VERSION "created by canmatrix"

NS_ :

BS_:

BU_: XCP_Tester FRS MN_K77

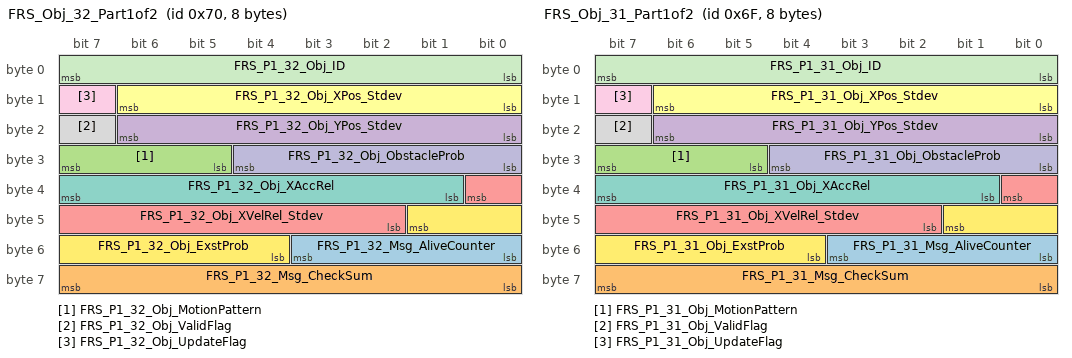
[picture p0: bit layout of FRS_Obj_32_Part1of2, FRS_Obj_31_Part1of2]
BO_ 112 FRS_Obj_32_Part1of2: 8 FRS
 SG_ FRS_P1_32_Msg_AliveCounter : 51|4@0+ (1,0) [0|15] "n/a" Vector__XXX
 SG_ FRS_P1_32_Msg_CheckSum : 63|8@0+ (1,0) [0|255] "n/a" Vector__XXX
 SG_ FRS_P1_32_Obj_MotionPattern : 31|3@0+ (1,0) [0|7] "n/a" Vector__XXX
 SG_ FRS_P1_32_Obj_YPos_Stdev : 22|7@0+ (0.1,0) [0|12.7] "m" Vector__XXX
 SG_ FRS_P1_32_Obj_XVelRel_Stdev : 32|7@0+ (0.05,0) [0|6.35] "m/s" Vector__XXX
 SG_ FRS_P1_32_Obj_XPos_Stdev : 14|7@0+ (0.1,0) [0|12.7] "m" Vector__XXX
 SG_ FRS_P1_32_Obj_XAccRel : 39|7@0+ (0.15,-9.6) [-9.6|9.45] "m/s2" Vector__XXX
 SG_ FRS_P1_32_Obj_ValidFlag : 23|1@0+ (1,0) [0|1] "n/a" Vector__XXX
 SG_ FRS_P1_32_Obj_UpdateFlag : 15|1@0+ (1,0) [0|1] "n/a" Vector__XXX
 SG_ FRS_P1_32_Obj_ObstacleProb : 28|5@0+ (3.2258,0) [0|99.9998] "%" Vector__XXX
 SG_ FRS_P1_32_Obj_ID : 7|8@0+ (1,0) [0|255] "n/a" Vector__XXX
 SG_ FRS_P1_32_Obj_ExstProb : 41|6@0+ (1.5873,0) [0|99.9999] "%" Vector__XXX

BO_ 111 FRS_Obj_31_Part1of2: 8 FRS
 SG_ FRS_P1_31_Msg_AliveCounter : 51|4@0+ (1,0) [0|15] "n/a" Vector__XXX
 SG_ FRS_P1_31_Msg_CheckSum : 63|8@0+ (1,0) [0|255] "n/a" Vector__XXX
 SG_ FRS_P1_31_Obj_MotionPattern : 31|3@0+ (1,0) [0|7] "n/a" Vector__XXX
 SG_ FRS_P1_31_Obj_YPos_Stdev : 22|7@0+ (0.1,0) [0|12.7] "m" Vector__XXX
 SG_ FRS_P1_31_Obj_XVelRel_Stdev : 32|7@0+ (0.05,0) [0|6.35] "m/s" Vector__XXX
 SG_ FRS_P1_31_Obj_XPos_Stdev : 14|7@0+ (0.1,0) [0|12.7] "m" Vector__XXX
 SG_ FRS_P1_31_Obj_XAccRel : 39|7@0+ (0.15,-9.6) [-9.6|9.45] "m/s2" Vector__XXX
 SG_ FRS_P1_31_Obj_ValidFlag : 23|1@0+ (1,0) [0|1] "n/a" Vector__XXX
 SG_ FRS_P1_31_Obj_UpdateFlag : 15|1@0+ (1,0) [0|1] "n/a" Vector__XXX
 SG_ FRS_P1_31_Obj_ObstacleProb : 28|5@0+ (3.2258,0) [0|99.9998] "%" Vector__XXX
 SG_ FRS_P1_31_Obj_ID : 7|8@0+ (1,0) [0|255] "n/a" Vector__XXX
 SG_ FRS_P1_31_Obj_ExstProb : 41|6@0+ (1.5873,0) [0|99.9999] "%" Vector__XXX

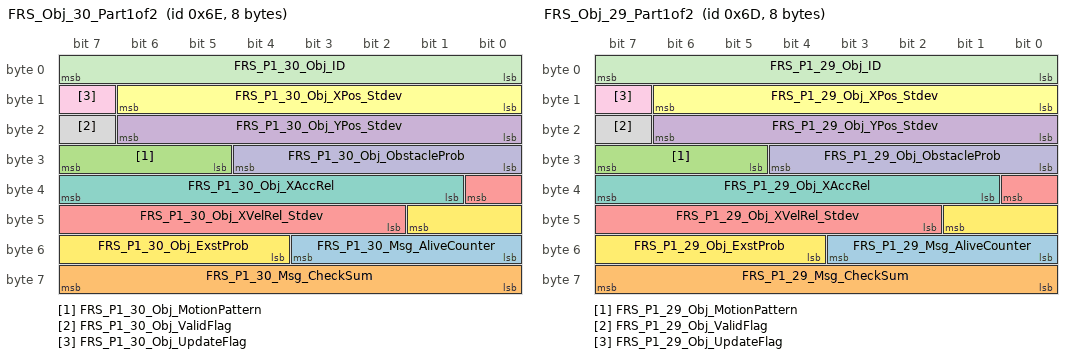
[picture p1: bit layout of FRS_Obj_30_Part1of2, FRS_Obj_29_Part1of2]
BO_ 110 FRS_Obj_30_Part1of2: 8 FRS
 SG_ FRS_P1_30_Msg_AliveCounter : 51|4@0+ (1,0) [0|15] "n/a" Vector__XXX
 SG_ FRS_P1_30_Msg_CheckSum : 63|8@0+ (1,0) [0|255] "n/a" Vector__XXX
 SG_ FRS_P1_30_Obj_MotionPattern : 31|3@0+ (1,0) [0|7] "n/a" Vector__XXX
 SG_ FRS_P1_30_Obj_YPos_Stdev : 22|7@0+ (0.1,0) [0|12.7] "m" Vector__XXX
 SG_ FRS_P1_30_Obj_XVelRel_Stdev : 32|7@0+ (0.05,0) [0|6.35] "m/s" Vector__XXX
 SG_ FRS_P1_30_Obj_XPos_Stdev : 14|7@0+ (0.1,0) [0|12.7] "m" Vector__XXX
 SG_ FRS_P1_30_Obj_XAccRel : 39|7@0+ (0.15,-9.6) [-9.6|9.45] "m/s2" Vector__XXX
 SG_ FRS_P1_30_Obj_ValidFlag : 23|1@0+ (1,0) [0|1] "n/a" Vector__XXX
 SG_ FRS_P1_30_Obj_UpdateFlag : 15|1@0+ (1,0) [0|1] "n/a" Vector__XXX
 SG_ FRS_P1_30_Obj_ObstacleProb : 28|5@0+ (3.2258,0) [0|99.9998] "%" Vector__XXX
 SG_ FRS_P1_30_Obj_ID : 7|8@0+ (1,0) [0|255] "n/a" Vector__XXX
 SG_ FRS_P1_30_Obj_ExstProb : 41|6@0+ (1.5873,0) [0|99.9999] "%" Vector__XXX

BO_ 109 FRS_Obj_29_Part1of2: 8 FRS
 SG_ FRS_P1_29_Msg_AliveCounter : 51|4@0+ (1,0) [0|15] "n/a" Vector__XXX
 SG_ FRS_P1_29_Msg_CheckSum : 63|8@0+ (1,0) [0|255] "n/a" Vector__XXX
 SG_ FRS_P1_29_Obj_MotionPattern : 31|3@0+ (1,0) [0|7] "n/a" Vector__XXX
 SG_ FRS_P1_29_Obj_YPos_Stdev : 22|7@0+ (0.1,0) [0|12.7] "m" Vector__XXX
 SG_ FRS_P1_29_Obj_XVelRel_Stdev : 32|7@0+ (0.05,0) [0|6.35] "m/s" Vector__XXX
 SG_ FRS_P1_29_Obj_XPos_Stdev : 14|7@0+ (0.1,0) [0|12.7] "m" Vector__XXX
 SG_ FRS_P1_29_Obj_XAccRel : 39|7@0+ (0.15,-9.6) [-9.6|9.45] "m/s2" Vector__XXX
 SG_ FRS_P1_29_Obj_ValidFlag : 23|1@0+ (1,0) [0|1] "n/a" Vector__XXX
 SG_ FRS_P1_29_Obj_UpdateFlag : 15|1@0+ (1,0) [0|1] "n/a" Vector__XXX
 SG_ FRS_P1_29_Obj_ObstacleProb : 28|5@0+ (3.2258,0) [0|99.9998] "%" Vector__XXX
 SG_ FRS_P1_29_Obj_ID : 7|8@0+ (1,0) [0|255] "n/a" Vector__XXX
 SG_ FRS_P1_29_Obj_ExstProb : 41|6@0+ (1.5873,0) [0|99.9999] "%" Vector__XXX

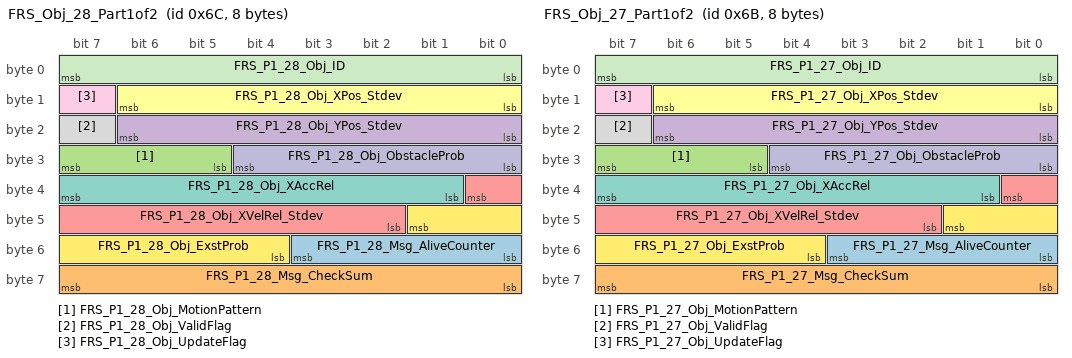
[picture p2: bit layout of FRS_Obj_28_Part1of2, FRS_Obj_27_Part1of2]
BO_ 108 FRS_Obj_28_Part1of2: 8 FRS
 SG_ FRS_P1_28_Msg_AliveCounter : 51|4@0+ (1,0) [0|15] "n/a" Vector__XXX
 SG_ FRS_P1_28_Msg_CheckSum : 63|8@0+ (1,0) [0|255] "n/a" Vector__XXX
 SG_ FRS_P1_28_Obj_MotionPattern : 31|3@0+ (1,0) [0|7] "n/a" Vector__XXX
 SG_ FRS_P1_28_Obj_YPos_Stdev : 22|7@0+ (0.1,0) [0|12.7] "m" Vector__XXX
 SG_ FRS_P1_28_Obj_XVelRel_Stdev : 32|7@0+ (0.05,0) [0|6.35] "m/s" Vector__XXX
 SG_ FRS_P1_28_Obj_XPos_Stdev : 14|7@0+ (0.1,0) [0|12.7] "m" Vector__XXX
 SG_ FRS_P1_28_Obj_XAccRel : 39|7@0+ (0.15,-9.6) [-9.6|9.45] "m/s2" Vector__XXX
 SG_ FRS_P1_28_Obj_ValidFlag : 23|1@0+ (1,0) [0|1] "n/a" Vector__XXX
 SG_ FRS_P1_28_Obj_UpdateFlag : 15|1@0+ (1,0) [0|1] "n/a" Vector__XXX
 SG_ FRS_P1_28_Obj_ObstacleProb : 28|5@0+ (3.2258,0) [0|99.9998] "%" Vector__XXX
 SG_ FRS_P1_28_Obj_ID : 7|8@0+ (1,0) [0|255] "n/a" Vector__XXX
 SG_ FRS_P1_28_Obj_ExstProb : 41|6@0+ (1.5873,0) [0|99.9999] "%" Vector__XXX

BO_ 107 FRS_Obj_27_Part1of2: 8 FRS
 SG_ FRS_P1_27_Msg_AliveCounter : 51|4@0+ (1,0) [0|15] "n/a" Vector__XXX
 SG_ FRS_P1_27_Msg_CheckSum : 63|8@0+ (1,0) [0|255] "n/a" Vector__XXX
 SG_ FRS_P1_27_Obj_MotionPattern : 31|3@0+ (1,0) [0|7] "n/a" Vector__XXX
 SG_ FRS_P1_27_Obj_YPos_Stdev : 22|7@0+ (0.1,0) [0|12.7] "m" Vector__XXX
 SG_ FRS_P1_27_Obj_XVelRel_Stdev : 32|7@0+ (0.05,0) [0|6.35] "m/s" Vector__XXX
 SG_ FRS_P1_27_Obj_XPos_Stdev : 14|7@0+ (0.1,0) [0|12.7] "m" Vector__XXX
 SG_ FRS_P1_27_Obj_XAccRel : 39|7@0+ (0.15,-9.6) [-9.6|9.45] "m/s2" Vector__XXX
 SG_ FRS_P1_27_Obj_ValidFlag : 23|1@0+ (1,0) [0|1] "n/a" Vector__XXX
 SG_ FRS_P1_27_Obj_UpdateFlag : 15|1@0+ (1,0) [0|1] "n/a" Vector__XXX
 SG_ FRS_P1_27_Obj_ObstacleProb : 28|5@0+ (3.2258,0) [0|99.9998] "%" Vector__XXX
 SG_ FRS_P1_27_Obj_ID : 7|8@0+ (1,0) [0|255] "n/a" Vector__XXX
 SG_ FRS_P1_27_Obj_ExstProb : 41|6@0+ (1.5873,0) [0|99.9999] "%" Vector__XXX

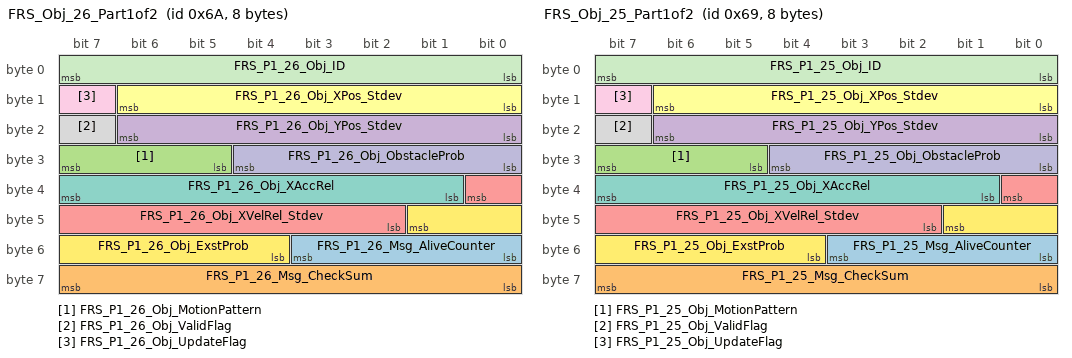
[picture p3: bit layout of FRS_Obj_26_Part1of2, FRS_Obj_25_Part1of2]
BO_ 106 FRS_Obj_26_Part1of2: 8 FRS
 SG_ FRS_P1_26_Msg_AliveCounter : 51|4@0+ (1,0) [0|15] "n/a" Vector__XXX
 SG_ FRS_P1_26_Msg_CheckSum : 63|8@0+ (1,0) [0|255] "n/a" Vector__XXX
 SG_ FRS_P1_26_Obj_MotionPattern : 31|3@0+ (1,0) [0|7] "n/a" Vector__XXX
 SG_ FRS_P1_26_Obj_YPos_Stdev : 22|7@0+ (0.1,0) [0|12.7] "m" Vector__XXX
 SG_ FRS_P1_26_Obj_XVelRel_Stdev : 32|7@0+ (0.05,0) [0|6.35] "m/s" Vector__XXX
 SG_ FRS_P1_26_Obj_XPos_Stdev : 14|7@0+ (0.1,0) [0|12.7] "m" Vector__XXX
 SG_ FRS_P1_26_Obj_XAccRel : 39|7@0+ (0.15,-9.6) [-9.6|9.45] "m/s2" Vector__XXX
 SG_ FRS_P1_26_Obj_ValidFlag : 23|1@0+ (1,0) [0|1] "n/a" Vector__XXX
 SG_ FRS_P1_26_Obj_UpdateFlag : 15|1@0+ (1,0) [0|1] "n/a" Vector__XXX
 SG_ FRS_P1_26_Obj_ObstacleProb : 28|5@0+ (3.2258,0) [0|99.9998] "%" Vector__XXX
 SG_ FRS_P1_26_Obj_ID : 7|8@0+ (1,0) [0|255] "n/a" Vector__XXX
 SG_ FRS_P1_26_Obj_ExstProb : 41|6@0+ (1.5873,0) [0|99.9999] "%" Vector__XXX

BO_ 105 FRS_Obj_25_Part1of2: 8 FRS
 SG_ FRS_P1_25_Msg_AliveCounter : 51|4@0+ (1,0) [0|15] "n/a" Vector__XXX
 SG_ FRS_P1_25_Msg_CheckSum : 63|8@0+ (1,0) [0|255] "n/a" Vector__XXX
 SG_ FRS_P1_25_Obj_MotionPattern : 31|3@0+ (1,0) [0|7] "n/a" Vector__XXX
 SG_ FRS_P1_25_Obj_YPos_Stdev : 22|7@0+ (0.1,0) [0|12.7] "m" Vector__XXX
 SG_ FRS_P1_25_Obj_XVelRel_Stdev : 32|7@0+ (0.05,0) [0|6.35] "m/s" Vector__XXX
 SG_ FRS_P1_25_Obj_XPos_Stdev : 14|7@0+ (0.1,0) [0|12.7] "m" Vector__XXX
 SG_ FRS_P1_25_Obj_XAccRel : 39|7@0+ (0.15,-9.6) [-9.6|9.45] "m/s2" Vector__XXX
 SG_ FRS_P1_25_Obj_ValidFlag : 23|1@0+ (1,0) [0|1] "n/a" Vector__XXX
 SG_ FRS_P1_25_Obj_UpdateFlag : 15|1@0+ (1,0) [0|1] "n/a" Vector__XXX
 SG_ FRS_P1_25_Obj_ObstacleProb : 28|5@0+ (3.2258,0) [0|99.9998] "%" Vector__XXX
 SG_ FRS_P1_25_Obj_ID : 7|8@0+ (1,0) [0|255] "n/a" Vector__XXX
 SG_ FRS_P1_25_Obj_ExstProb : 41|6@0+ (1.5873,0) [0|99.9999] "%" Vector__XXX

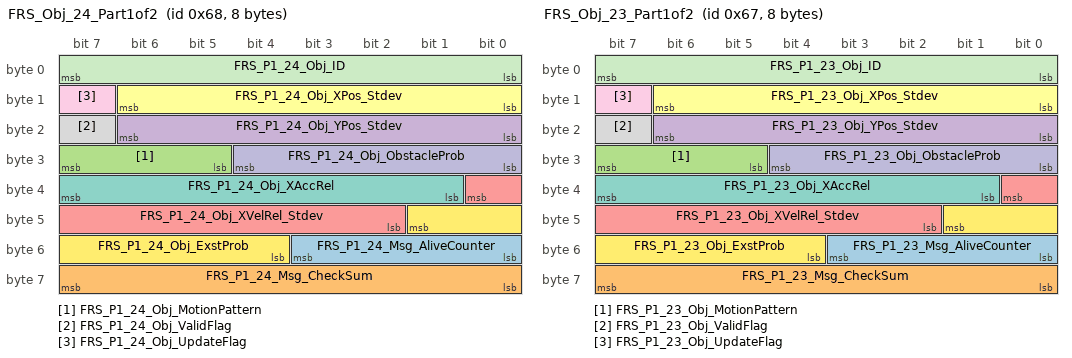
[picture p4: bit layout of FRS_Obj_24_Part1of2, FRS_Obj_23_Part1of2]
BO_ 104 FRS_Obj_24_Part1of2: 8 FRS
 SG_ FRS_P1_24_Msg_AliveCounter : 51|4@0+ (1,0) [0|15] "n/a" Vector__XXX
 SG_ FRS_P1_24_Msg_CheckSum : 63|8@0+ (1,0) [0|255] "n/a" Vector__XXX
 SG_ FRS_P1_24_Obj_MotionPattern : 31|3@0+ (1,0) [0|7] "n/a" Vector__XXX
 SG_ FRS_P1_24_Obj_YPos_Stdev : 22|7@0+ (0.1,0) [0|12.7] "m" Vector__XXX
 SG_ FRS_P1_24_Obj_XVelRel_Stdev : 32|7@0+ (0.05,0) [0|6.35] "m/s" Vector__XXX
 SG_ FRS_P1_24_Obj_XPos_Stdev : 14|7@0+ (0.1,0) [0|12.7] "m" Vector__XXX
 SG_ FRS_P1_24_Obj_XAccRel : 39|7@0+ (0.15,-9.6) [-9.6|9.45] "m/s2" Vector__XXX
 SG_ FRS_P1_24_Obj_ValidFlag : 23|1@0+ (1,0) [0|1] "n/a" Vector__XXX
 SG_ FRS_P1_24_Obj_UpdateFlag : 15|1@0+ (1,0) [0|1] "n/a" Vector__XXX
 SG_ FRS_P1_24_Obj_ObstacleProb : 28|5@0+ (3.2258,0) [0|99.9998] "%" Vector__XXX
 SG_ FRS_P1_24_Obj_ID : 7|8@0+ (1,0) [0|255] "n/a" Vector__XXX
 SG_ FRS_P1_24_Obj_ExstProb : 41|6@0+ (1.5873,0) [0|99.9999] "%" Vector__XXX

BO_ 103 FRS_Obj_23_Part1of2: 8 FRS
 SG_ FRS_P1_23_Msg_AliveCounter : 51|4@0+ (1,0) [0|15] "n/a" Vector__XXX
 SG_ FRS_P1_23_Msg_CheckSum : 63|8@0+ (1,0) [0|255] "n/a" Vector__XXX
 SG_ FRS_P1_23_Obj_MotionPattern : 31|3@0+ (1,0) [0|7] "n/a" Vector__XXX
 SG_ FRS_P1_23_Obj_YPos_Stdev : 22|7@0+ (0.1,0) [0|12.7] "m" Vector__XXX
 SG_ FRS_P1_23_Obj_XVelRel_Stdev : 32|7@0+ (0.05,0) [0|6.35] "m/s" Vector__XXX
 SG_ FRS_P1_23_Obj_XPos_Stdev : 14|7@0+ (0.1,0) [0|12.7] "m" Vector__XXX
 SG_ FRS_P1_23_Obj_XAccRel : 39|7@0+ (0.15,-9.6) [-9.6|9.45] "m/s2" Vector__XXX
 SG_ FRS_P1_23_Obj_ValidFlag : 23|1@0+ (1,0) [0|1] "n/a" Vector__XXX
 SG_ FRS_P1_23_Obj_UpdateFlag : 15|1@0+ (1,0) [0|1] "n/a" Vector__XXX
 SG_ FRS_P1_23_Obj_ObstacleProb : 28|5@0+ (3.2258,0) [0|99.9998] "%" Vector__XXX
 SG_ FRS_P1_23_Obj_ID : 7|8@0+ (1,0) [0|255] "n/a" Vector__XXX
 SG_ FRS_P1_23_Obj_ExstProb : 41|6@0+ (1.5873,0) [0|99.9999] "%" Vector__XXX

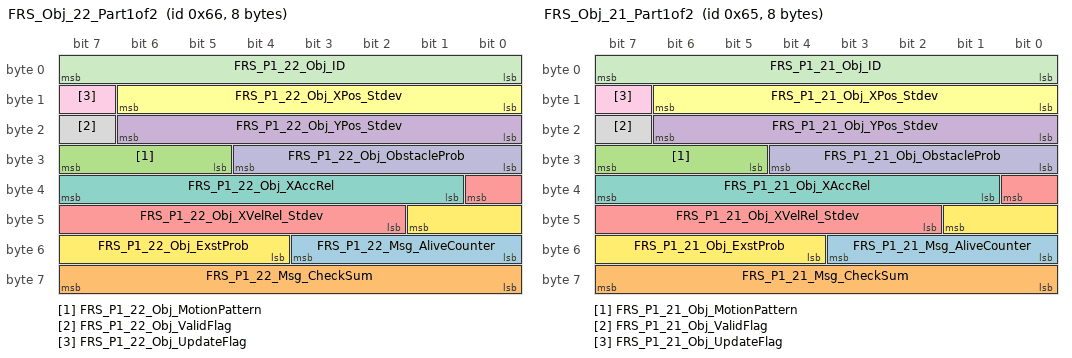
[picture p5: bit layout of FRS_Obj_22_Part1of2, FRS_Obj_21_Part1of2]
BO_ 102 FRS_Obj_22_Part1of2: 8 FRS
 SG_ FRS_P1_22_Msg_AliveCounter : 51|4@0+ (1,0) [0|15] "n/a" Vector__XXX
 SG_ FRS_P1_22_Msg_CheckSum : 63|8@0+ (1,0) [0|255] "n/a" Vector__XXX
 SG_ FRS_P1_22_Obj_MotionPattern : 31|3@0+ (1,0) [0|7] "n/a" Vector__XXX
 SG_ FRS_P1_22_Obj_YPos_Stdev : 22|7@0+ (0.1,0) [0|12.7] "m" Vector__XXX
 SG_ FRS_P1_22_Obj_XVelRel_Stdev : 32|7@0+ (0.05,0) [0|6.35] "m/s" Vector__XXX
 SG_ FRS_P1_22_Obj_XPos_Stdev : 14|7@0+ (0.1,0) [0|12.7] "m" Vector__XXX
 SG_ FRS_P1_22_Obj_XAccRel : 39|7@0+ (0.15,-9.6) [-9.6|9.45] "m/s2" Vector__XXX
 SG_ FRS_P1_22_Obj_ValidFlag : 23|1@0+ (1,0) [0|1] "n/a" Vector__XXX
 SG_ FRS_P1_22_Obj_UpdateFlag : 15|1@0+ (1,0) [0|1] "n/a" Vector__XXX
 SG_ FRS_P1_22_Obj_ObstacleProb : 28|5@0+ (3.2258,0) [0|99.9998] "%" Vector__XXX
 SG_ FRS_P1_22_Obj_ID : 7|8@0+ (1,0) [0|255] "n/a" Vector__XXX
 SG_ FRS_P1_22_Obj_ExstProb : 41|6@0+ (1.5873,0) [0|99.9999] "%" Vector__XXX

BO_ 101 FRS_Obj_21_Part1of2: 8 FRS
 SG_ FRS_P1_21_Msg_AliveCounter : 51|4@0+ (1,0) [0|15] "n/a" Vector__XXX
 SG_ FRS_P1_21_Msg_CheckSum : 63|8@0+ (1,0) [0|255] "n/a" Vector__XXX
 SG_ FRS_P1_21_Obj_MotionPattern : 31|3@0+ (1,0) [0|7] "n/a" Vector__XXX
 SG_ FRS_P1_21_Obj_YPos_Stdev : 22|7@0+ (0.1,0) [0|12.7] "m" Vector__XXX
 SG_ FRS_P1_21_Obj_XVelRel_Stdev : 32|7@0+ (0.05,0) [0|6.35] "m/s" Vector__XXX
 SG_ FRS_P1_21_Obj_XPos_Stdev : 14|7@0+ (0.1,0) [0|12.7] "m" Vector__XXX
 SG_ FRS_P1_21_Obj_XAccRel : 39|7@0+ (0.15,-9.6) [-9.6|9.45] "m/s2" Vector__XXX
 SG_ FRS_P1_21_Obj_ValidFlag : 23|1@0+ (1,0) [0|1] "n/a" Vector__XXX
 SG_ FRS_P1_21_Obj_UpdateFlag : 15|1@0+ (1,0) [0|1] "n/a" Vector__XXX
 SG_ FRS_P1_21_Obj_ObstacleProb : 28|5@0+ (3.2258,0) [0|99.9998] "%" Vector__XXX
 SG_ FRS_P1_21_Obj_ID : 7|8@0+ (1,0) [0|255] "n/a" Vector__XXX
 SG_ FRS_P1_21_Obj_ExstProb : 41|6@0+ (1.5873,0) [0|99.9999] "%" Vector__XXX

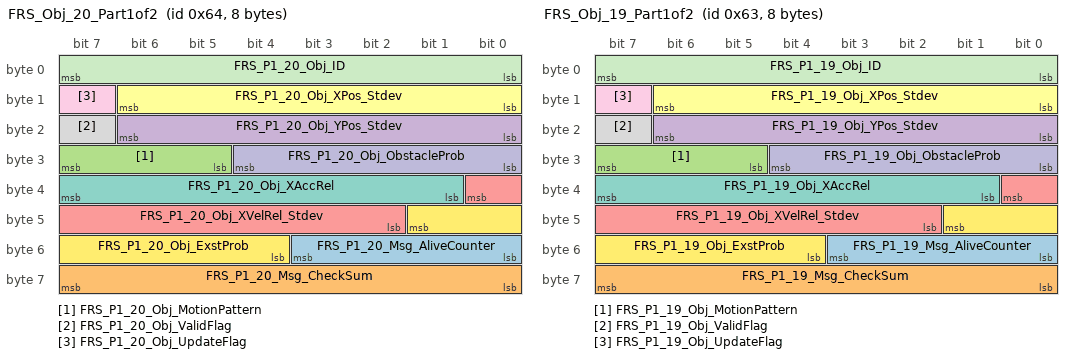
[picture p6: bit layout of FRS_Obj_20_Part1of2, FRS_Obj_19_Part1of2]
BO_ 100 FRS_Obj_20_Part1of2: 8 FRS
 SG_ FRS_P1_20_Msg_AliveCounter : 51|4@0+ (1,0) [0|15] "n/a" Vector__XXX
 SG_ FRS_P1_20_Msg_CheckSum : 63|8@0+ (1,0) [0|255] "n/a" Vector__XXX
 SG_ FRS_P1_20_Obj_MotionPattern : 31|3@0+ (1,0) [0|7] "n/a" Vector__XXX
 SG_ FRS_P1_20_Obj_YPos_Stdev : 22|7@0+ (0.1,0) [0|12.7] "m" Vector__XXX
 SG_ FRS_P1_20_Obj_XVelRel_Stdev : 32|7@0+ (0.05,0) [0|6.35] "m/s" Vector__XXX
 SG_ FRS_P1_20_Obj_XPos_Stdev : 14|7@0+ (0.1,0) [0|12.7] "m" Vector__XXX
 SG_ FRS_P1_20_Obj_XAccRel : 39|7@0+ (0.15,-9.6) [-9.6|9.45] "m/s2" Vector__XXX
 SG_ FRS_P1_20_Obj_ValidFlag : 23|1@0+ (1,0) [0|1] "n/a" Vector__XXX
 SG_ FRS_P1_20_Obj_UpdateFlag : 15|1@0+ (1,0) [0|1] "n/a" Vector__XXX
 SG_ FRS_P1_20_Obj_ObstacleProb : 28|5@0+ (3.2258,0) [0|99.9998] "%" Vector__XXX
 SG_ FRS_P1_20_Obj_ID : 7|8@0+ (1,0) [0|255] "n/a" Vector__XXX
 SG_ FRS_P1_20_Obj_ExstProb : 41|6@0+ (1.5873,0) [0|99.9999] "%" Vector__XXX

BO_ 99 FRS_Obj_19_Part1of2: 8 FRS
 SG_ FRS_P1_19_Msg_AliveCounter : 51|4@0+ (1,0) [0|15] "n/a" Vector__XXX
 SG_ FRS_P1_19_Msg_CheckSum : 63|8@0+ (1,0) [0|255] "n/a" Vector__XXX
 SG_ FRS_P1_19_Obj_MotionPattern : 31|3@0+ (1,0) [0|7] "n/a" Vector__XXX
 SG_ FRS_P1_19_Obj_YPos_Stdev : 22|7@0+ (0.1,0) [0|12.7] "m" Vector__XXX
 SG_ FRS_P1_19_Obj_XVelRel_Stdev : 32|7@0+ (0.05,0) [0|6.35] "m/s" Vector__XXX
 SG_ FRS_P1_19_Obj_XPos_Stdev : 14|7@0+ (0.1,0) [0|12.7] "m" Vector__XXX
 SG_ FRS_P1_19_Obj_XAccRel : 39|7@0+ (0.15,-9.6) [-9.6|9.45] "m/s2" Vector__XXX
 SG_ FRS_P1_19_Obj_ValidFlag : 23|1@0+ (1,0) [0|1] "n/a" Vector__XXX
 SG_ FRS_P1_19_Obj_UpdateFlag : 15|1@0+ (1,0) [0|1] "n/a" Vector__XXX
 SG_ FRS_P1_19_Obj_ObstacleProb : 28|5@0+ (3.2258,0) [0|99.9998] "%" Vector__XXX
 SG_ FRS_P1_19_Obj_ID : 7|8@0+ (1,0) [0|255] "n/a" Vector__XXX
 SG_ FRS_P1_19_Obj_ExstProb : 41|6@0+ (1.5873,0) [0|99.9999] "%" Vector__XXX

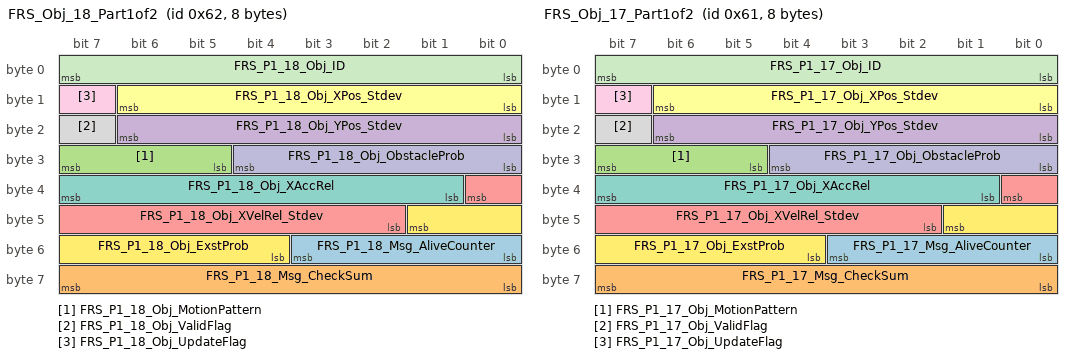
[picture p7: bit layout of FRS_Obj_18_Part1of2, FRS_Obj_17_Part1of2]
BO_ 98 FRS_Obj_18_Part1of2: 8 FRS
 SG_ FRS_P1_18_Msg_AliveCounter : 51|4@0+ (1,0) [0|15] "n/a" Vector__XXX
 SG_ FRS_P1_18_Msg_CheckSum : 63|8@0+ (1,0) [0|255] "n/a" Vector__XXX
 SG_ FRS_P1_18_Obj_MotionPattern : 31|3@0+ (1,0) [0|7] "n/a" Vector__XXX
 SG_ FRS_P1_18_Obj_YPos_Stdev : 22|7@0+ (0.1,0) [0|12.7] "m" Vector__XXX
 SG_ FRS_P1_18_Obj_XVelRel_Stdev : 32|7@0+ (0.05,0) [0|6.35] "m/s" Vector__XXX
 SG_ FRS_P1_18_Obj_XPos_Stdev : 14|7@0+ (0.1,0) [0|12.7] "m" Vector__XXX
 SG_ FRS_P1_18_Obj_XAccRel : 39|7@0+ (0.15,-9.6) [-9.6|9.45] "m/s2" Vector__XXX
 SG_ FRS_P1_18_Obj_ValidFlag : 23|1@0+ (1,0) [0|1] "n/a" Vector__XXX
 SG_ FRS_P1_18_Obj_UpdateFlag : 15|1@0+ (1,0) [0|1] "n/a" Vector__XXX
 SG_ FRS_P1_18_Obj_ObstacleProb : 28|5@0+ (3.2258,0) [0|99.9998] "%" Vector__XXX
 SG_ FRS_P1_18_Obj_ID : 7|8@0+ (1,0) [0|255] "n/a" Vector__XXX
 SG_ FRS_P1_18_Obj_ExstProb : 41|6@0+ (1.5873,0) [0|99.9999] "%" Vector__XXX

BO_ 97 FRS_Obj_17_Part1of2: 8 FRS
 SG_ FRS_P1_17_Msg_AliveCounter : 51|4@0+ (1,0) [0|15] "n/a" Vector__XXX
 SG_ FRS_P1_17_Msg_CheckSum : 63|8@0+ (1,0) [0|255] "n/a" Vector__XXX
 SG_ FRS_P1_17_Obj_MotionPattern : 31|3@0+ (1,0) [0|7] "n/a" Vector__XXX
 SG_ FRS_P1_17_Obj_YPos_Stdev : 22|7@0+ (0.1,0) [0|12.7] "m" Vector__XXX
 SG_ FRS_P1_17_Obj_XVelRel_Stdev : 32|7@0+ (0.05,0) [0|6.35] "m/s" Vector__XXX
 SG_ FRS_P1_17_Obj_XPos_Stdev : 14|7@0+ (0.1,0) [0|12.7] "m" Vector__XXX
 SG_ FRS_P1_17_Obj_XAccRel : 39|7@0+ (0.15,-9.6) [-9.6|9.45] "m/s2" Vector__XXX
 SG_ FRS_P1_17_Obj_ValidFlag : 23|1@0+ (1,0) [0|1] "n/a" Vector__XXX
 SG_ FRS_P1_17_Obj_UpdateFlag : 15|1@0+ (1,0) [0|1] "n/a" Vector__XXX
 SG_ FRS_P1_17_Obj_ObstacleProb : 28|5@0+ (3.2258,0) [0|99.9998] "%" Vector__XXX
 SG_ FRS_P1_17_Obj_ID : 7|8@0+ (1,0) [0|255] "n/a" Vector__XXX
 SG_ FRS_P1_17_Obj_ExstProb : 41|6@0+ (1.5873,0) [0|99.9999] "%" Vector__XXX

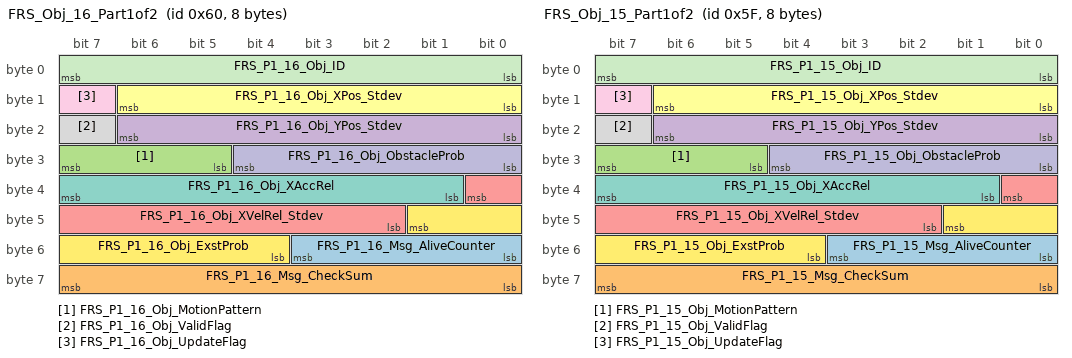
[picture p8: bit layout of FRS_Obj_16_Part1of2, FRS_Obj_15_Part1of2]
BO_ 96 FRS_Obj_16_Part1of2: 8 FRS
 SG_ FRS_P1_16_Msg_AliveCounter : 51|4@0+ (1,0) [0|15] "n/a" Vector__XXX
 SG_ FRS_P1_16_Msg_CheckSum : 63|8@0+ (1,0) [0|255] "n/a" Vector__XXX
 SG_ FRS_P1_16_Obj_MotionPattern : 31|3@0+ (1,0) [0|7] "n/a" Vector__XXX
 SG_ FRS_P1_16_Obj_YPos_Stdev : 22|7@0+ (0.1,0) [0|12.7] "m" Vector__XXX
 SG_ FRS_P1_16_Obj_XVelRel_Stdev : 32|7@0+ (0.05,0) [0|6.35] "m/s" Vector__XXX
 SG_ FRS_P1_16_Obj_XPos_Stdev : 14|7@0+ (0.1,0) [0|12.7] "m" Vector__XXX
 SG_ FRS_P1_16_Obj_XAccRel : 39|7@0+ (0.15,-9.6) [-9.6|9.45] "m/s2" Vector__XXX
 SG_ FRS_P1_16_Obj_ValidFlag : 23|1@0+ (1,0) [0|1] "n/a" Vector__XXX
 SG_ FRS_P1_16_Obj_UpdateFlag : 15|1@0+ (1,0) [0|1] "n/a" Vector__XXX
 SG_ FRS_P1_16_Obj_ObstacleProb : 28|5@0+ (3.2258,0) [0|99.9998] "%" Vector__XXX
 SG_ FRS_P1_16_Obj_ID : 7|8@0+ (1,0) [0|255] "n/a" Vector__XXX
 SG_ FRS_P1_16_Obj_ExstProb : 41|6@0+ (1.5873,0) [0|99.9999] "%" Vector__XXX

BO_ 95 FRS_Obj_15_Part1of2: 8 FRS
 SG_ FRS_P1_15_Msg_AliveCounter : 51|4@0+ (1,0) [0|15] "n/a" Vector__XXX
 SG_ FRS_P1_15_Msg_CheckSum : 63|8@0+ (1,0) [0|255] "n/a" Vector__XXX
 SG_ FRS_P1_15_Obj_MotionPattern : 31|3@0+ (1,0) [0|7] "n/a" Vector__XXX
 SG_ FRS_P1_15_Obj_YPos_Stdev : 22|7@0+ (0.1,0) [0|12.7] "m" Vector__XXX
 SG_ FRS_P1_15_Obj_XVelRel_Stdev : 32|7@0+ (0.05,0) [0|6.35] "m/s" Vector__XXX
 SG_ FRS_P1_15_Obj_XPos_Stdev : 14|7@0+ (0.1,0) [0|12.7] "m" Vector__XXX
 SG_ FRS_P1_15_Obj_XAccRel : 39|7@0+ (0.15,-9.6) [-9.6|9.45] "m/s2" Vector__XXX
 SG_ FRS_P1_15_Obj_ValidFlag : 23|1@0+ (1,0) [0|1] "n/a" Vector__XXX
 SG_ FRS_P1_15_Obj_UpdateFlag : 15|1@0+ (1,0) [0|1] "n/a" Vector__XXX
 SG_ FRS_P1_15_Obj_ObstacleProb : 28|5@0+ (3.2258,0) [0|99.9998] "%" Vector__XXX
 SG_ FRS_P1_15_Obj_ID : 7|8@0+ (1,0) [0|255] "n/a" Vector__XXX
 SG_ FRS_P1_15_Obj_ExstProb : 41|6@0+ (1.5873,0) [0|99.9999] "%" Vector__XXX

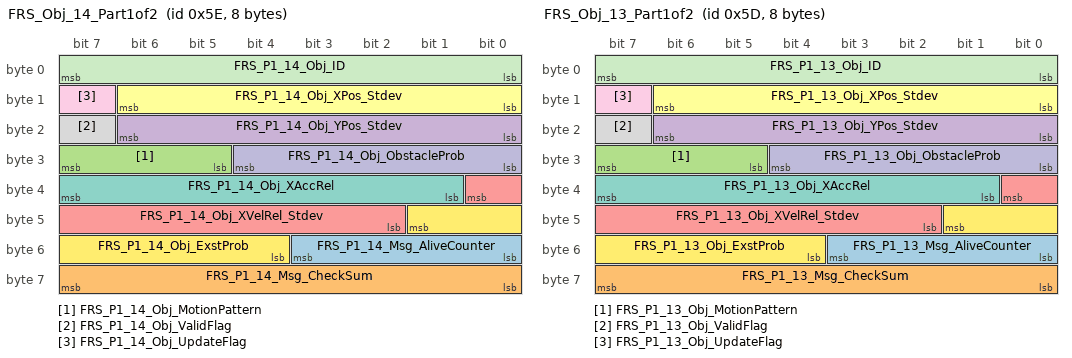
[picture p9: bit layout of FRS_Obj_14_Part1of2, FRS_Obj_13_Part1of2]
BO_ 94 FRS_Obj_14_Part1of2: 8 FRS
 SG_ FRS_P1_14_Msg_AliveCounter : 51|4@0+ (1,0) [0|15] "n/a" Vector__XXX
 SG_ FRS_P1_14_Msg_CheckSum : 63|8@0+ (1,0) [0|255] "n/a" Vector__XXX
 SG_ FRS_P1_14_Obj_MotionPattern : 31|3@0+ (1,0) [0|7] "n/a" Vector__XXX
 SG_ FRS_P1_14_Obj_YPos_Stdev : 22|7@0+ (0.1,0) [0|12.7] "m" Vector__XXX
 SG_ FRS_P1_14_Obj_XVelRel_Stdev : 32|7@0+ (0.05,0) [0|6.35] "m/s" Vector__XXX
 SG_ FRS_P1_14_Obj_XPos_Stdev : 14|7@0+ (0.1,0) [0|12.7] "m" Vector__XXX
 SG_ FRS_P1_14_Obj_XAccRel : 39|7@0+ (0.15,-9.6) [-9.6|9.45] "m/s2" Vector__XXX
 SG_ FRS_P1_14_Obj_ValidFlag : 23|1@0+ (1,0) [0|1] "n/a" Vector__XXX
 SG_ FRS_P1_14_Obj_UpdateFlag : 15|1@0+ (1,0) [0|1] "n/a" Vector__XXX
 SG_ FRS_P1_14_Obj_ObstacleProb : 28|5@0+ (3.2258,0) [0|99.9998] "%" Vector__XXX
 SG_ FRS_P1_14_Obj_ID : 7|8@0+ (1,0) [0|255] "n/a" Vector__XXX
 SG_ FRS_P1_14_Obj_ExstProb : 41|6@0+ (1.5873,0) [0|99.9999] "%" Vector__XXX

BO_ 93 FRS_Obj_13_Part1of2: 8 FRS
 SG_ FRS_P1_13_Msg_AliveCounter : 51|4@0+ (1,0) [0|15] "n/a" Vector__XXX
 SG_ FRS_P1_13_Msg_CheckSum : 63|8@0+ (1,0) [0|255] "n/a" Vector__XXX
 SG_ FRS_P1_13_Obj_MotionPattern : 31|3@0+ (1,0) [0|7] "n/a" Vector__XXX
 SG_ FRS_P1_13_Obj_YPos_Stdev : 22|7@0+ (0.1,0) [0|12.7] "m" Vector__XXX
 SG_ FRS_P1_13_Obj_XVelRel_Stdev : 32|7@0+ (0.05,0) [0|6.35] "m/s" Vector__XXX
 SG_ FRS_P1_13_Obj_XPos_Stdev : 14|7@0+ (0.1,0) [0|12.7] "m" Vector__XXX
 SG_ FRS_P1_13_Obj_XAccRel : 39|7@0+ (0.15,-9.6) [-9.6|9.45] "m/s2" Vector__XXX
 SG_ FRS_P1_13_Obj_ValidFlag : 23|1@0+ (1,0) [0|1] "n/a" Vector__XXX
 SG_ FRS_P1_13_Obj_UpdateFlag : 15|1@0+ (1,0) [0|1] "n/a" Vector__XXX
 SG_ FRS_P1_13_Obj_ObstacleProb : 28|5@0+ (3.2258,0) [0|99.9998] "%" Vector__XXX
 SG_ FRS_P1_13_Obj_ID : 7|8@0+ (1,0) [0|255] "n/a" Vector__XXX
 SG_ FRS_P1_13_Obj_ExstProb : 41|6@0+ (1.5873,0) [0|99.9999] "%" Vector__XXX

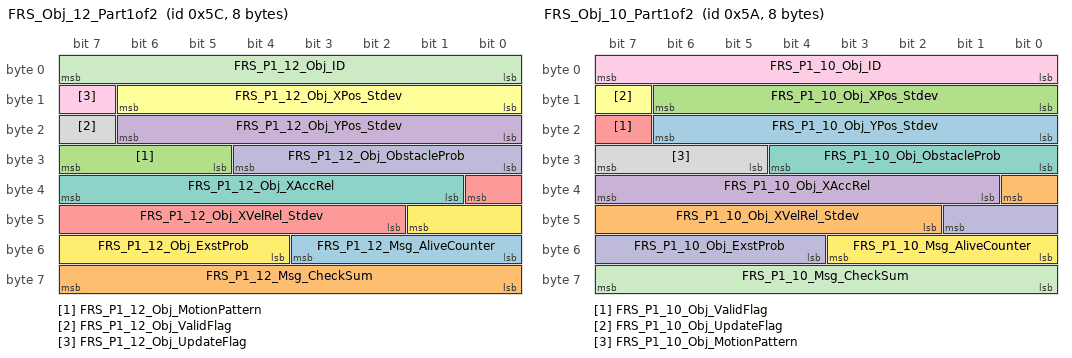
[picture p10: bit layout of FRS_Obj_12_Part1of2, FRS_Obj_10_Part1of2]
BO_ 92 FRS_Obj_12_Part1of2: 8 FRS
 SG_ FRS_P1_12_Msg_AliveCounter : 51|4@0+ (1,0) [0|15] "n/a" Vector__XXX
 SG_ FRS_P1_12_Msg_CheckSum : 63|8@0+ (1,0) [0|255] "n/a" Vector__XXX
 SG_ FRS_P1_12_Obj_MotionPattern : 31|3@0+ (1,0) [0|7] "n/a" Vector__XXX
 SG_ FRS_P1_12_Obj_YPos_Stdev : 22|7@0+ (0.1,0) [0|12.7] "m" Vector__XXX
 SG_ FRS_P1_12_Obj_XVelRel_Stdev : 32|7@0+ (0.05,0) [0|6.35] "m/s" Vector__XXX
 SG_ FRS_P1_12_Obj_XPos_Stdev : 14|7@0+ (0.1,0) [0|12.7] "m" Vector__XXX
 SG_ FRS_P1_12_Obj_XAccRel : 39|7@0+ (0.15,-9.6) [-9.6|9.45] "m/s2" Vector__XXX
 SG_ FRS_P1_12_Obj_ValidFlag : 23|1@0+ (1,0) [0|1] "n/a" Vector__XXX
 SG_ FRS_P1_12_Obj_UpdateFlag : 15|1@0+ (1,0) [0|1] "n/a" Vector__XXX
 SG_ FRS_P1_12_Obj_ObstacleProb : 28|5@0+ (3.2258,0) [0|99.9998] "%" Vector__XXX
 SG_ FRS_P1_12_Obj_ID : 7|8@0+ (1,0) [0|255] "n/a" Vector__XXX
 SG_ FRS_P1_12_Obj_ExstProb : 41|6@0+ (1.5873,0) [0|99.9999] "%" Vector__XXX

BO_ 90 FRS_Obj_10_Part1of2: 8 FRS
 SG_ FRS_P1_10_Obj_YPos_Stdev : 22|7@0+ (0.1,0) [0|12.7] "m" Vector__XXX
 SG_ FRS_P1_10_Obj_XVelRel_Stdev : 32|7@0+ (0.05,0) [0|6.35] "m/s" Vector__XXX
 SG_ FRS_P1_10_Obj_XPos_Stdev : 14|7@0+ (0.1,0) [0|12.7] "m" Vector__XXX
 SG_ FRS_P1_10_Obj_XAccRel : 39|7@0+ (0.15,-9.6) [-9.6|9.45] "m/s2" Vector__XXX
 SG_ FRS_P1_10_Obj_ValidFlag : 23|1@0+ (1,0) [0|1] "n/a" Vector__XXX
 SG_ FRS_P1_10_Obj_UpdateFlag : 15|1@0+ (1,0) [0|1] "n/a" Vector__XXX
 SG_ FRS_P1_10_Obj_ObstacleProb : 28|5@0+ (3.2258,0) [0|99.9998] "%" Vector__XXX
 SG_ FRS_P1_10_Obj_MotionPattern : 31|3@0+ (1,0) [0|7] "n/a" Vector__XXX
 SG_ FRS_P1_10_Obj_ID : 7|8@0+ (1,0) [0|255] "n/a" Vector__XXX
 SG_ FRS_P1_10_Obj_ExstProb : 41|6@0+ (1.5873,0) [0|99.9999] "%" Vector__XXX
 SG_ FRS_P1_10_Msg_CheckSum : 63|8@0+ (1,0) [0|255] "n/a" Vector__XXX
 SG_ FRS_P1_10_Msg_AliveCounter : 51|4@0+ (1,0) [0|15] "n/a" Vector__XXX

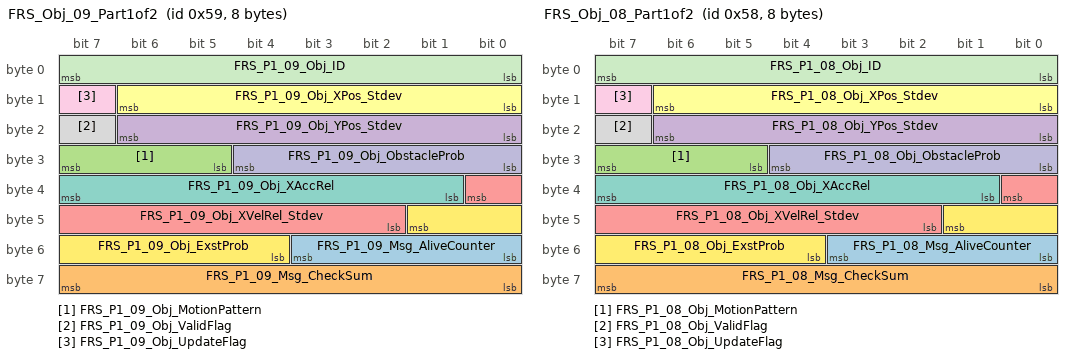
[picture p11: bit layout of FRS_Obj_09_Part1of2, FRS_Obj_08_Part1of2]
BO_ 89 FRS_Obj_09_Part1of2: 8 FRS
 SG_ FRS_P1_09_Msg_AliveCounter : 51|4@0+ (1,0) [0|15] "n/a" Vector__XXX
 SG_ FRS_P1_09_Msg_CheckSum : 63|8@0+ (1,0) [0|255] "n/a" Vector__XXX
 SG_ FRS_P1_09_Obj_MotionPattern : 31|3@0+ (1,0) [0|7] "n/a" Vector__XXX
 SG_ FRS_P1_09_Obj_YPos_Stdev : 22|7@0+ (0.1,0) [0|12.7] "m" Vector__XXX
 SG_ FRS_P1_09_Obj_XVelRel_Stdev : 32|7@0+ (0.05,0) [0|6.35] "m/s" Vector__XXX
 SG_ FRS_P1_09_Obj_XPos_Stdev : 14|7@0+ (0.1,0) [0|12.7] "m" Vector__XXX
 SG_ FRS_P1_09_Obj_XAccRel : 39|7@0+ (0.15,-9.6) [-9.6|9.45] "m/s2" Vector__XXX
 SG_ FRS_P1_09_Obj_ValidFlag : 23|1@0+ (1,0) [0|1] "n/a" Vector__XXX
 SG_ FRS_P1_09_Obj_UpdateFlag : 15|1@0+ (1,0) [0|1] "n/a" Vector__XXX
 SG_ FRS_P1_09_Obj_ObstacleProb : 28|5@0+ (3.2258,0) [0|99.9998] "%" Vector__XXX
 SG_ FRS_P1_09_Obj_ID : 7|8@0+ (1,0) [0|255] "n/a" Vector__XXX
 SG_ FRS_P1_09_Obj_ExstProb : 41|6@0+ (1.5873,0) [0|99.9999] "%" Vector__XXX

BO_ 88 FRS_Obj_08_Part1of2: 8 FRS
 SG_ FRS_P1_08_Msg_AliveCounter : 51|4@0+ (1,0) [0|15] "n/a" Vector__XXX
 SG_ FRS_P1_08_Msg_CheckSum : 63|8@0+ (1,0) [0|255] "n/a" Vector__XXX
 SG_ FRS_P1_08_Obj_MotionPattern : 31|3@0+ (1,0) [0|7] "n/a" Vector__XXX
 SG_ FRS_P1_08_Obj_YPos_Stdev : 22|7@0+ (0.1,0) [0|12.7] "m" Vector__XXX
 SG_ FRS_P1_08_Obj_XVelRel_Stdev : 32|7@0+ (0.05,0) [0|6.35] "m/s" Vector__XXX
 SG_ FRS_P1_08_Obj_XPos_Stdev : 14|7@0+ (0.1,0) [0|12.7] "m" Vector__XXX
 SG_ FRS_P1_08_Obj_XAccRel : 39|7@0+ (0.15,-9.6) [-9.6|9.45] "m/s2" Vector__XXX
 SG_ FRS_P1_08_Obj_ValidFlag : 23|1@0+ (1,0) [0|1] "n/a" Vector__XXX
 SG_ FRS_P1_08_Obj_UpdateFlag : 15|1@0+ (1,0) [0|1] "n/a" Vector__XXX
 SG_ FRS_P1_08_Obj_ObstacleProb : 28|5@0+ (3.2258,0) [0|99.9998] "%" Vector__XXX
 SG_ FRS_P1_08_Obj_ID : 7|8@0+ (1,0) [0|255] "n/a" Vector__XXX
 SG_ FRS_P1_08_Obj_ExstProb : 41|6@0+ (1.5873,0) [0|99.9999] "%" Vector__XXX

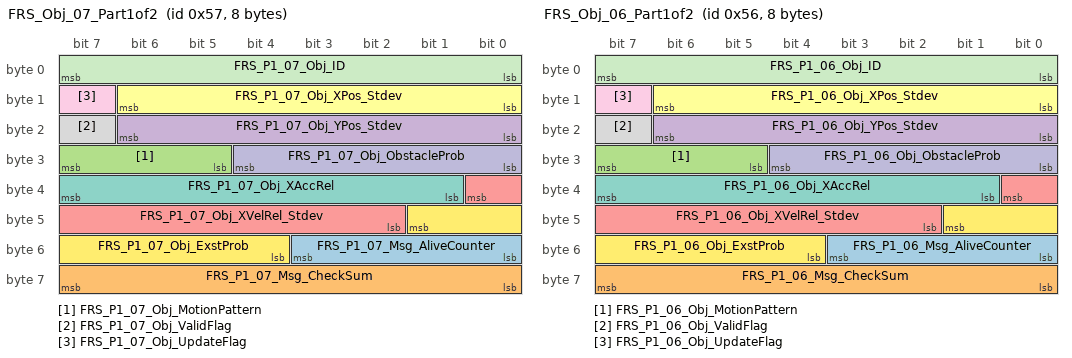
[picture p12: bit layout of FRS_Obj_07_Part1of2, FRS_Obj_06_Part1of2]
BO_ 87 FRS_Obj_07_Part1of2: 8 FRS
 SG_ FRS_P1_07_Msg_AliveCounter : 51|4@0+ (1,0) [0|15] "n/a" Vector__XXX
 SG_ FRS_P1_07_Msg_CheckSum : 63|8@0+ (1,0) [0|255] "n/a" Vector__XXX
 SG_ FRS_P1_07_Obj_MotionPattern : 31|3@0+ (1,0) [0|7] "n/a" Vector__XXX
 SG_ FRS_P1_07_Obj_YPos_Stdev : 22|7@0+ (0.1,0) [0|12.7] "m" Vector__XXX
 SG_ FRS_P1_07_Obj_XVelRel_Stdev : 32|7@0+ (0.05,0) [0|6.35] "m/s" Vector__XXX
 SG_ FRS_P1_07_Obj_XPos_Stdev : 14|7@0+ (0.1,0) [0|12.7] "m" Vector__XXX
 SG_ FRS_P1_07_Obj_XAccRel : 39|7@0+ (0.15,-9.6) [-9.6|9.45] "m/s2" Vector__XXX
 SG_ FRS_P1_07_Obj_ValidFlag : 23|1@0+ (1,0) [0|1] "n/a" Vector__XXX
 SG_ FRS_P1_07_Obj_UpdateFlag : 15|1@0+ (1,0) [0|1] "n/a" Vector__XXX
 SG_ FRS_P1_07_Obj_ObstacleProb : 28|5@0+ (3.2258,0) [0|99.9998] "%" Vector__XXX
 SG_ FRS_P1_07_Obj_ID : 7|8@0+ (1,0) [0|255] "n/a" Vector__XXX
 SG_ FRS_P1_07_Obj_ExstProb : 41|6@0+ (1.5873,0) [0|99.9999] "%" Vector__XXX

BO_ 86 FRS_Obj_06_Part1of2: 8 FRS
 SG_ FRS_P1_06_Msg_AliveCounter : 51|4@0+ (1,0) [0|15] "n/a" Vector__XXX
 SG_ FRS_P1_06_Msg_CheckSum : 63|8@0+ (1,0) [0|255] "n/a" Vector__XXX
 SG_ FRS_P1_06_Obj_MotionPattern : 31|3@0+ (1,0) [0|7] "n/a" Vector__XXX
 SG_ FRS_P1_06_Obj_YPos_Stdev : 22|7@0+ (0.1,0) [0|12.7] "m" Vector__XXX
 SG_ FRS_P1_06_Obj_XVelRel_Stdev : 32|7@0+ (0.05,0) [0|6.35] "m/s" Vector__XXX
 SG_ FRS_P1_06_Obj_XPos_Stdev : 14|7@0+ (0.1,0) [0|12.7] "m" Vector__XXX
 SG_ FRS_P1_06_Obj_XAccRel : 39|7@0+ (0.15,-9.6) [-9.6|9.45] "m/s2" Vector__XXX
 SG_ FRS_P1_06_Obj_ValidFlag : 23|1@0+ (1,0) [0|1] "n/a" Vector__XXX
 SG_ FRS_P1_06_Obj_UpdateFlag : 15|1@0+ (1,0) [0|1] "n/a" Vector__XXX
 SG_ FRS_P1_06_Obj_ObstacleProb : 28|5@0+ (3.2258,0) [0|99.9998] "%" Vector__XXX
 SG_ FRS_P1_06_Obj_ID : 7|8@0+ (1,0) [0|255] "n/a" Vector__XXX
 SG_ FRS_P1_06_Obj_ExstProb : 41|6@0+ (1.5873,0) [0|99.9999] "%" Vector__XXX

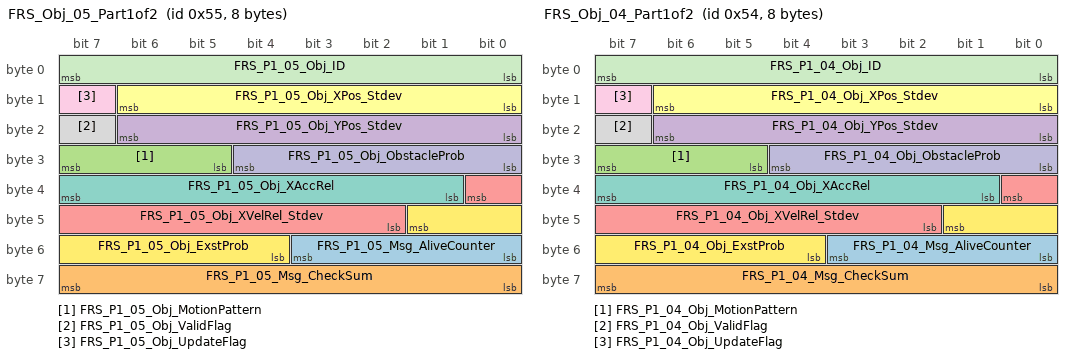
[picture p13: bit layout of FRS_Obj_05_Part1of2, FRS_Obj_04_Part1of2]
BO_ 85 FRS_Obj_05_Part1of2: 8 FRS
 SG_ FRS_P1_05_Msg_AliveCounter : 51|4@0+ (1,0) [0|15] "n/a" Vector__XXX
 SG_ FRS_P1_05_Msg_CheckSum : 63|8@0+ (1,0) [0|255] "n/a" Vector__XXX
 SG_ FRS_P1_05_Obj_MotionPattern : 31|3@0+ (1,0) [0|7] "n/a" Vector__XXX
 SG_ FRS_P1_05_Obj_YPos_Stdev : 22|7@0+ (0.1,0) [0|12.7] "m" Vector__XXX
 SG_ FRS_P1_05_Obj_XVelRel_Stdev : 32|7@0+ (0.05,0) [0|6.35] "m/s" Vector__XXX
 SG_ FRS_P1_05_Obj_XPos_Stdev : 14|7@0+ (0.1,0) [0|12.7] "m" Vector__XXX
 SG_ FRS_P1_05_Obj_XAccRel : 39|7@0+ (0.15,-9.6) [-9.6|9.45] "m/s2" Vector__XXX
 SG_ FRS_P1_05_Obj_ValidFlag : 23|1@0+ (1,0) [0|1] "n/a" Vector__XXX
 SG_ FRS_P1_05_Obj_UpdateFlag : 15|1@0+ (1,0) [0|1] "n/a" Vector__XXX
 SG_ FRS_P1_05_Obj_ObstacleProb : 28|5@0+ (3.2258,0) [0|99.9998] "%" Vector__XXX
 SG_ FRS_P1_05_Obj_ID : 7|8@0+ (1,0) [0|255] "n/a" Vector__XXX
 SG_ FRS_P1_05_Obj_ExstProb : 41|6@0+ (1.5873,0) [0|99.9999] "%" Vector__XXX

BO_ 84 FRS_Obj_04_Part1of2: 8 FRS
 SG_ FRS_P1_04_Msg_AliveCounter : 51|4@0+ (1,0) [0|15] "n/a" Vector__XXX
 SG_ FRS_P1_04_Msg_CheckSum : 63|8@0+ (1,0) [0|255] "n/a" Vector__XXX
 SG_ FRS_P1_04_Obj_MotionPattern : 31|3@0+ (1,0) [0|7] "n/a" Vector__XXX
 SG_ FRS_P1_04_Obj_YPos_Stdev : 22|7@0+ (0.1,0) [0|12.7] "m" Vector__XXX
 SG_ FRS_P1_04_Obj_XVelRel_Stdev : 32|7@0+ (0.05,0) [0|6.35] "m/s" Vector__XXX
 SG_ FRS_P1_04_Obj_XPos_Stdev : 14|7@0+ (0.1,0) [0|12.7] "m" Vector__XXX
 SG_ FRS_P1_04_Obj_XAccRel : 39|7@0+ (0.15,-9.6) [-9.6|9.45] "m/s2" Vector__XXX
 SG_ FRS_P1_04_Obj_ValidFlag : 23|1@0+ (1,0) [0|1] "n/a" Vector__XXX
 SG_ FRS_P1_04_Obj_UpdateFlag : 15|1@0+ (1,0) [0|1] "n/a" Vector__XXX
 SG_ FRS_P1_04_Obj_ObstacleProb : 28|5@0+ (3.2258,0) [0|99.9998] "%" Vector__XXX
 SG_ FRS_P1_04_Obj_ID : 7|8@0+ (1,0) [0|255] "n/a" Vector__XXX
 SG_ FRS_P1_04_Obj_ExstProb : 41|6@0+ (1.5873,0) [0|99.9999] "%" Vector__XXX

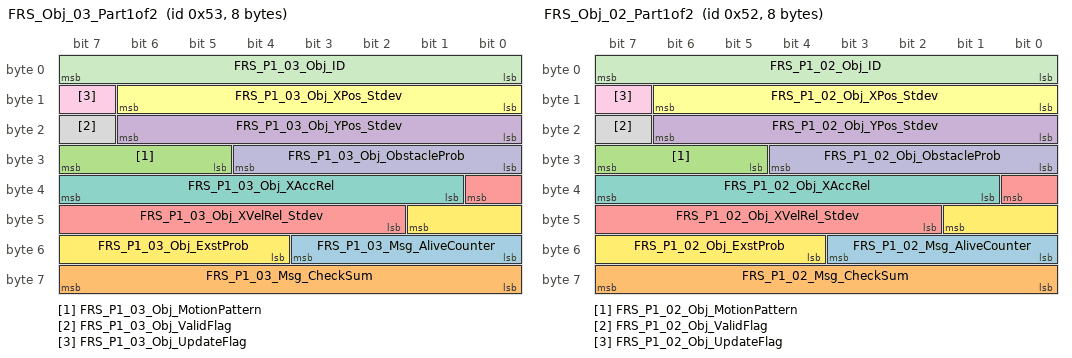
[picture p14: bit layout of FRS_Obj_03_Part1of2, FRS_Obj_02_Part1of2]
BO_ 83 FRS_Obj_03_Part1of2: 8 FRS
 SG_ FRS_P1_03_Msg_AliveCounter : 51|4@0+ (1,0) [0|15] "n/a" Vector__XXX
 SG_ FRS_P1_03_Msg_CheckSum : 63|8@0+ (1,0) [0|255] "n/a" Vector__XXX
 SG_ FRS_P1_03_Obj_MotionPattern : 31|3@0+ (1,0) [0|7] "n/a" Vector__XXX
 SG_ FRS_P1_03_Obj_YPos_Stdev : 22|7@0+ (0.1,0) [0|12.7] "m" Vector__XXX
 SG_ FRS_P1_03_Obj_XVelRel_Stdev : 32|7@0+ (0.05,0) [0|6.35] "m/s" Vector__XXX
 SG_ FRS_P1_03_Obj_XPos_Stdev : 14|7@0+ (0.1,0) [0|12.7] "m" Vector__XXX
 SG_ FRS_P1_03_Obj_XAccRel : 39|7@0+ (0.15,-9.6) [-9.6|9.45] "m/s2" Vector__XXX
 SG_ FRS_P1_03_Obj_ValidFlag : 23|1@0+ (1,0) [0|1] "n/a" Vector__XXX
 SG_ FRS_P1_03_Obj_UpdateFlag : 15|1@0+ (1,0) [0|1] "n/a" Vector__XXX
 SG_ FRS_P1_03_Obj_ObstacleProb : 28|5@0+ (3.2258,0) [0|99.9998] "%" Vector__XXX
 SG_ FRS_P1_03_Obj_ID : 7|8@0+ (1,0) [0|255] "n/a" Vector__XXX
 SG_ FRS_P1_03_Obj_ExstProb : 41|6@0+ (1.5873,0) [0|99.9999] "%" Vector__XXX

BO_ 82 FRS_Obj_02_Part1of2: 8 FRS
 SG_ FRS_P1_02_Msg_AliveCounter : 51|4@0+ (1,0) [0|15] "n/a" Vector__XXX
 SG_ FRS_P1_02_Msg_CheckSum : 63|8@0+ (1,0) [0|255] "n/a" Vector__XXX
 SG_ FRS_P1_02_Obj_MotionPattern : 31|3@0+ (1,0) [0|7] "n/a" Vector__XXX
 SG_ FRS_P1_02_Obj_YPos_Stdev : 22|7@0+ (0.1,0) [0|12.7] "m" Vector__XXX
 SG_ FRS_P1_02_Obj_XVelRel_Stdev : 32|7@0+ (0.05,0) [0|6.35] "m/s" Vector__XXX
 SG_ FRS_P1_02_Obj_XPos_Stdev : 14|7@0+ (0.1,0) [0|12.7] "m" Vector__XXX
 SG_ FRS_P1_02_Obj_XAccRel : 39|7@0+ (0.15,-9.6) [-9.6|9.45] "m/s2" Vector__XXX
 SG_ FRS_P1_02_Obj_ValidFlag : 23|1@0+ (1,0) [0|1] "n/a" Vector__XXX
 SG_ FRS_P1_02_Obj_UpdateFlag : 15|1@0+ (1,0) [0|1] "n/a" Vector__XXX
 SG_ FRS_P1_02_Obj_ObstacleProb : 28|5@0+ (3.2258,0) [0|99.9998] "%" Vector__XXX
 SG_ FRS_P1_02_Obj_ID : 7|8@0+ (1,0) [0|255] "n/a" Vector__XXX
 SG_ FRS_P1_02_Obj_ExstProb : 41|6@0+ (1.5873,0) [0|99.9999] "%" Vector__XXX

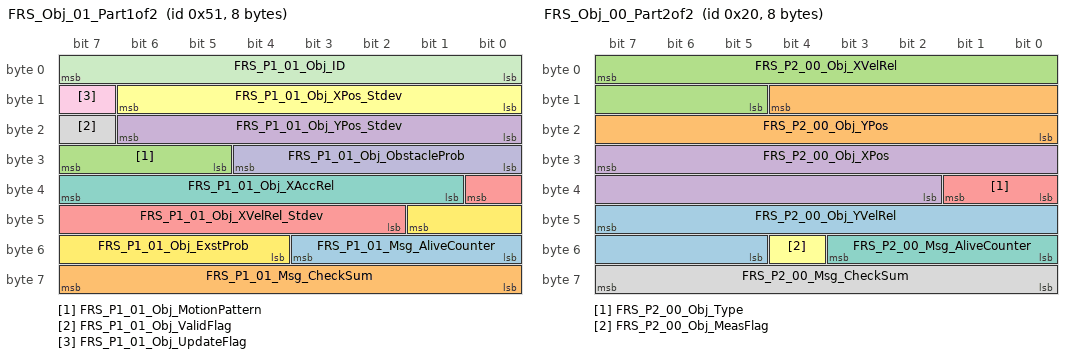
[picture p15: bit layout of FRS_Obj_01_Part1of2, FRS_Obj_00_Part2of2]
BO_ 81 FRS_Obj_01_Part1of2: 8 FRS
 SG_ FRS_P1_01_Msg_AliveCounter : 51|4@0+ (1,0) [0|15] "n/a" Vector__XXX
 SG_ FRS_P1_01_Msg_CheckSum : 63|8@0+ (1,0) [0|255] "n/a" Vector__XXX
 SG_ FRS_P1_01_Obj_MotionPattern : 31|3@0+ (1,0) [0|7] "n/a" Vector__XXX
 SG_ FRS_P1_01_Obj_YPos_Stdev : 22|7@0+ (0.1,0) [0|12.7] "m" Vector__XXX
 SG_ FRS_P1_01_Obj_XVelRel_Stdev : 32|7@0+ (0.05,0) [0|6.35] "m/s" Vector__XXX
 SG_ FRS_P1_01_Obj_XPos_Stdev : 14|7@0+ (0.1,0) [0|12.7] "m" Vector__XXX
 SG_ FRS_P1_01_Obj_XAccRel : 39|7@0+ (0.15,-9.6) [-9.6|9.45] "m/s2" Vector__XXX
 SG_ FRS_P1_01_Obj_ValidFlag : 23|1@0+ (1,0) [0|1] "n/a" Vector__XXX
 SG_ FRS_P1_01_Obj_UpdateFlag : 15|1@0+ (1,0) [0|1] "n/a" Vector__XXX
 SG_ FRS_P1_01_Obj_ObstacleProb : 28|5@0+ (3.2258,0) [0|99.9998] "%" Vector__XXX
 SG_ FRS_P1_01_Obj_ID : 7|8@0+ (1,0) [0|255] "n/a" Vector__XXX
 SG_ FRS_P1_01_Obj_ExstProb : 41|6@0+ (1.5873,0) [0|99.9999] "%" Vector__XXX

BO_ 32 FRS_Obj_00_Part2of2: 8 FRS
 SG_ FRS_P2_00_Obj_YVelRel : 47|11@0+ (0.1,-102.4) [-102.4|102.3] "m/s" Vector__XXX
 SG_ FRS_P2_00_Obj_YPos : 12|13@0+ (0.015625,-64) [-64|63.984375] "m" Vector__XXX
 SG_ FRS_P2_00_Obj_XVelRel : 7|11@0+ (0.1,-102.4) [-102.4|102.3] "m/s" Vector__XXX
 SG_ FRS_P2_00_Obj_XPos : 31|14@0+ (0.015625,0) [0|255.984375] "m" Vector__XXX
 SG_ FRS_P2_00_Obj_Type : 33|2@0+ (1,0) [0|3] "n/a" Vector__XXX
 SG_ FRS_P2_00_Obj_MeasFlag : 52|1@0+ (1,0) [0|1] "n/a" Vector__XXX
 SG_ FRS_P2_00_Msg_AliveCounter : 51|4@0+ (1,0) [0|15] "n/a" Vector__XXX
 SG_ FRS_P2_00_Msg_CheckSum : 63|8@0+ (1,0) [0|255] "n/a" Vector__XXX

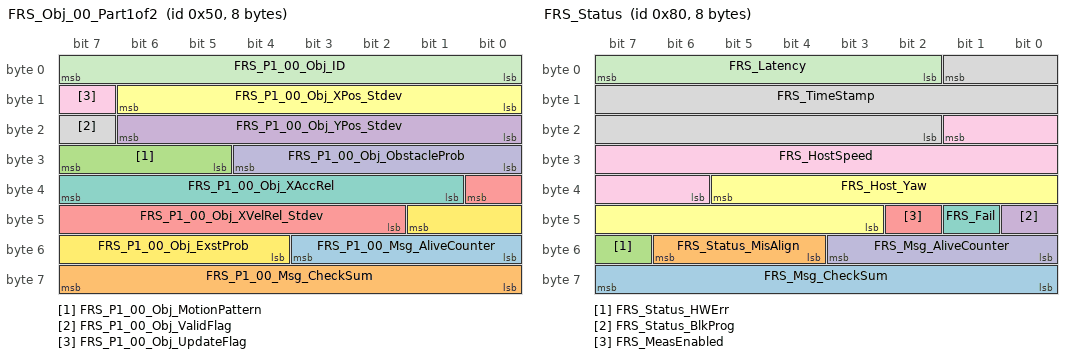
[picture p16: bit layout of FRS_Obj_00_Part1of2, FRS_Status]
BO_ 80 FRS_Obj_00_Part1of2: 8 FRS
 SG_ FRS_P1_00_Msg_AliveCounter : 51|4@0+ (1,0) [0|15] "n/a" Vector__XXX
 SG_ FRS_P1_00_Msg_CheckSum : 63|8@0+ (1,0) [0|255] "n/a" Vector__XXX
 SG_ FRS_P1_00_Obj_MotionPattern : 31|3@0+ (1,0) [0|7] "n/a" Vector__XXX
 SG_ FRS_P1_00_Obj_YPos_Stdev : 22|7@0+ (0.1,0) [0|12.7] "m" Vector__XXX
 SG_ FRS_P1_00_Obj_XVelRel_Stdev : 32|7@0+ (0.05,0) [0|6.35] "m/s" Vector__XXX
 SG_ FRS_P1_00_Obj_XPos_Stdev : 14|7@0+ (0.1,0) [0|12.7] "m" Vector__XXX
 SG_ FRS_P1_00_Obj_XAccRel : 39|7@0+ (0.15,-9.6) [-9.6|9.45] "m/s2" Vector__XXX
 SG_ FRS_P1_00_Obj_ValidFlag : 23|1@0+ (1,0) [0|1] "n/a" Vector__XXX
 SG_ FRS_P1_00_Obj_UpdateFlag : 15|1@0+ (1,0) [0|1] "n/a" Vector__XXX
 SG_ FRS_P1_00_Obj_ObstacleProb : 28|5@0+ (3.2258,0) [0|99.9998] "%" Vector__XXX
 SG_ FRS_P1_00_Obj_ID : 7|8@0+ (1,0) [0|255] "n/a" Vector__XXX
 SG_ FRS_P1_00_Obj_ExstProb : 41|6@0+ (1.5873,0) [0|99.9999] "%" Vector__XXX

BO_ 128 FRS_Status: 8 FRS
 SG_ FRS_Msg_CheckSum : 63|8@0+ (1,0) [0|255] "n/a" Vector__XXX
 SG_ FRS_Status_MisAlign : 54|3@0+ (1,0) [0|7] "n/a" Vector__XXX
 SG_ FRS_Status_HWErr : 55|1@0+ (1,0) [0|1] "n/a" Vector__XXX
 SG_ FRS_Status_BlkProg : 40|1@0+ (1,0) [0|1] "n/a" Vector__XXX
 SG_ FRS_MeasEnabled : 42|1@0+ (1,0) [0|1] "n/a" Vector__XXX
 SG_ FRS_Host_Yaw : 37|11@0+ (0.1,-102.4) [-102.4|102.3] "deg/s" Vector__XXX
 SG_ FRS_Fail : 41|1@0+ (1,0) [0|1] "" Vector__XXX
 SG_ FRS_TimeStamp : 1|16@0+ (1,0) [0|65535] "s" Vector__XXX
 SG_ FRS_HostSpeed : 17|12@0+ (0.025,-20) [-20|82.375] "m/s" Vector__XXX
 SG_ FRS_Msg_AliveCounter : 51|4@0+ (1,0) [0|15] "n/a" Vector__XXX
 SG_ FRS_Latency : 7|6@0+ (2,0) [0|126] "ms" Vector__XXX

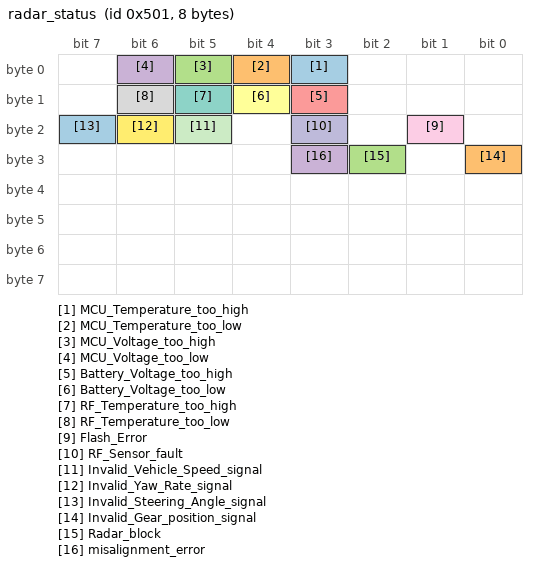
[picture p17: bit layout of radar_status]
BO_ 1281 radar_status: 8 MN_K77
 SG_ MCU_Temperature_too_high : 3|1@0+ (1,0) [0|1] "1" Vector__XXX
 SG_ MCU_Temperature_too_low : 4|1@0+ (1,0) [0|1] "1" Vector__XXX
 SG_ MCU_Voltage_too_high : 5|1@0+ (1,0) [0|1] "1" Vector__XXX
 SG_ MCU_Voltage_too_low : 6|1@0+ (1,0) [0|1] "1" Vector__XXX
 SG_ Battery_Voltage_too_high : 11|1@0+ (1,0) [0|1] "1" Vector__XXX
 SG_ Battery_Voltage_too_low : 12|1@0+ (1,0) [0|1] "1" Vector__XXX
 SG_ RF_Temperature_too_high : 13|1@0+ (1,0) [0|1] "1" Vector__XXX
 SG_ RF_Temperature_too_low : 14|1@0+ (1,0) [0|1] "1" Vector__XXX
 SG_ Flash_Error : 17|1@0+ (1,0) [0|1] "1" Vector__XXX
 SG_ RF_Sensor_fault : 19|1@0+ (1,0) [0|1] "1" Vector__XXX
 SG_ Invalid_Vehicle_Speed_signal : 21|1@0+ (1,0) [0|1] "1" Vector__XXX
 SG_ Invalid_Yaw_Rate_signal : 22|1@0+ (1,0) [0|1] "1" Vector__XXX
 SG_ Invalid_Steering_Angle_signal : 23|1@0+ (1,0) [0|1] "1" Vector__XXX
 SG_ Invalid_Gear_position_signal : 24|1@0+ (1,0) [0|1] "1" Vector__XXX
 SG_ Radar_block : 26|1@0+ (1,0) [0|1] "1" Vector__XXX
 SG_ misalignment_error : 27|1@0+ (1,0) [0|1] "1" Vector__XXX

CM_ SG_ 112 FRS_P1_32_Msg_AliveCounter "Alive counter shall be incremented every radar sensor measurement cycle.";
CM_ SG_ 112 FRS_P1_32_Msg_CheckSum "Check sum shall be generated out of each message content. check sum generation logic is TBC.";
CM_ SG_ 112 FRS_P1_32_Obj_MotionPattern "Motion type of object.
0x00: Unknown
0x01: Stationary
0x02: Stopped
0x03: Moving
0x04: Crossing
0x05-07: reserved";
CM_ SG_ 112 FRS_P1_32_Obj_YPos_Stdev "Estimated 3-sigma standard deviation value of lateral position of the object.";
CM_ SG_ 112 FRS_P1_32_Obj_XVelRel_Stdev "Estimated 3-sigma standard deviation value of the relative longitudinal velocity of the object.";
CM_ SG_ 112 FRS_P1_32_Obj_XPos_Stdev "Estimated 3-sigma standard deviation value of longitudinal position of the object.";
CM_ SG_ 112 FRS_P1_32_Obj_XAccRel "Relative longitudinal acceleration of the object";
CM_ SG_ 112 FRS_P1_32_Obj_ValidFlag "Validity indication flag. when this value shows invalid, all the signals in the corresponding CAN messages except FRS_Msg_AliveCounter and FRS_Msg_CheckSum shall take default values.
0x0: Object invalid
0x1: Object valid";
CM_ SG_ 112 FRS_P1_32_Obj_UpdateFlag "Flag to indicate newly created object in CAN bus.
Object history flag
0x0: new object in the cycle;
0x1: object existed in previous cycle";
CM_ SG_ 112 FRS_P1_32_Obj_ObstacleProb "Estimated probability of the object being an obstacle.";
CM_ SG_ 112 FRS_P1_32_Obj_ID "ID is defined as a unique identification number over the lifetime of the object.
0xFF: Invalid
0x00 - 0xFE: Valid";
CM_ SG_ 112 FRS_P1_32_Obj_ExstProb "Estimated existence probability of the object.";
CM_ SG_ 111 FRS_P1_31_Msg_AliveCounter "Alive counter shall be incremented every radar sensor measurement cycle.";
CM_ SG_ 111 FRS_P1_31_Msg_CheckSum "Check sum shall be generated out of each message content. check sum generation logic is TBC.";
CM_ SG_ 111 FRS_P1_31_Obj_MotionPattern "Motion type of object.
0x00: Unknown
0x01: Stationary
0x02: Stopped
0x03: Moving
0x04: Crossing
0x05-07: reserved";
CM_ SG_ 111 FRS_P1_31_Obj_YPos_Stdev "Estimated 3-sigma standard deviation value of lateral position of the object.";
CM_ SG_ 111 FRS_P1_31_Obj_XVelRel_Stdev "Estimated 3-sigma standard deviation value of the relative longitudinal velocity of the object.";
CM_ SG_ 111 FRS_P1_31_Obj_XPos_Stdev "Estimated 3-sigma standard deviation value of longitudinal position of the object.";
CM_ SG_ 111 FRS_P1_31_Obj_XAccRel "Relative longitudinal acceleration of the object";
CM_ SG_ 111 FRS_P1_31_Obj_ValidFlag "Validity indication flag. when this value shows invalid, all the signals in the corresponding CAN messages except FRS_Msg_AliveCounter and FRS_Msg_CheckSum shall take default values.
0x0: Object invalid
0x1: Object valid";
CM_ SG_ 111 FRS_P1_31_Obj_UpdateFlag "Flag to indicate newly created object in CAN bus.
Object history flag
0x0: new object in the cycle;
0x1: object existed in previous cycle";
CM_ SG_ 111 FRS_P1_31_Obj_ObstacleProb "Estimated probability of the object being an obstacle.";
CM_ SG_ 111 FRS_P1_31_Obj_ID "ID is defined as a unique identification number over the lifetime of the object.
0xFF: Invalid
0x00 - 0xFE: Valid";
CM_ SG_ 111 FRS_P1_31_Obj_ExstProb "Estimated existence probability of the object.";
CM_ SG_ 110 FRS_P1_30_Msg_AliveCounter "Alive counter shall be incremented every radar sensor measurement cycle.";
CM_ SG_ 110 FRS_P1_30_Msg_CheckSum "Check sum shall be generated out of each message content. check sum generation logic is TBC.";
CM_ SG_ 110 FRS_P1_30_Obj_MotionPattern "Motion type of object.
0x00: Unknown
0x01: Stationary
0x02: Stopped
0x03: Moving
0x04: Crossing
0x05-07: reserved";
CM_ SG_ 110 FRS_P1_30_Obj_YPos_Stdev "Estimated 3-sigma standard deviation value of lateral position of the object.";
CM_ SG_ 110 FRS_P1_30_Obj_XVelRel_Stdev "Estimated 3-sigma standard deviation value of the relative longitudinal velocity of the object.";
CM_ SG_ 110 FRS_P1_30_Obj_XPos_Stdev "Estimated 3-sigma standard deviation value of longitudinal position of the object.";
CM_ SG_ 110 FRS_P1_30_Obj_XAccRel "Relative longitudinal acceleration of the object";
CM_ SG_ 110 FRS_P1_30_Obj_ValidFlag "Validity indication flag. when this value shows invalid, all the signals in the corresponding CAN messages except FRS_Msg_AliveCounter and FRS_Msg_CheckSum shall take default values.
0x0: Object invalid
0x1: Object valid";
CM_ SG_ 110 FRS_P1_30_Obj_UpdateFlag "Flag to indicate newly created object in CAN bus.
Object history flag
0x0: new object in the cycle;
0x1: object existed in previous cycle";
CM_ SG_ 110 FRS_P1_30_Obj_ObstacleProb "Estimated probability of the object being an obstacle.";
CM_ SG_ 110 FRS_P1_30_Obj_ID "ID is defined as a unique identification number over the lifetime of the object.
0xFF: Invalid
0x00 - 0xFE: Valid";
CM_ SG_ 110 FRS_P1_30_Obj_ExstProb "Estimated existence probability of the object.";
CM_ SG_ 109 FRS_P1_29_Msg_AliveCounter "Alive counter shall be incremented every radar sensor measurement cycle.";
CM_ SG_ 109 FRS_P1_29_Msg_CheckSum "Check sum shall be generated out of each message content. check sum generation logic is TBC.";
CM_ SG_ 109 FRS_P1_29_Obj_MotionPattern "Motion type of object.
0x00: Unknown
0x01: Stationary
0x02: Stopped
0x03: Moving
0x04: Crossing
0x05-07: reserved";
CM_ SG_ 109 FRS_P1_29_Obj_YPos_Stdev "Estimated 3-sigma standard deviation value of lateral position of the object.";
CM_ SG_ 109 FRS_P1_29_Obj_XVelRel_Stdev "Estimated 3-sigma standard deviation value of the relative longitudinal velocity of the object.";
CM_ SG_ 109 FRS_P1_29_Obj_XPos_Stdev "Estimated 3-sigma standard deviation value of longitudinal position of the object.";
CM_ SG_ 109 FRS_P1_29_Obj_XAccRel "Relative longitudinal acceleration of the object";
CM_ SG_ 109 FRS_P1_29_Obj_ValidFlag "Validity indication flag. when this value shows invalid, all the signals in the corresponding CAN messages except FRS_Msg_AliveCounter and FRS_Msg_CheckSum shall take default values.
0x0: Object invalid
0x1: Object valid";
CM_ SG_ 109 FRS_P1_29_Obj_UpdateFlag "Flag to indicate newly created object in CAN bus.
Object history flag
0x0: new object in the cycle;
0x1: object existed in previous cycle";
CM_ SG_ 109 FRS_P1_29_Obj_ObstacleProb "Estimated probability of the object being an obstacle.";
CM_ SG_ 109 FRS_P1_29_Obj_ID "ID is defined as a unique identification number over the lifetime of the object.
0xFF: Invalid
0x00 - 0xFE: Valid";
CM_ SG_ 109 FRS_P1_29_Obj_ExstProb "Estimated existence probability of the object.";
CM_ SG_ 108 FRS_P1_28_Msg_AliveCounter "Alive counter shall be incremented every radar sensor measurement cycle.";
CM_ SG_ 108 FRS_P1_28_Msg_CheckSum "Check sum shall be generated out of each message content. check sum generation logic is TBC.";
CM_ SG_ 108 FRS_P1_28_Obj_MotionPattern "Motion type of object.
0x00: Unknown
0x01: Stationary
0x02: Stopped
0x03: Moving
0x04: Crossing
0x05-07: reserved";
CM_ SG_ 108 FRS_P1_28_Obj_YPos_Stdev "Estimated 3-sigma standard deviation value of lateral position of the object.";
CM_ SG_ 108 FRS_P1_28_Obj_XVelRel_Stdev "Estimated 3-sigma standard deviation value of the relative longitudinal velocity of the object.";
CM_ SG_ 108 FRS_P1_28_Obj_XPos_Stdev "Estimated 3-sigma standard deviation value of longitudinal position of the object.";
CM_ SG_ 108 FRS_P1_28_Obj_XAccRel "Relative longitudinal acceleration of the object";
CM_ SG_ 108 FRS_P1_28_Obj_ValidFlag "Validity indication flag. when this value shows invalid, all the signals in the corresponding CAN messages except FRS_Msg_AliveCounter and FRS_Msg_CheckSum shall take default values.
0x0: Object invalid
0x1: Object valid";
CM_ SG_ 108 FRS_P1_28_Obj_UpdateFlag "Flag to indicate newly created object in CAN bus.
Object history flag
0x0: new object in the cycle;
0x1: object existed in previous cycle";
CM_ SG_ 108 FRS_P1_28_Obj_ObstacleProb "Estimated probability of the object being an obstacle.";
CM_ SG_ 108 FRS_P1_28_Obj_ID "ID is defined as a unique identification number over the lifetime of the object.
0xFF: Invalid
0x00 - 0xFE: Valid";
CM_ SG_ 108 FRS_P1_28_Obj_ExstProb "Estimated existence probability of the object.";
CM_ SG_ 107 FRS_P1_27_Msg_AliveCounter "Alive counter shall be incremented every radar sensor measurement cycle.";
CM_ SG_ 107 FRS_P1_27_Msg_CheckSum "Check sum shall be generated out of each message content. check sum generation logic is TBC.";
CM_ SG_ 107 FRS_P1_27_Obj_MotionPattern "Motion type of object.
0x00: Unknown
0x01: Stationary
0x02: Stopped
0x03: Moving
0x04: Crossing
0x05-07: reserved";
CM_ SG_ 107 FRS_P1_27_Obj_YPos_Stdev "Estimated 3-sigma standard deviation value of lateral position of the object.";
CM_ SG_ 107 FRS_P1_27_Obj_XVelRel_Stdev "Estimated 3-sigma standard deviation value of the relative longitudinal velocity of the object.";
CM_ SG_ 107 FRS_P1_27_Obj_XPos_Stdev "Estimated 3-sigma standard deviation value of longitudinal position of the object.";
CM_ SG_ 107 FRS_P1_27_Obj_XAccRel "Relative longitudinal acceleration of the object";
CM_ SG_ 107 FRS_P1_27_Obj_ValidFlag "Validity indication flag. when this value shows invalid, all the signals in the corresponding CAN messages except FRS_Msg_AliveCounter and FRS_Msg_CheckSum shall take default values.
0x0: Object invalid
0x1: Object valid";
CM_ SG_ 107 FRS_P1_27_Obj_UpdateFlag "Flag to indicate newly created object in CAN bus.
Object history flag
0x0: new object in the cycle;
0x1: object existed in previous cycle";
CM_ SG_ 107 FRS_P1_27_Obj_ObstacleProb "Estimated probability of the object being an obstacle.";
CM_ SG_ 107 FRS_P1_27_Obj_ID "ID is defined as a unique identification number over the lifetime of the object.
0xFF: Invalid
0x00 - 0xFE: Valid";
CM_ SG_ 107 FRS_P1_27_Obj_ExstProb "Estimated existence probability of the object.";
CM_ SG_ 106 FRS_P1_26_Msg_AliveCounter "Alive counter shall be incremented every radar sensor measurement cycle.";
CM_ SG_ 106 FRS_P1_26_Msg_CheckSum "Check sum shall be generated out of each message content. check sum generation logic is TBC.";
CM_ SG_ 106 FRS_P1_26_Obj_MotionPattern "Motion type of object.
0x00: Unknown
0x01: Stationary
0x02: Stopped
0x03: Moving
0x04: Crossing
0x05-07: reserved";
CM_ SG_ 106 FRS_P1_26_Obj_YPos_Stdev "Estimated 3-sigma standard deviation value of lateral position of the object.";
CM_ SG_ 106 FRS_P1_26_Obj_XVelRel_Stdev "Estimated 3-sigma standard deviation value of the relative longitudinal velocity of the object.";
CM_ SG_ 106 FRS_P1_26_Obj_XPos_Stdev "Estimated 3-sigma standard deviation value of longitudinal position of the object.";
CM_ SG_ 106 FRS_P1_26_Obj_XAccRel "Relative longitudinal acceleration of the object";
CM_ SG_ 106 FRS_P1_26_Obj_ValidFlag "Validity indication flag. when this value shows invalid, all the signals in the corresponding CAN messages except FRS_Msg_AliveCounter and FRS_Msg_CheckSum shall take default values.
0x0: Object invalid
0x1: Object valid";
CM_ SG_ 106 FRS_P1_26_Obj_UpdateFlag "Flag to indicate newly created object in CAN bus.
Object history flag
0x0: new object in the cycle;
0x1: object existed in previous cycle";
CM_ SG_ 106 FRS_P1_26_Obj_ObstacleProb "Estimated probability of the object being an obstacle.";
CM_ SG_ 106 FRS_P1_26_Obj_ID "ID is defined as a unique identification number over the lifetime of the object.
0xFF: Invalid
0x00 - 0xFE: Valid";
CM_ SG_ 106 FRS_P1_26_Obj_ExstProb "Estimated existence probability of the object.";
CM_ SG_ 105 FRS_P1_25_Msg_AliveCounter "Alive counter shall be incremented every radar sensor measurement cycle.";
CM_ SG_ 105 FRS_P1_25_Msg_CheckSum "Check sum shall be generated out of each message content. check sum generation logic is TBC.";
CM_ SG_ 105 FRS_P1_25_Obj_MotionPattern "Motion type of object.
0x00: Unknown
0x01: Stationary
0x02: Stopped
0x03: Moving
0x04: Crossing
0x05-07: reserved";
CM_ SG_ 105 FRS_P1_25_Obj_YPos_Stdev "Estimated 3-sigma standard deviation value of lateral position of the object.";
CM_ SG_ 105 FRS_P1_25_Obj_XVelRel_Stdev "Estimated 3-sigma standard deviation value of the relative longitudinal velocity of the object.";
CM_ SG_ 105 FRS_P1_25_Obj_XPos_Stdev "Estimated 3-sigma standard deviation value of longitudinal position of the object.";
CM_ SG_ 105 FRS_P1_25_Obj_XAccRel "Relative longitudinal acceleration of the object";
CM_ SG_ 105 FRS_P1_25_Obj_ValidFlag "Validity indication flag. when this value shows invalid, all the signals in the corresponding CAN messages except FRS_Msg_AliveCounter and FRS_Msg_CheckSum shall take default values.
0x0: Object invalid
0x1: Object valid";
CM_ SG_ 105 FRS_P1_25_Obj_UpdateFlag "Flag to indicate newly created object in CAN bus.
Object history flag
0x0: new object in the cycle;
0x1: object existed in previous cycle";
CM_ SG_ 105 FRS_P1_25_Obj_ObstacleProb "Estimated probability of the object being an obstacle.";
CM_ SG_ 105 FRS_P1_25_Obj_ID "ID is defined as a unique identification number over the lifetime of the object.
0xFF: Invalid
0x00 - 0xFE: Valid";
CM_ SG_ 105 FRS_P1_25_Obj_ExstProb "Estimated existence probability of the object.";
CM_ SG_ 104 FRS_P1_24_Msg_AliveCounter "Alive counter shall be incremented every radar sensor measurement cycle.";
CM_ SG_ 104 FRS_P1_24_Msg_CheckSum "Check sum shall be generated out of each message content. check sum generation logic is TBC.";
CM_ SG_ 104 FRS_P1_24_Obj_MotionPattern "Motion type of object.
0x00: Unknown
0x01: Stationary
0x02: Stopped
0x03: Moving
0x04: Crossing
0x05-07: reserved";
CM_ SG_ 104 FRS_P1_24_Obj_YPos_Stdev "Estimated 3-sigma standard deviation value of lateral position of the object.";
CM_ SG_ 104 FRS_P1_24_Obj_XVelRel_Stdev "Estimated 3-sigma standard deviation value of the relative longitudinal velocity of the object.";
CM_ SG_ 104 FRS_P1_24_Obj_XPos_Stdev "Estimated 3-sigma standard deviation value of longitudinal position of the object.";
CM_ SG_ 104 FRS_P1_24_Obj_XAccRel "Relative longitudinal acceleration of the object";
CM_ SG_ 104 FRS_P1_24_Obj_ValidFlag "Validity indication flag. when this value shows invalid, all the signals in the corresponding CAN messages except FRS_Msg_AliveCounter and FRS_Msg_CheckSum shall take default values.
0x0: Object invalid
0x1: Object valid";
CM_ SG_ 104 FRS_P1_24_Obj_UpdateFlag "Flag to indicate newly created object in CAN bus.
Object history flag
0x0: new object in the cycle;
0x1: object existed in previous cycle";
CM_ SG_ 104 FRS_P1_24_Obj_ObstacleProb "Estimated probability of the object being an obstacle.";
CM_ SG_ 104 FRS_P1_24_Obj_ID "ID is defined as a unique identification number over the lifetime of the object.
0xFF: Invalid
0x00 - 0xFE: Valid";
CM_ SG_ 104 FRS_P1_24_Obj_ExstProb "Estimated existence probability of the object.";
CM_ SG_ 103 FRS_P1_23_Msg_AliveCounter "Alive counter shall be incremented every radar sensor measurement cycle.";
CM_ SG_ 103 FRS_P1_23_Msg_CheckSum "Check sum shall be generated out of each message content. check sum generation logic is TBC.";
CM_ SG_ 103 FRS_P1_23_Obj_MotionPattern "Motion type of object.
0x00: Unknown
0x01: Stationary
0x02: Stopped
0x03: Moving
0x04: Crossing
0x05-07: reserved";
CM_ SG_ 103 FRS_P1_23_Obj_YPos_Stdev "Estimated 3-sigma standard deviation value of lateral position of the object.";
CM_ SG_ 103 FRS_P1_23_Obj_XVelRel_Stdev "Estimated 3-sigma standard deviation value of the relative longitudinal velocity of the object.";
CM_ SG_ 103 FRS_P1_23_Obj_XPos_Stdev "Estimated 3-sigma standard deviation value of longitudinal position of the object.";
CM_ SG_ 103 FRS_P1_23_Obj_XAccRel "Relative longitudinal acceleration of the object";
CM_ SG_ 103 FRS_P1_23_Obj_ValidFlag "Validity indication flag. when this value shows invalid, all the signals in the corresponding CAN messages except FRS_Msg_AliveCounter and FRS_Msg_CheckSum shall take default values.
0x0: Object invalid
0x1: Object valid";
CM_ SG_ 103 FRS_P1_23_Obj_UpdateFlag "Flag to indicate newly created object in CAN bus.
Object history flag
0x0: new object in the cycle;
0x1: object existed in previous cycle";
CM_ SG_ 103 FRS_P1_23_Obj_ObstacleProb "Estimated probability of the object being an obstacle.";
CM_ SG_ 103 FRS_P1_23_Obj_ID "ID is defined as a unique identification number over the lifetime of the object.
0xFF: Invalid
0x00 - 0xFE: Valid";
CM_ SG_ 103 FRS_P1_23_Obj_ExstProb "Estimated existence probability of the object.";
CM_ SG_ 102 FRS_P1_22_Msg_AliveCounter "Alive counter shall be incremented every radar sensor measurement cycle.";
CM_ SG_ 102 FRS_P1_22_Msg_CheckSum "Check sum shall be generated out of each message content. check sum generation logic is TBC.";
CM_ SG_ 102 FRS_P1_22_Obj_MotionPattern "Motion type of object.
0x00: Unknown
0x01: Stationary
0x02: Stopped
0x03: Moving
0x04: Crossing
0x05-07: reserved";
CM_ SG_ 102 FRS_P1_22_Obj_YPos_Stdev "Estimated 3-sigma standard deviation value of lateral position of the object.";
CM_ SG_ 102 FRS_P1_22_Obj_XVelRel_Stdev "Estimated 3-sigma standard deviation value of the relative longitudinal velocity of the object.";
CM_ SG_ 102 FRS_P1_22_Obj_XPos_Stdev "Estimated 3-sigma standard deviation value of longitudinal position of the object.";
CM_ SG_ 102 FRS_P1_22_Obj_XAccRel "Relative longitudinal acceleration of the object";
CM_ SG_ 102 FRS_P1_22_Obj_ValidFlag "Validity indication flag. when this value shows invalid, all the signals in the corresponding CAN messages except FRS_Msg_AliveCounter and FRS_Msg_CheckSum shall take default values.
0x0: Object invalid
0x1: Object valid";
CM_ SG_ 102 FRS_P1_22_Obj_UpdateFlag "Flag to indicate newly created object in CAN bus.
Object history flag
0x0: new object in the cycle;
0x1: object existed in previous cycle";
CM_ SG_ 102 FRS_P1_22_Obj_ObstacleProb "Estimated probability of the object being an obstacle.";
CM_ SG_ 102 FRS_P1_22_Obj_ID "ID is defined as a unique identification number over the lifetime of the object.
0xFF: Invalid
0x00 - 0xFE: Valid";
CM_ SG_ 102 FRS_P1_22_Obj_ExstProb "Estimated existence probability of the object.";
CM_ SG_ 101 FRS_P1_21_Msg_AliveCounter "Alive counter shall be incremented every radar sensor measurement cycle.";
CM_ SG_ 101 FRS_P1_21_Msg_CheckSum "Check sum shall be generated out of each message content. check sum generation logic is TBC.";
CM_ SG_ 101 FRS_P1_21_Obj_MotionPattern "Motion type of object.
0x00: Unknown
0x01: Stationary
0x02: Stopped
0x03: Moving
0x04: Crossing
0x05-07: reserved";
CM_ SG_ 101 FRS_P1_21_Obj_YPos_Stdev "Estimated 3-sigma standard deviation value of lateral position of the object.";
CM_ SG_ 101 FRS_P1_21_Obj_XVelRel_Stdev "Estimated 3-sigma standard deviation value of the relative longitudinal velocity of the object.";
CM_ SG_ 101 FRS_P1_21_Obj_XPos_Stdev "Estimated 3-sigma standard deviation value of longitudinal position of the object.";
CM_ SG_ 101 FRS_P1_21_Obj_XAccRel "Relative longitudinal acceleration of the object";
CM_ SG_ 101 FRS_P1_21_Obj_ValidFlag "Validity indication flag. when this value shows invalid, all the signals in the corresponding CAN messages except FRS_Msg_AliveCounter and FRS_Msg_CheckSum shall take default values.
0x0: Object invalid
0x1: Object valid";
CM_ SG_ 101 FRS_P1_21_Obj_UpdateFlag "Flag to indicate newly created object in CAN bus.
Object history flag
0x0: new object in the cycle;
0x1: object existed in previous cycle";
CM_ SG_ 101 FRS_P1_21_Obj_ObstacleProb "Estimated probability of the object being an obstacle.";
CM_ SG_ 101 FRS_P1_21_Obj_ID "ID is defined as a unique identification number over the lifetime of the object.
0xFF: Invalid
0x00 - 0xFE: Valid";
CM_ SG_ 101 FRS_P1_21_Obj_ExstProb "Estimated existence probability of the object.";
CM_ SG_ 100 FRS_P1_20_Msg_AliveCounter "Alive counter shall be incremented every radar sensor measurement cycle.";
CM_ SG_ 100 FRS_P1_20_Msg_CheckSum "Check sum shall be generated out of each message content. check sum generation logic is TBC.";
CM_ SG_ 100 FRS_P1_20_Obj_MotionPattern "Motion type of object.
0x00: Unknown
0x01: Stationary
0x02: Stopped
0x03: Moving
0x04: Crossing
0x05-07: reserved";
CM_ SG_ 100 FRS_P1_20_Obj_YPos_Stdev "Estimated 3-sigma standard deviation value of lateral position of the object.";
CM_ SG_ 100 FRS_P1_20_Obj_XVelRel_Stdev "Estimated 3-sigma standard deviation value of the relative longitudinal velocity of the object.";
CM_ SG_ 100 FRS_P1_20_Obj_XPos_Stdev "Estimated 3-sigma standard deviation value of longitudinal position of the object.";
CM_ SG_ 100 FRS_P1_20_Obj_XAccRel "Relative longitudinal acceleration of the object";
CM_ SG_ 100 FRS_P1_20_Obj_ValidFlag "Validity indication flag. when this value shows invalid, all the signals in the corresponding CAN messages except FRS_Msg_AliveCounter and FRS_Msg_CheckSum shall take default values.
0x0: Object invalid
0x1: Object valid";
CM_ SG_ 100 FRS_P1_20_Obj_UpdateFlag "Flag to indicate newly created object in CAN bus.
Object history flag
0x0: new object in the cycle;
0x1: object existed in previous cycle";
CM_ SG_ 100 FRS_P1_20_Obj_ObstacleProb "Estimated probability of the object being an obstacle.";
CM_ SG_ 100 FRS_P1_20_Obj_ID "ID is defined as a unique identification number over the lifetime of the object.
0xFF: Invalid
0x00 - 0xFE: Valid";
CM_ SG_ 100 FRS_P1_20_Obj_ExstProb "Estimated existence probability of the object.";
CM_ SG_ 99 FRS_P1_19_Msg_AliveCounter "Alive counter shall be incremented every radar sensor measurement cycle.";
CM_ SG_ 99 FRS_P1_19_Msg_CheckSum "Check sum shall be generated out of each message content. check sum generation logic is TBC.";
CM_ SG_ 99 FRS_P1_19_Obj_MotionPattern "Motion type of object.
0x00: Unknown
0x01: Stationary
0x02: Stopped
0x03: Moving
0x04: Crossing
0x05-07: reserved";
CM_ SG_ 99 FRS_P1_19_Obj_YPos_Stdev "Estimated 3-sigma standard deviation value of lateral position of the object.";
CM_ SG_ 99 FRS_P1_19_Obj_XVelRel_Stdev "Estimated 3-sigma standard deviation value of the relative longitudinal velocity of the object.";
CM_ SG_ 99 FRS_P1_19_Obj_XPos_Stdev "Estimated 3-sigma standard deviation value of longitudinal position of the object.";
CM_ SG_ 99 FRS_P1_19_Obj_XAccRel "Relative longitudinal acceleration of the object";
CM_ SG_ 99 FRS_P1_19_Obj_ValidFlag "Validity indication flag. when this value shows invalid, all the signals in the corresponding CAN messages except FRS_Msg_AliveCounter and FRS_Msg_CheckSum shall take default values.
0x0: Object invalid
0x1: Object valid";
CM_ SG_ 99 FRS_P1_19_Obj_UpdateFlag "Flag to indicate newly created object in CAN bus.
Object history flag
0x0: new object in the cycle;
0x1: object existed in previous cycle";
CM_ SG_ 99 FRS_P1_19_Obj_ObstacleProb "Estimated probability of the object being an obstacle.";
CM_ SG_ 99 FRS_P1_19_Obj_ID "ID is defined as a unique identification number over the lifetime of the object.
0xFF: Invalid
0x00 - 0xFE: Valid";
CM_ SG_ 99 FRS_P1_19_Obj_ExstProb "Estimated existence probability of the object.";
CM_ SG_ 98 FRS_P1_18_Msg_AliveCounter "Alive counter shall be incremented every radar sensor measurement cycle.";
CM_ SG_ 98 FRS_P1_18_Msg_CheckSum "Check sum shall be generated out of each message content. check sum generation logic is TBC.";
CM_ SG_ 98 FRS_P1_18_Obj_MotionPattern "Motion type of object.
0x00: Unknown
0x01: Stationary
0x02: Stopped
0x03: Moving
0x04: Crossing
0x05-07: reserved";
CM_ SG_ 98 FRS_P1_18_Obj_YPos_Stdev "Estimated 3-sigma standard deviation value of lateral position of the object.";
CM_ SG_ 98 FRS_P1_18_Obj_XVelRel_Stdev "Estimated 3-sigma standard deviation value of the relative longitudinal velocity of the object.";
CM_ SG_ 98 FRS_P1_18_Obj_XPos_Stdev "Estimated 3-sigma standard deviation value of longitudinal position of the object.";
CM_ SG_ 98 FRS_P1_18_Obj_XAccRel "Relative longitudinal acceleration of the object";
CM_ SG_ 98 FRS_P1_18_Obj_ValidFlag "Validity indication flag. when this value shows invalid, all the signals in the corresponding CAN messages except FRS_Msg_AliveCounter and FRS_Msg_CheckSum shall take default values.
0x0: Object invalid
0x1: Object valid";
CM_ SG_ 98 FRS_P1_18_Obj_UpdateFlag "Flag to indicate newly created object in CAN bus.
Object history flag
0x0: new object in the cycle;
0x1: object existed in previous cycle";
CM_ SG_ 98 FRS_P1_18_Obj_ObstacleProb "Estimated probability of the object being an obstacle.";
CM_ SG_ 98 FRS_P1_18_Obj_ID "ID is defined as a unique identification number over the lifetime of the object.
0xFF: Invalid
0x00 - 0xFE: Valid";
CM_ SG_ 98 FRS_P1_18_Obj_ExstProb "Estimated existence probability of the object.";
CM_ SG_ 97 FRS_P1_17_Msg_AliveCounter "Alive counter shall be incremented every radar sensor measurement cycle.";
CM_ SG_ 97 FRS_P1_17_Msg_CheckSum "Check sum shall be generated out of each message content. check sum generation logic is TBC.";
CM_ SG_ 97 FRS_P1_17_Obj_MotionPattern "Motion type of object.
0x00: Unknown
0x01: Stationary
0x02: Stopped
0x03: Moving
0x04: Crossing
0x05-07: reserved";
CM_ SG_ 97 FRS_P1_17_Obj_YPos_Stdev "Estimated 3-sigma standard deviation value of lateral position of the object.";
CM_ SG_ 97 FRS_P1_17_Obj_XVelRel_Stdev "Estimated 3-sigma standard deviation value of the relative longitudinal velocity of the object.";
CM_ SG_ 97 FRS_P1_17_Obj_XPos_Stdev "Estimated 3-sigma standard deviation value of longitudinal position of the object.";
CM_ SG_ 97 FRS_P1_17_Obj_XAccRel "Relative longitudinal acceleration of the object";
CM_ SG_ 97 FRS_P1_17_Obj_ValidFlag "Validity indication flag. when this value shows invalid, all the signals in the corresponding CAN messages except FRS_Msg_AliveCounter and FRS_Msg_CheckSum shall take default values.
0x0: Object invalid
0x1: Object valid";
CM_ SG_ 97 FRS_P1_17_Obj_UpdateFlag "Flag to indicate newly created object in CAN bus.
Object history flag
0x0: new object in the cycle;
0x1: object existed in previous cycle";
CM_ SG_ 97 FRS_P1_17_Obj_ObstacleProb "Estimated probability of the object being an obstacle.";
CM_ SG_ 97 FRS_P1_17_Obj_ID "ID is defined as a unique identification number over the lifetime of the object.
0xFF: Invalid
0x00 - 0xFE: Valid";
CM_ SG_ 97 FRS_P1_17_Obj_ExstProb "Estimated existence probability of the object.";
CM_ SG_ 96 FRS_P1_16_Msg_AliveCounter "Alive counter shall be incremented every radar sensor measurement cycle.";
CM_ SG_ 96 FRS_P1_16_Msg_CheckSum "Check sum shall be generated out of each message content. check sum generation logic is TBC.";
CM_ SG_ 96 FRS_P1_16_Obj_MotionPattern "Motion type of object.
0x00: Unknown
0x01: Stationary
0x02: Stopped
0x03: Moving
0x04: Crossing
0x05-07: reserved";
CM_ SG_ 96 FRS_P1_16_Obj_YPos_Stdev "Estimated 3-sigma standard deviation value of lateral position of the object.";
CM_ SG_ 96 FRS_P1_16_Obj_XVelRel_Stdev "Estimated 3-sigma standard deviation value of the relative longitudinal velocity of the object.";
CM_ SG_ 96 FRS_P1_16_Obj_XPos_Stdev "Estimated 3-sigma standard deviation value of longitudinal position of the object.";
CM_ SG_ 96 FRS_P1_16_Obj_XAccRel "Relative longitudinal acceleration of the object";
CM_ SG_ 96 FRS_P1_16_Obj_ValidFlag "Validity indication flag. when this value shows invalid, all the signals in the corresponding CAN messages except FRS_Msg_AliveCounter and FRS_Msg_CheckSum shall take default values.
0x0: Object invalid
0x1: Object valid";
CM_ SG_ 96 FRS_P1_16_Obj_UpdateFlag "Flag to indicate newly created object in CAN bus.
Object history flag
0x0: new object in the cycle;
0x1: object existed in previous cycle";
CM_ SG_ 96 FRS_P1_16_Obj_ObstacleProb "Estimated probability of the object being an obstacle.";
CM_ SG_ 96 FRS_P1_16_Obj_ID "ID is defined as a unique identification number over the lifetime of the object.
0xFF: Invalid
0x00 - 0xFE: Valid";
CM_ SG_ 96 FRS_P1_16_Obj_ExstProb "Estimated existence probability of the object.";
CM_ SG_ 95 FRS_P1_15_Msg_AliveCounter "Alive counter shall be incremented every radar sensor measurement cycle.";
CM_ SG_ 95 FRS_P1_15_Msg_CheckSum "Check sum shall be generated out of each message content. check sum generation logic is TBC.";
CM_ SG_ 95 FRS_P1_15_Obj_MotionPattern "Motion type of object.
0x00: Unknown
0x01: Stationary
0x02: Stopped
0x03: Moving
0x04: Crossing
0x05-07: reserved";
CM_ SG_ 95 FRS_P1_15_Obj_YPos_Stdev "Estimated 3-sigma standard deviation value of lateral position of the object.";
CM_ SG_ 95 FRS_P1_15_Obj_XVelRel_Stdev "Estimated 3-sigma standard deviation value of the relative longitudinal velocity of the object.";
CM_ SG_ 95 FRS_P1_15_Obj_XPos_Stdev "Estimated 3-sigma standard deviation value of longitudinal position of the object.";
CM_ SG_ 95 FRS_P1_15_Obj_XAccRel "Relative longitudinal acceleration of the object";
CM_ SG_ 95 FRS_P1_15_Obj_ValidFlag "Validity indication flag. when this value shows invalid, all the signals in the corresponding CAN messages except FRS_Msg_AliveCounter and FRS_Msg_CheckSum shall take default values.
0x0: Object invalid
0x1: Object valid";
CM_ SG_ 95 FRS_P1_15_Obj_UpdateFlag "Flag to indicate newly created object in CAN bus.
Object history flag
0x0: new object in the cycle;
0x1: object existed in previous cycle";
CM_ SG_ 95 FRS_P1_15_Obj_ObstacleProb "Estimated probability of the object being an obstacle.";
CM_ SG_ 95 FRS_P1_15_Obj_ID "ID is defined as a unique identification number over the lifetime of the object.
0xFF: Invalid
0x00 - 0xFE: Valid";
CM_ SG_ 95 FRS_P1_15_Obj_ExstProb "Estimated existence probability of the object.";
CM_ SG_ 94 FRS_P1_14_Msg_AliveCounter "Alive counter shall be incremented every radar sensor measurement cycle.";
CM_ SG_ 94 FRS_P1_14_Msg_CheckSum "Check sum shall be generated out of each message content. check sum generation logic is TBC.";
CM_ SG_ 94 FRS_P1_14_Obj_MotionPattern "Motion type of object.
0x00: Unknown
0x01: Stationary
0x02: Stopped
0x03: Moving
0x04: Crossing
0x05-07: reserved";
CM_ SG_ 94 FRS_P1_14_Obj_YPos_Stdev "Estimated 3-sigma standard deviation value of lateral position of the object.";
CM_ SG_ 94 FRS_P1_14_Obj_XVelRel_Stdev "Estimated 3-sigma standard deviation value of the relative longitudinal velocity of the object.";
CM_ SG_ 94 FRS_P1_14_Obj_XPos_Stdev "Estimated 3-sigma standard deviation value of longitudinal position of the object.";
CM_ SG_ 94 FRS_P1_14_Obj_XAccRel "Relative longitudinal acceleration of the object";
CM_ SG_ 94 FRS_P1_14_Obj_ValidFlag "Validity indication flag. when this value shows invalid, all the signals in the corresponding CAN messages except FRS_Msg_AliveCounter and FRS_Msg_CheckSum shall take default values.
0x0: Object invalid
0x1: Object valid";
CM_ SG_ 94 FRS_P1_14_Obj_UpdateFlag "Flag to indicate newly created object in CAN bus.
Object history flag
0x0: new object in the cycle;
0x1: object existed in previous cycle";
CM_ SG_ 94 FRS_P1_14_Obj_ObstacleProb "Estimated probability of the object being an obstacle.";
CM_ SG_ 94 FRS_P1_14_Obj_ID "ID is defined as a unique identification number over the lifetime of the object.
0xFF: Invalid
0x00 - 0xFE: Valid";
CM_ SG_ 94 FRS_P1_14_Obj_ExstProb "Estimated existence probability of the object.";
CM_ SG_ 93 FRS_P1_13_Msg_AliveCounter "Alive counter shall be incremented every radar sensor measurement cycle.";
CM_ SG_ 93 FRS_P1_13_Msg_CheckSum "Check sum shall be generated out of each message content. check sum generation logic is TBC.";
CM_ SG_ 93 FRS_P1_13_Obj_MotionPattern "Motion type of object.
0x00: Unknown
0x01: Stationary
0x02: Stopped
0x03: Moving
0x04: Crossing
0x05-07: reserved";
CM_ SG_ 93 FRS_P1_13_Obj_YPos_Stdev "Estimated 3-sigma standard deviation value of lateral position of the object.";
CM_ SG_ 93 FRS_P1_13_Obj_XVelRel_Stdev "Estimated 3-sigma standard deviation value of the relative longitudinal velocity of the object.";
CM_ SG_ 93 FRS_P1_13_Obj_XPos_Stdev "Estimated 3-sigma standard deviation value of longitudinal position of the object.";
CM_ SG_ 93 FRS_P1_13_Obj_XAccRel "Relative longitudinal acceleration of the object";
CM_ SG_ 93 FRS_P1_13_Obj_ValidFlag "Validity indication flag. when this value shows invalid, all the signals in the corresponding CAN messages except FRS_Msg_AliveCounter and FRS_Msg_CheckSum shall take default values.
0x0: Object invalid
0x1: Object valid";
CM_ SG_ 93 FRS_P1_13_Obj_UpdateFlag "Flag to indicate newly created object in CAN bus.
Object history flag
0x0: new object in the cycle;
0x1: object existed in previous cycle";
CM_ SG_ 93 FRS_P1_13_Obj_ObstacleProb "Estimated probability of the object being an obstacle.";
CM_ SG_ 93 FRS_P1_13_Obj_ID "ID is defined as a unique identification number over the lifetime of the object.
0xFF: Invalid
0x00 - 0xFE: Valid";
CM_ SG_ 93 FRS_P1_13_Obj_ExstProb "Estimated existence probability of the object.";
CM_ SG_ 92 FRS_P1_12_Msg_AliveCounter "Alive counter shall be incremented every radar sensor measurement cycle.";
CM_ SG_ 92 FRS_P1_12_Msg_CheckSum "Check sum shall be generated out of each message content. check sum generation logic is TBC.";
CM_ SG_ 92 FRS_P1_12_Obj_MotionPattern "Motion type of object.
0x00: Unknown
0x01: Stationary
0x02: Stopped
0x03: Moving
0x04: Crossing
0x05-07: reserved";
CM_ SG_ 92 FRS_P1_12_Obj_YPos_Stdev "Estimated 3-sigma standard deviation value of lateral position of the object.";
CM_ SG_ 92 FRS_P1_12_Obj_XVelRel_Stdev "Estimated 3-sigma standard deviation value of the relative longitudinal velocity of the object.";
CM_ SG_ 92 FRS_P1_12_Obj_XPos_Stdev "Estimated 3-sigma standard deviation value of longitudinal position of the object.";
CM_ SG_ 92 FRS_P1_12_Obj_XAccRel "Relative longitudinal acceleration of the object";
CM_ SG_ 92 FRS_P1_12_Obj_ValidFlag "Validity indication flag. when this value shows invalid, all the signals in the corresponding CAN messages except FRS_Msg_AliveCounter and FRS_Msg_CheckSum shall take default values.
0x0: Object invalid
0x1: Object valid";
CM_ SG_ 92 FRS_P1_12_Obj_UpdateFlag "Flag to indicate newly created object in CAN bus.
Object history flag
0x0: new object in the cycle;
0x1: object existed in previous cycle";
CM_ SG_ 92 FRS_P1_12_Obj_ObstacleProb "Estimated probability of the object being an obstacle.";
CM_ SG_ 92 FRS_P1_12_Obj_ID "ID is defined as a unique identification number over the lifetime of the object.
0xFF: Invalid
0x00 - 0xFE: Valid";
CM_ SG_ 92 FRS_P1_12_Obj_ExstProb "Estimated existence probability of the object.";
CM_ SG_ 90 FRS_P1_10_Obj_YPos_Stdev "Estimated 3-sigma standard deviation value of lateral position of the object.";
CM_ SG_ 90 FRS_P1_10_Obj_XVelRel_Stdev "Estimated 3-sigma standard deviation value of the relative longitudinal velocity of the object.";
CM_ SG_ 90 FRS_P1_10_Obj_XPos_Stdev "Estimated 3-sigma standard deviation value of longitudinal position of the object.";
CM_ SG_ 90 FRS_P1_10_Obj_XAccRel "Relative longitudinal acceleration of the object";
CM_ SG_ 90 FRS_P1_10_Obj_ValidFlag "Validity indication flag. when this value shows invalid, all the signals in the corresponding CAN messages except FRS_Msg_AliveCounter and FRS_Msg_CheckSum shall take default values.
0x0: Object invalid
0x1: Object valid";
CM_ SG_ 90 FRS_P1_10_Obj_UpdateFlag "Flag to indicate newly created object in CAN bus.
Object history flag
0x0: new object in the cycle;
0x1: object existed in previous cycle";
CM_ SG_ 90 FRS_P1_10_Obj_ObstacleProb "Estimated probability of the object being an obstacle.";
CM_ SG_ 90 FRS_P1_10_Obj_MotionPattern "Motion type of object.
0x00: Unknown
0x01: Stationary
0x02: Stopped
0x03: Moving
0x04: Crossing
0x05-07: reserved";
CM_ SG_ 90 FRS_P1_10_Obj_ID "ID is defined as a unique identification number over the lifetime of the object.
0xFF: Invalid
0x00 - 0xFE: Valid";
CM_ SG_ 90 FRS_P1_10_Obj_ExstProb "Estimated existence probability of the object.";
CM_ SG_ 90 FRS_P1_10_Msg_CheckSum "Check sum shall be generated out of each message content. check sum generation logic is TBC.";
CM_ SG_ 90 FRS_P1_10_Msg_AliveCounter "Alive counter shall be incremented every radar sensor measurement cycle.";
CM_ SG_ 89 FRS_P1_09_Msg_AliveCounter "Alive counter shall be incremented every radar sensor measurement cycle.";
CM_ SG_ 89 FRS_P1_09_Msg_CheckSum "Check sum shall be generated out of each message content. check sum generation logic is TBC.";
CM_ SG_ 89 FRS_P1_09_Obj_MotionPattern "Motion type of object.
0x00: Unknown
0x01: Stationary
0x02: Stopped
0x03: Moving
0x04: Crossing
0x05-07: reserved";
CM_ SG_ 89 FRS_P1_09_Obj_YPos_Stdev "Estimated 3-sigma standard deviation value of lateral position of the object.";
CM_ SG_ 89 FRS_P1_09_Obj_XVelRel_Stdev "Estimated 3-sigma standard deviation value of the relative longitudinal velocity of the object.";
CM_ SG_ 89 FRS_P1_09_Obj_XPos_Stdev "Estimated 3-sigma standard deviation value of longitudinal position of the object.";
CM_ SG_ 89 FRS_P1_09_Obj_XAccRel "Relative longitudinal acceleration of the object";
CM_ SG_ 89 FRS_P1_09_Obj_ValidFlag "Validity indication flag. when this value shows invalid, all the signals in the corresponding CAN messages except FRS_Msg_AliveCounter and FRS_Msg_CheckSum shall take default values.
0x0: Object invalid
0x1: Object valid";
CM_ SG_ 89 FRS_P1_09_Obj_UpdateFlag "Flag to indicate newly created object in CAN bus.
Object history flag
0x0: new object in the cycle;
0x1: object existed in previous cycle";
CM_ SG_ 89 FRS_P1_09_Obj_ObstacleProb "Estimated probability of the object being an obstacle.";
CM_ SG_ 89 FRS_P1_09_Obj_ID "ID is defined as a unique identification number over the lifetime of the object.
0xFF: Invalid
0x00 - 0xFE: Valid";
CM_ SG_ 89 FRS_P1_09_Obj_ExstProb "Estimated existence probability of the object.";
CM_ SG_ 88 FRS_P1_08_Msg_AliveCounter "Alive counter shall be incremented every radar sensor measurement cycle.";
CM_ SG_ 88 FRS_P1_08_Msg_CheckSum "Check sum shall be generated out of each message content. check sum generation logic is TBC.";
CM_ SG_ 88 FRS_P1_08_Obj_MotionPattern "Motion type of object.
0x00: Unknown
0x01: Stationary
0x02: Stopped
0x03: Moving
0x04: Crossing
0x05-07: reserved";
CM_ SG_ 88 FRS_P1_08_Obj_YPos_Stdev "Estimated 3-sigma standard deviation value of lateral position of the object.";
CM_ SG_ 88 FRS_P1_08_Obj_XVelRel_Stdev "Estimated 3-sigma standard deviation value of the relative longitudinal velocity of the object.";
CM_ SG_ 88 FRS_P1_08_Obj_XPos_Stdev "Estimated 3-sigma standard deviation value of longitudinal position of the object.";
CM_ SG_ 88 FRS_P1_08_Obj_XAccRel "Relative longitudinal acceleration of the object";
CM_ SG_ 88 FRS_P1_08_Obj_ValidFlag "Validity indication flag. when this value shows invalid, all the signals in the corresponding CAN messages except FRS_Msg_AliveCounter and FRS_Msg_CheckSum shall take default values.
0x0: Object invalid
0x1: Object valid";
CM_ SG_ 88 FRS_P1_08_Obj_UpdateFlag "Flag to indicate newly created object in CAN bus.
Object history flag
0x0: new object in the cycle;
0x1: object existed in previous cycle";
CM_ SG_ 88 FRS_P1_08_Obj_ObstacleProb "Estimated probability of the object being an obstacle.";
CM_ SG_ 88 FRS_P1_08_Obj_ID "ID is defined as a unique identification number over the lifetime of the object.
0xFF: Invalid
0x00 - 0xFE: Valid";
CM_ SG_ 88 FRS_P1_08_Obj_ExstProb "Estimated existence probability of the object.";
CM_ SG_ 87 FRS_P1_07_Msg_AliveCounter "Alive counter shall be incremented every radar sensor measurement cycle.";
CM_ SG_ 87 FRS_P1_07_Msg_CheckSum "Check sum shall be generated out of each message content. check sum generation logic is TBC.";
CM_ SG_ 87 FRS_P1_07_Obj_MotionPattern "Motion type of object.
0x00: Unknown
0x01: Stationary
0x02: Stopped
0x03: Moving
0x04: Crossing
0x05-07: reserved";
CM_ SG_ 87 FRS_P1_07_Obj_YPos_Stdev "Estimated 3-sigma standard deviation value of lateral position of the object.";
CM_ SG_ 87 FRS_P1_07_Obj_XVelRel_Stdev "Estimated 3-sigma standard deviation value of the relative longitudinal velocity of the object.";
CM_ SG_ 87 FRS_P1_07_Obj_XPos_Stdev "Estimated 3-sigma standard deviation value of longitudinal position of the object.";
CM_ SG_ 87 FRS_P1_07_Obj_XAccRel "Relative longitudinal acceleration of the object";
CM_ SG_ 87 FRS_P1_07_Obj_ValidFlag "Validity indication flag. when this value shows invalid, all the signals in the corresponding CAN messages except FRS_Msg_AliveCounter and FRS_Msg_CheckSum shall take default values.
0x0: Object invalid
0x1: Object valid";
CM_ SG_ 87 FRS_P1_07_Obj_UpdateFlag "Flag to indicate newly created object in CAN bus.
Object history flag
0x0: new object in the cycle;
0x1: object existed in previous cycle";
CM_ SG_ 87 FRS_P1_07_Obj_ObstacleProb "Estimated probability of the object being an obstacle.";
CM_ SG_ 87 FRS_P1_07_Obj_ID "ID is defined as a unique identification number over the lifetime of the object.
0xFF: Invalid
0x00 - 0xFE: Valid";
CM_ SG_ 87 FRS_P1_07_Obj_ExstProb "Estimated existence probability of the object.";
CM_ SG_ 86 FRS_P1_06_Msg_AliveCounter "Alive counter shall be incremented every radar sensor measurement cycle.";
CM_ SG_ 86 FRS_P1_06_Msg_CheckSum "Check sum shall be generated out of each message content. check sum generation logic is TBC.";
CM_ SG_ 86 FRS_P1_06_Obj_MotionPattern "Motion type of object.
0x00: Unknown
0x01: Stationary
0x02: Stopped
0x03: Moving
0x04: Crossing
0x05-07: reserved";
CM_ SG_ 86 FRS_P1_06_Obj_YPos_Stdev "Estimated 3-sigma standard deviation value of lateral position of the object.";
CM_ SG_ 86 FRS_P1_06_Obj_XVelRel_Stdev "Estimated 3-sigma standard deviation value of the relative longitudinal velocity of the object.";
CM_ SG_ 86 FRS_P1_06_Obj_XPos_Stdev "Estimated 3-sigma standard deviation value of longitudinal position of the object.";
CM_ SG_ 86 FRS_P1_06_Obj_XAccRel "Relative longitudinal acceleration of the object";
CM_ SG_ 86 FRS_P1_06_Obj_ValidFlag "Validity indication flag. when this value shows invalid, all the signals in the corresponding CAN messages except FRS_Msg_AliveCounter and FRS_Msg_CheckSum shall take default values.
0x0: Object invalid
0x1: Object valid";
CM_ SG_ 86 FRS_P1_06_Obj_UpdateFlag "Flag to indicate newly created object in CAN bus.
Object history flag
0x0: new object in the cycle;
0x1: object existed in previous cycle";
CM_ SG_ 86 FRS_P1_06_Obj_ObstacleProb "Estimated probability of the object being an obstacle.";
CM_ SG_ 86 FRS_P1_06_Obj_ID "ID is defined as a unique identification number over the lifetime of the object.
0xFF: Invalid
0x00 - 0xFE: Valid";
CM_ SG_ 86 FRS_P1_06_Obj_ExstProb "Estimated existence probability of the object.";
CM_ SG_ 85 FRS_P1_05_Msg_AliveCounter "Alive counter shall be incremented every radar sensor measurement cycle.";
CM_ SG_ 85 FRS_P1_05_Msg_CheckSum "Check sum shall be generated out of each message content. check sum generation logic is TBC.";
CM_ SG_ 85 FRS_P1_05_Obj_MotionPattern "Motion type of object.
0x00: Unknown
0x01: Stationary
0x02: Stopped
0x03: Moving
0x04: Crossing
0x05-07: reserved";
CM_ SG_ 85 FRS_P1_05_Obj_YPos_Stdev "Estimated 3-sigma standard deviation value of lateral position of the object.";
CM_ SG_ 85 FRS_P1_05_Obj_XVelRel_Stdev "Estimated 3-sigma standard deviation value of the relative longitudinal velocity of the object.";
CM_ SG_ 85 FRS_P1_05_Obj_XPos_Stdev "Estimated 3-sigma standard deviation value of longitudinal position of the object.";
CM_ SG_ 85 FRS_P1_05_Obj_XAccRel "Relative longitudinal acceleration of the object";
CM_ SG_ 85 FRS_P1_05_Obj_ValidFlag "Validity indication flag. when this value shows invalid, all the signals in the corresponding CAN messages except FRS_Msg_AliveCounter and FRS_Msg_CheckSum shall take default values.
0x0: Object invalid
0x1: Object valid";
CM_ SG_ 85 FRS_P1_05_Obj_UpdateFlag "Flag to indicate newly created object in CAN bus.
Object history flag
0x0: new object in the cycle;
0x1: object existed in previous cycle";
CM_ SG_ 85 FRS_P1_05_Obj_ObstacleProb "Estimated probability of the object being an obstacle.";
CM_ SG_ 85 FRS_P1_05_Obj_ID "ID is defined as a unique identification number over the lifetime of the object.
0xFF: Invalid
0x00 - 0xFE: Valid";
CM_ SG_ 85 FRS_P1_05_Obj_ExstProb "Estimated existence probability of the object.";
CM_ SG_ 84 FRS_P1_04_Msg_AliveCounter "Alive counter shall be incremented every radar sensor measurement cycle.";
CM_ SG_ 84 FRS_P1_04_Msg_CheckSum "Check sum shall be generated out of each message content. check sum generation logic is TBC.";
CM_ SG_ 84 FRS_P1_04_Obj_MotionPattern "Motion type of object.
0x00: Unknown
0x01: Stationary
0x02: Stopped
0x03: Moving
0x04: Crossing
0x05-07: reserved";
CM_ SG_ 84 FRS_P1_04_Obj_YPos_Stdev "Estimated 3-sigma standard deviation value of lateral position of the object.";
CM_ SG_ 84 FRS_P1_04_Obj_XVelRel_Stdev "Estimated 3-sigma standard deviation value of the relative longitudinal velocity of the object.";
CM_ SG_ 84 FRS_P1_04_Obj_XPos_Stdev "Estimated 3-sigma standard deviation value of longitudinal position of the object.";
CM_ SG_ 84 FRS_P1_04_Obj_XAccRel "Relative longitudinal acceleration of the object";
CM_ SG_ 84 FRS_P1_04_Obj_ValidFlag "Validity indication flag. when this value shows invalid, all the signals in the corresponding CAN messages except FRS_Msg_AliveCounter and FRS_Msg_CheckSum shall take default values.
0x0: Object invalid
0x1: Object valid";
CM_ SG_ 84 FRS_P1_04_Obj_UpdateFlag "Flag to indicate newly created object in CAN bus.
Object history flag
0x0: new object in the cycle;
0x1: object existed in previous cycle";
CM_ SG_ 84 FRS_P1_04_Obj_ObstacleProb "Estimated probability of the object being an obstacle.";
CM_ SG_ 84 FRS_P1_04_Obj_ID "ID is defined as a unique identification number over the lifetime of the object.
0xFF: Invalid
0x00 - 0xFE: Valid";
CM_ SG_ 84 FRS_P1_04_Obj_ExstProb "Estimated existence probability of the object.";
CM_ SG_ 83 FRS_P1_03_Msg_AliveCounter "Alive counter shall be incremented every radar sensor measurement cycle.";
CM_ SG_ 83 FRS_P1_03_Msg_CheckSum "Check sum shall be generated out of each message content. check sum generation logic is TBC.";
CM_ SG_ 83 FRS_P1_03_Obj_MotionPattern "Motion type of object.
0x00: Unknown
0x01: Stationary
0x02: Stopped
0x03: Moving
0x04: Crossing
0x05-07: reserved";
CM_ SG_ 83 FRS_P1_03_Obj_YPos_Stdev "Estimated 3-sigma standard deviation value of lateral position of the object.";
CM_ SG_ 83 FRS_P1_03_Obj_XVelRel_Stdev "Estimated 3-sigma standard deviation value of the relative longitudinal velocity of the object.";
CM_ SG_ 83 FRS_P1_03_Obj_XPos_Stdev "Estimated 3-sigma standard deviation value of longitudinal position of the object.";
CM_ SG_ 83 FRS_P1_03_Obj_XAccRel "Relative longitudinal acceleration of the object";
CM_ SG_ 83 FRS_P1_03_Obj_ValidFlag "Validity indication flag. when this value shows invalid, all the signals in the corresponding CAN messages except FRS_Msg_AliveCounter and FRS_Msg_CheckSum shall take default values.
0x0: Object invalid
0x1: Object valid";
CM_ SG_ 83 FRS_P1_03_Obj_UpdateFlag "Flag to indicate newly created object in CAN bus.
Object history flag
0x0: new object in the cycle;
0x1: object existed in previous cycle";
CM_ SG_ 83 FRS_P1_03_Obj_ObstacleProb "Estimated probability of the object being an obstacle.";
CM_ SG_ 83 FRS_P1_03_Obj_ID "ID is defined as a unique identification number over the lifetime of the object.
0xFF: Invalid
0x00 - 0xFE: Valid";
CM_ SG_ 83 FRS_P1_03_Obj_ExstProb "Estimated existence probability of the object.";
CM_ SG_ 82 FRS_P1_02_Msg_AliveCounter "Alive counter shall be incremented every radar sensor measurement cycle.";
CM_ SG_ 82 FRS_P1_02_Msg_CheckSum "Check sum shall be generated out of each message content. check sum generation logic is TBC.";
CM_ SG_ 82 FRS_P1_02_Obj_MotionPattern "Motion type of object.
0x00: Unknown
0x01: Stationary
0x02: Stopped
0x03: Moving
0x04: Crossing
0x05-07: reserved";
CM_ SG_ 82 FRS_P1_02_Obj_YPos_Stdev "Estimated 3-sigma standard deviation value of lateral position of the object.";
CM_ SG_ 82 FRS_P1_02_Obj_XVelRel_Stdev "Estimated 3-sigma standard deviation value of the relative longitudinal velocity of the object.";
CM_ SG_ 82 FRS_P1_02_Obj_XPos_Stdev "Estimated 3-sigma standard deviation value of longitudinal position of the object.";
CM_ SG_ 82 FRS_P1_02_Obj_XAccRel "Relative longitudinal acceleration of the object";
CM_ SG_ 82 FRS_P1_02_Obj_ValidFlag "Validity indication flag. when this value shows invalid, all the signals in the corresponding CAN messages except FRS_Msg_AliveCounter and FRS_Msg_CheckSum shall take default values.
0x0: Object invalid
0x1: Object valid";
CM_ SG_ 82 FRS_P1_02_Obj_UpdateFlag "Flag to indicate newly created object in CAN bus.
Object history flag
0x0: new object in the cycle;
0x1: object existed in previous cycle";
CM_ SG_ 82 FRS_P1_02_Obj_ObstacleProb "Estimated probability of the object being an obstacle.";
CM_ SG_ 82 FRS_P1_02_Obj_ID "ID is defined as a unique identification number over the lifetime of the object.
0xFF: Invalid
0x00 - 0xFE: Valid";
CM_ SG_ 82 FRS_P1_02_Obj_ExstProb "Estimated existence probability of the object.";
CM_ SG_ 81 FRS_P1_01_Msg_AliveCounter "Alive counter shall be incremented every radar sensor measurement cycle.";
CM_ SG_ 81 FRS_P1_01_Msg_CheckSum "Check sum shall be generated out of each message content. check sum generation logic is TBC.";
CM_ SG_ 81 FRS_P1_01_Obj_MotionPattern "Motion type of object.
0x00: Unknown
0x01: Stationary
0x02: Stopped
0x03: Moving
0x04: Crossing
0x05-07: reserved";
CM_ SG_ 81 FRS_P1_01_Obj_YPos_Stdev "Estimated 3-sigma standard deviation value of lateral position of the object.";
CM_ SG_ 81 FRS_P1_01_Obj_XVelRel_Stdev "Estimated 3-sigma standard deviation value of the relative longitudinal velocity of the object.";
CM_ SG_ 81 FRS_P1_01_Obj_XPos_Stdev "Estimated 3-sigma standard deviation value of longitudinal position of the object.";
CM_ SG_ 81 FRS_P1_01_Obj_XAccRel "Relative longitudinal acceleration of the object";
CM_ SG_ 81 FRS_P1_01_Obj_ValidFlag "Validity indication flag. when this value shows invalid, all the signals in the corresponding CAN messages except FRS_Msg_AliveCounter and FRS_Msg_CheckSum shall take default values.
0x0: Object invalid
0x1: Object valid";
CM_ SG_ 81 FRS_P1_01_Obj_UpdateFlag "Flag to indicate newly created object in CAN bus.
Object history flag
0x0: new object in the cycle;
0x1: object existed in previous cycle";
CM_ SG_ 81 FRS_P1_01_Obj_ObstacleProb "Estimated probability of the object being an obstacle.";
CM_ SG_ 81 FRS_P1_01_Obj_ID "ID is defined as a unique identification number over the lifetime of the object.
0xFF: Invalid
0x00 - 0xFE: Valid";
CM_ SG_ 81 FRS_P1_01_Obj_ExstProb "Estimated existence probability of the object.";
CM_ SG_ 32 FRS_P2_00_Obj_YVelRel "Relative lateral velocity of the object";
CM_ SG_ 32 FRS_P2_00_Obj_YPos "Position of target object in lateral direction
center of vehicle rear axle shaft is reference point.";
CM_ SG_ 32 FRS_P2_00_Obj_XVelRel "Relative longitudinal velocity of the object.";
CM_ SG_ 32 FRS_P2_00_Obj_XPos "Position of target object in longitudinal direction
center of vehicle rear axle shaft is reference point.";
CM_ SG_ 32 FRS_P2_00_Obj_Type "To indicate the estimated type of Object
0x00: Unknown
0x01: 4 wheeler
0x02: 2 wheeler
0x03: Pedestrian";
CM_ SG_ 32 FRS_P2_00_Obj_MeasFlag "This signal indicates whether the latest sensor measurement observed the object or extrapolated.
0x0: object measured in this cycle
0x1: object extrapolated in this cycle";
CM_ SG_ 32 FRS_P2_00_Msg_AliveCounter "Alive counter shall be incremented every radar sensor measurement cycle.";
CM_ SG_ 32 FRS_P2_00_Msg_CheckSum "Check sum shall be generated out of each message content. check sum generation logic is TBC.";
CM_ SG_ 80 FRS_P1_00_Msg_AliveCounter "Alive counter shall be incremented every radar sensor measurement cycle.";
CM_ SG_ 80 FRS_P1_00_Msg_CheckSum "Check sum shall be generated out of each message content. check sum generation logic is TBC.";
CM_ SG_ 80 FRS_P1_00_Obj_MotionPattern "Motion type of object.
0x00: Unknown
0x01: Stationary
0x02: Stopped
0x03: Moving
0x04: Crossing
0x05-07: reserved";
CM_ SG_ 80 FRS_P1_00_Obj_YPos_Stdev "Estimated 3-sigma standard deviation value of lateral position of the object.";
CM_ SG_ 80 FRS_P1_00_Obj_XVelRel_Stdev "Estimated 3-sigma standard deviation value of the relative longitudinal velocity of the object.";
CM_ SG_ 80 FRS_P1_00_Obj_XPos_Stdev "Estimated 3-sigma standard deviation value of longitudinal position of the object.";
CM_ SG_ 80 FRS_P1_00_Obj_XAccRel "Relative longitudinal acceleration of the object";
CM_ SG_ 80 FRS_P1_00_Obj_ValidFlag "Validity indication flag. when this value shows invalid, all the signals in the corresponding CAN messages except FRS_Msg_AliveCounter and FRS_Msg_CheckSum shall take default values.
0x0: Object invalid
0x1: Object valid";
CM_ SG_ 80 FRS_P1_00_Obj_UpdateFlag "Flag to indicate newly created object in CAN bus.
Object history flag
0x0: new object in the cycle;
0x1: object existed in previous cycle";
CM_ SG_ 80 FRS_P1_00_Obj_ObstacleProb "Estimated probability of the object being an obstacle.";
CM_ SG_ 80 FRS_P1_00_Obj_ID "ID is defined as a unique identification number over the lifetime of the object.
0xFF: Invalid
0x00 - 0xFE: Valid";
CM_ SG_ 80 FRS_P1_00_Obj_ExstProb "Estimated existence probability of the object.";
CM_ BO_ 128 "FRS_Status";
CM_ SG_ 128 FRS_Msg_CheckSum "Check sum shall be generated out of each message content. check sum generation logic is TBC.";
CM_ SG_ 128 FRS_Status_MisAlign "This signal indicates radar sensor mis-alignment status.
0x00:unknown
0x01:calibrated
0x02:sensor mis-alignment detected
0x03:calibration in progress
0x04:uncalibratable
0x05-07:  reserved";
CM_ SG_ 128 FRS_Status_HWErr "Flag to indicate if HW is failed or not.
0x0:HW is NOT failed
0x1:HW is failed";
CM_ SG_ 128 FRS_Status_BlkProg "Sensor blockage status indication.
0x0: FRS is NOT blocked
0x1: FRS is blocked";
CM_ SG_ 128 FRS_MeasEnabled "This signal indicates if the radar sensor is performing measurement or not. (radio-wave emission or not) Since Conti does not have this, it could be setup as the same as FRS_Fail.
";
CM_ SG_ 128 FRS_Host_Yaw "Host vehicle yaw rate in deg/s which is used for radar object tracking (calibrated host yaw rate if sensor has calibration capability).
Left turn is defined as FRS_Host_Yaw positive direction.";
CM_ SG_ 128 FRS_Fail "This signal indicates if radar is working or not.
0x0 = FRS radar is NOT working
0x1 = FRS radar is working";
CM_ SG_ 128 FRS_TimeStamp "Sensor internal time stamp since the last sensor start up. the time stamp shall loop as it overflows.";
CM_ SG_ 128 FRS_HostSpeed "Host vehicle over-ground speed which is used for radar object tracking (calibrated host velocity if the sensor has calibaration capability).
Forward movement is defined as FRS_HostSpeed positive direction.";
CM_ SG_ 128 FRS_Msg_AliveCounter "Alive counter shall be incremented every radar sensor measurement cycle.";
CM_ SG_ 128 FRS_Latency "Radar process latency in ms from radio-wave reflection observation to CAN message transmission for current cycle.";
CM_ SG_ 1281 MCU_Temperature_too_high "MCU temperature too high";
CM_ SG_ 1281 MCU_Temperature_too_low "MCU temperature too low";
CM_ SG_ 1281 MCU_Voltage_too_high "MCU voltage too high";
CM_ SG_ 1281 MCU_Voltage_too_low "MCU voltage too low";
CM_ SG_ 1281 Battery_Voltage_too_high "Battery voltage too high";
CM_ SG_ 1281 Battery_Voltage_too_low "Battery voltage too low";
CM_ SG_ 1281 RF_Temperature_too_high "RF temperature too high";
CM_ SG_ 1281 RF_Temperature_too_low "RF temperature too low";
CM_ SG_ 1281 Flash_Error "Flash Error";
CM_ SG_ 1281 RF_Sensor_fault "RF sensor fault";
CM_ SG_ 1281 Invalid_Vehicle_Speed_signal "lost Vehicle Speed signal";
CM_ SG_ 1281 Invalid_Yaw_Rate_signal "lost Yaw Rate signal";
CM_ SG_ 1281 Invalid_Steering_Angle_signal "lost Steering Angle signal";
CM_ SG_ 1281 Invalid_Gear_position_signal "lost Gear position signal";
CM_ SG_ 1281 Radar_block "Radar block";
CM_ SG_ 1281 misalignment_error "misalignment error";
BA_DEF_ BO_  "GenMsgCycleTime" INT 0 50000;
BA_DEF_ BO_  "GenMsgILSupport" ENUM  "No","Yes";
BA_DEF_ BO_  "GenMsgSendType" ENUM  "Cyclic","NotUsed","NotUsed","NotUsed","NotUsed","NotUsed","NotUsed","NotUsed","NoMsgSendType";
BA_DEF_ BO_  "VFrameFormat" ENUM  "StandardCAN","ExtendedCAN","reserved","reserved","reserved","reserved","reserved","reserved","reserved","reserved","reserved","reserved","reserved","reserved","StandardCAN_FD","ExtendedCAN_FD";
BA_DEF_ SG_  "GenSigFuncType" ENUM  "NoFunction","NotUsed","NotUsed","NotUsed","NotUsed","NotUsed","NotUsed","CHK";
BA_DEF_ SG_  "GenSigSendType" ENUM  "Cyclic","OnWrite","NotUsed","OnChange","NotUsed","NotUsed","NotUsed","NoSigSendType";
BA_DEF_ SG_  "GenSigStartValue" FLOAT 0 1215752192;
BA_DEF_ SG_  "GenSigTimeoutValue" INT 0 100000;
BA_DEF_DEF_  "GenMsgCycleTime" 100;
BA_DEF_DEF_  "GenMsgILSupport" "Yes";
BA_DEF_DEF_  "GenMsgSendType" "Cyclic";
BA_DEF_DEF_  "VFrameFormat" "ExtendedCAN_FD";
BA_DEF_DEF_  "GenSigFuncType" "NoFunction";
BA_DEF_DEF_  "GenSigSendType" "NoSigSendType";
BA_DEF_DEF_  "GenSigStartValue" 0;
BA_DEF_DEF_  "GenSigTimeoutValue" 0;
BA_ "GenMsgCycleTime" BO_ 112 60;
BA_ "VFrameFormat" BO_ 112 14;
BA_ "GenMsgCycleTime" BO_ 111 60;
BA_ "VFrameFormat" BO_ 111 14;
BA_ "GenMsgCycleTime" BO_ 110 60;
BA_ "VFrameFormat" BO_ 110 14;
BA_ "GenMsgCycleTime" BO_ 109 60;
BA_ "VFrameFormat" BO_ 109 14;
BA_ "GenMsgCycleTime" BO_ 108 60;
BA_ "VFrameFormat" BO_ 108 14;
BA_ "GenMsgCycleTime" BO_ 107 60;
BA_ "VFrameFormat" BO_ 107 14;
BA_ "GenMsgCycleTime" BO_ 106 60;
BA_ "VFrameFormat" BO_ 106 14;
BA_ "GenMsgCycleTime" BO_ 105 60;
BA_ "VFrameFormat" BO_ 105 14;
BA_ "GenMsgCycleTime" BO_ 104 60;
BA_ "VFrameFormat" BO_ 104 14;
BA_ "GenMsgCycleTime" BO_ 103 60;
BA_ "VFrameFormat" BO_ 103 14;
BA_ "GenMsgCycleTime" BO_ 102 60;
BA_ "VFrameFormat" BO_ 102 14;
BA_ "GenMsgCycleTime" BO_ 101 60;
BA_ "VFrameFormat" BO_ 101 14;
BA_ "GenMsgCycleTime" BO_ 100 60;
BA_ "VFrameFormat" BO_ 100 14;
BA_ "GenMsgCycleTime" BO_ 99 60;
BA_ "VFrameFormat" BO_ 99 14;
BA_ "GenMsgCycleTime" BO_ 98 60;
BA_ "VFrameFormat" BO_ 98 14;
BA_ "GenMsgCycleTime" BO_ 97 60;
BA_ "VFrameFormat" BO_ 97 14;
BA_ "GenMsgCycleTime" BO_ 96 60;
BA_ "VFrameFormat" BO_ 96 14;
BA_ "GenMsgCycleTime" BO_ 95 60;
BA_ "VFrameFormat" BO_ 95 14;
BA_ "GenMsgCycleTime" BO_ 94 60;
BA_ "VFrameFormat" BO_ 94 14;
BA_ "GenMsgCycleTime" BO_ 93 60;
BA_ "VFrameFormat" BO_ 93 14;
BA_ "GenMsgCycleTime" BO_ 92 60;
BA_ "VFrameFormat" BO_ 92 14;
BA_ "GenMsgCycleTime" BO_ 90 60;
BA_ "VFrameFormat" BO_ 90 14;
BA_ "GenMsgCycleTime" BO_ 89 60;
BA_ "VFrameFormat" BO_ 89 14;
BA_ "GenMsgCycleTime" BO_ 88 60;
BA_ "VFrameFormat" BO_ 88 14;
BA_ "GenMsgCycleTime" BO_ 87 60;
BA_ "VFrameFormat" BO_ 87 14;
BA_ "GenMsgCycleTime" BO_ 86 60;
BA_ "VFrameFormat" BO_ 86 14;
BA_ "GenMsgCycleTime" BO_ 85 60;
BA_ "VFrameFormat" BO_ 85 14;
BA_ "GenMsgCycleTime" BO_ 84 60;
BA_ "VFrameFormat" BO_ 84 14;
BA_ "GenMsgCycleTime" BO_ 83 60;
BA_ "VFrameFormat" BO_ 83 14;
BA_ "GenMsgCycleTime" BO_ 82 60;
BA_ "VFrameFormat" BO_ 82 14;
BA_ "GenMsgCycleTime" BO_ 81 60;
BA_ "VFrameFormat" BO_ 81 14;
BA_ "GenMsgCycleTime" BO_ 32 60;
BA_ "VFrameFormat" BO_ 32 14;
BA_ "GenMsgCycleTime" BO_ 80 60;
BA_ "VFrameFormat" BO_ 80 14;
BA_ "GenMsgCycleTime" BO_ 128 60;
BA_ "GenMsgILSupport" BO_ 128 0;
BA_ "VFrameFormat" BO_ 128 14;
BA_ "GenMsgCycleTime" BO_ 1281 60;
BA_ "VFrameFormat" BO_ 1281 0;
BA_ "GenSigTimeoutValue" SG_ 112 FRS_P1_32_Msg_AliveCounter 250;
BA_ "GenSigTimeoutValue" SG_ 112 FRS_P1_32_Msg_CheckSum 250;
BA_ "GenSigTimeoutValue" SG_ 112 FRS_P1_32_Obj_MotionPattern 250;
BA_ "GenSigTimeoutValue" SG_ 112 FRS_P1_32_Obj_YPos_Stdev 250;
BA_ "GenSigTimeoutValue" SG_ 112 FRS_P1_32_Obj_XVelRel_Stdev 250;
BA_ "GenSigTimeoutValue" SG_ 112 FRS_P1_32_Obj_XPos_Stdev 250;
BA_ "GenSigStartValue" SG_ 112 FRS_P1_32_Obj_XAccRel 64;
BA_ "GenSigTimeoutValue" SG_ 112 FRS_P1_32_Obj_XAccRel 250;
BA_ "GenSigTimeoutValue" SG_ 112 FRS_P1_32_Obj_ValidFlag 250;
BA_ "GenSigTimeoutValue" SG_ 112 FRS_P1_32_Obj_UpdateFlag 250;
BA_ "GenSigTimeoutValue" SG_ 112 FRS_P1_32_Obj_ObstacleProb 250;
BA_ "GenSigTimeoutValue" SG_ 112 FRS_P1_32_Obj_ID 250;
BA_ "GenSigTimeoutValue" SG_ 112 FRS_P1_32_Obj_ExstProb 250;
BA_ "GenSigTimeoutValue" SG_ 111 FRS_P1_31_Msg_AliveCounter 250;
BA_ "GenSigTimeoutValue" SG_ 111 FRS_P1_31_Msg_CheckSum 250;
BA_ "GenSigTimeoutValue" SG_ 111 FRS_P1_31_Obj_MotionPattern 250;
BA_ "GenSigTimeoutValue" SG_ 111 FRS_P1_31_Obj_YPos_Stdev 250;
BA_ "GenSigTimeoutValue" SG_ 111 FRS_P1_31_Obj_XVelRel_Stdev 250;
BA_ "GenSigTimeoutValue" SG_ 111 FRS_P1_31_Obj_XPos_Stdev 250;
BA_ "GenSigStartValue" SG_ 111 FRS_P1_31_Obj_XAccRel 64;
BA_ "GenSigTimeoutValue" SG_ 111 FRS_P1_31_Obj_XAccRel 250;
BA_ "GenSigTimeoutValue" SG_ 111 FRS_P1_31_Obj_ValidFlag 250;
BA_ "GenSigTimeoutValue" SG_ 111 FRS_P1_31_Obj_UpdateFlag 250;
BA_ "GenSigTimeoutValue" SG_ 111 FRS_P1_31_Obj_ObstacleProb 250;
BA_ "GenSigTimeoutValue" SG_ 111 FRS_P1_31_Obj_ID 250;
BA_ "GenSigTimeoutValue" SG_ 111 FRS_P1_31_Obj_ExstProb 250;
BA_ "GenSigTimeoutValue" SG_ 110 FRS_P1_30_Msg_AliveCounter 250;
BA_ "GenSigTimeoutValue" SG_ 110 FRS_P1_30_Msg_CheckSum 250;
BA_ "GenSigTimeoutValue" SG_ 110 FRS_P1_30_Obj_MotionPattern 250;
BA_ "GenSigTimeoutValue" SG_ 110 FRS_P1_30_Obj_YPos_Stdev 250;
BA_ "GenSigTimeoutValue" SG_ 110 FRS_P1_30_Obj_XVelRel_Stdev 250;
BA_ "GenSigTimeoutValue" SG_ 110 FRS_P1_30_Obj_XPos_Stdev 250;
BA_ "GenSigStartValue" SG_ 110 FRS_P1_30_Obj_XAccRel 64;
BA_ "GenSigTimeoutValue" SG_ 110 FRS_P1_30_Obj_XAccRel 250;
BA_ "GenSigTimeoutValue" SG_ 110 FRS_P1_30_Obj_ValidFlag 250;
BA_ "GenSigTimeoutValue" SG_ 110 FRS_P1_30_Obj_UpdateFlag 250;
BA_ "GenSigTimeoutValue" SG_ 110 FRS_P1_30_Obj_ObstacleProb 250;
BA_ "GenSigTimeoutValue" SG_ 110 FRS_P1_30_Obj_ID 250;
BA_ "GenSigTimeoutValue" SG_ 110 FRS_P1_30_Obj_ExstProb 250;
BA_ "GenSigTimeoutValue" SG_ 109 FRS_P1_29_Msg_AliveCounter 250;
BA_ "GenSigTimeoutValue" SG_ 109 FRS_P1_29_Msg_CheckSum 250;
BA_ "GenSigTimeoutValue" SG_ 109 FRS_P1_29_Obj_MotionPattern 250;
BA_ "GenSigTimeoutValue" SG_ 109 FRS_P1_29_Obj_YPos_Stdev 250;
BA_ "GenSigTimeoutValue" SG_ 109 FRS_P1_29_Obj_XVelRel_Stdev 250;
BA_ "GenSigTimeoutValue" SG_ 109 FRS_P1_29_Obj_XPos_Stdev 250;
BA_ "GenSigStartValue" SG_ 109 FRS_P1_29_Obj_XAccRel 64;
BA_ "GenSigTimeoutValue" SG_ 109 FRS_P1_29_Obj_XAccRel 250;
BA_ "GenSigTimeoutValue" SG_ 109 FRS_P1_29_Obj_ValidFlag 250;
BA_ "GenSigTimeoutValue" SG_ 109 FRS_P1_29_Obj_UpdateFlag 250;
BA_ "GenSigTimeoutValue" SG_ 109 FRS_P1_29_Obj_ObstacleProb 250;
BA_ "GenSigTimeoutValue" SG_ 109 FRS_P1_29_Obj_ID 250;
BA_ "GenSigTimeoutValue" SG_ 109 FRS_P1_29_Obj_ExstProb 250;
BA_ "GenSigTimeoutValue" SG_ 108 FRS_P1_28_Msg_AliveCounter 250;
BA_ "GenSigTimeoutValue" SG_ 108 FRS_P1_28_Msg_CheckSum 250;
BA_ "GenSigTimeoutValue" SG_ 108 FRS_P1_28_Obj_MotionPattern 250;
BA_ "GenSigTimeoutValue" SG_ 108 FRS_P1_28_Obj_YPos_Stdev 250;
BA_ "GenSigTimeoutValue" SG_ 108 FRS_P1_28_Obj_XVelRel_Stdev 250;
BA_ "GenSigTimeoutValue" SG_ 108 FRS_P1_28_Obj_XPos_Stdev 250;
BA_ "GenSigStartValue" SG_ 108 FRS_P1_28_Obj_XAccRel 64;
BA_ "GenSigTimeoutValue" SG_ 108 FRS_P1_28_Obj_XAccRel 250;
BA_ "GenSigTimeoutValue" SG_ 108 FRS_P1_28_Obj_ValidFlag 250;
BA_ "GenSigTimeoutValue" SG_ 108 FRS_P1_28_Obj_UpdateFlag 250;
BA_ "GenSigTimeoutValue" SG_ 108 FRS_P1_28_Obj_ObstacleProb 250;
BA_ "GenSigTimeoutValue" SG_ 108 FRS_P1_28_Obj_ID 250;
BA_ "GenSigTimeoutValue" SG_ 108 FRS_P1_28_Obj_ExstProb 250;
BA_ "GenSigTimeoutValue" SG_ 107 FRS_P1_27_Msg_AliveCounter 250;
BA_ "GenSigTimeoutValue" SG_ 107 FRS_P1_27_Msg_CheckSum 250;
BA_ "GenSigTimeoutValue" SG_ 107 FRS_P1_27_Obj_MotionPattern 250;
BA_ "GenSigTimeoutValue" SG_ 107 FRS_P1_27_Obj_YPos_Stdev 250;
BA_ "GenSigTimeoutValue" SG_ 107 FRS_P1_27_Obj_XVelRel_Stdev 250;
BA_ "GenSigTimeoutValue" SG_ 107 FRS_P1_27_Obj_XPos_Stdev 250;
BA_ "GenSigStartValue" SG_ 107 FRS_P1_27_Obj_XAccRel 64;
BA_ "GenSigTimeoutValue" SG_ 107 FRS_P1_27_Obj_XAccRel 250;
BA_ "GenSigTimeoutValue" SG_ 107 FRS_P1_27_Obj_ValidFlag 250;
BA_ "GenSigTimeoutValue" SG_ 107 FRS_P1_27_Obj_UpdateFlag 250;
BA_ "GenSigTimeoutValue" SG_ 107 FRS_P1_27_Obj_ObstacleProb 250;
BA_ "GenSigTimeoutValue" SG_ 107 FRS_P1_27_Obj_ID 250;
BA_ "GenSigTimeoutValue" SG_ 107 FRS_P1_27_Obj_ExstProb 250;
BA_ "GenSigTimeoutValue" SG_ 106 FRS_P1_26_Msg_AliveCounter 250;
BA_ "GenSigTimeoutValue" SG_ 106 FRS_P1_26_Msg_CheckSum 250;
BA_ "GenSigTimeoutValue" SG_ 106 FRS_P1_26_Obj_MotionPattern 250;
BA_ "GenSigTimeoutValue" SG_ 106 FRS_P1_26_Obj_YPos_Stdev 250;
BA_ "GenSigTimeoutValue" SG_ 106 FRS_P1_26_Obj_XVelRel_Stdev 250;
BA_ "GenSigTimeoutValue" SG_ 106 FRS_P1_26_Obj_XPos_Stdev 250;
BA_ "GenSigStartValue" SG_ 106 FRS_P1_26_Obj_XAccRel 64;
BA_ "GenSigTimeoutValue" SG_ 106 FRS_P1_26_Obj_XAccRel 250;
BA_ "GenSigTimeoutValue" SG_ 106 FRS_P1_26_Obj_ValidFlag 250;
BA_ "GenSigTimeoutValue" SG_ 106 FRS_P1_26_Obj_UpdateFlag 250;
BA_ "GenSigTimeoutValue" SG_ 106 FRS_P1_26_Obj_ObstacleProb 250;
BA_ "GenSigTimeoutValue" SG_ 106 FRS_P1_26_Obj_ID 250;
BA_ "GenSigTimeoutValue" SG_ 106 FRS_P1_26_Obj_ExstProb 250;
BA_ "GenSigTimeoutValue" SG_ 105 FRS_P1_25_Msg_AliveCounter 250;
BA_ "GenSigTimeoutValue" SG_ 105 FRS_P1_25_Msg_CheckSum 250;
BA_ "GenSigTimeoutValue" SG_ 105 FRS_P1_25_Obj_MotionPattern 250;
BA_ "GenSigTimeoutValue" SG_ 105 FRS_P1_25_Obj_YPos_Stdev 250;
BA_ "GenSigTimeoutValue" SG_ 105 FRS_P1_25_Obj_XVelRel_Stdev 250;
BA_ "GenSigTimeoutValue" SG_ 105 FRS_P1_25_Obj_XPos_Stdev 250;
BA_ "GenSigStartValue" SG_ 105 FRS_P1_25_Obj_XAccRel 64;
BA_ "GenSigTimeoutValue" SG_ 105 FRS_P1_25_Obj_XAccRel 250;
BA_ "GenSigTimeoutValue" SG_ 105 FRS_P1_25_Obj_ValidFlag 250;
BA_ "GenSigTimeoutValue" SG_ 105 FRS_P1_25_Obj_UpdateFlag 250;
BA_ "GenSigTimeoutValue" SG_ 105 FRS_P1_25_Obj_ObstacleProb 250;
BA_ "GenSigTimeoutValue" SG_ 105 FRS_P1_25_Obj_ID 250;
BA_ "GenSigTimeoutValue" SG_ 105 FRS_P1_25_Obj_ExstProb 250;
BA_ "GenSigTimeoutValue" SG_ 104 FRS_P1_24_Msg_AliveCounter 250;
BA_ "GenSigTimeoutValue" SG_ 104 FRS_P1_24_Msg_CheckSum 250;
BA_ "GenSigTimeoutValue" SG_ 104 FRS_P1_24_Obj_MotionPattern 250;
BA_ "GenSigTimeoutValue" SG_ 104 FRS_P1_24_Obj_YPos_Stdev 250;
BA_ "GenSigTimeoutValue" SG_ 104 FRS_P1_24_Obj_XVelRel_Stdev 250;
BA_ "GenSigTimeoutValue" SG_ 104 FRS_P1_24_Obj_XPos_Stdev 250;
BA_ "GenSigStartValue" SG_ 104 FRS_P1_24_Obj_XAccRel 64;
BA_ "GenSigTimeoutValue" SG_ 104 FRS_P1_24_Obj_XAccRel 250;
BA_ "GenSigTimeoutValue" SG_ 104 FRS_P1_24_Obj_ValidFlag 250;
BA_ "GenSigTimeoutValue" SG_ 104 FRS_P1_24_Obj_UpdateFlag 250;
BA_ "GenSigTimeoutValue" SG_ 104 FRS_P1_24_Obj_ObstacleProb 250;
BA_ "GenSigTimeoutValue" SG_ 104 FRS_P1_24_Obj_ID 250;
BA_ "GenSigTimeoutValue" SG_ 104 FRS_P1_24_Obj_ExstProb 250;
BA_ "GenSigTimeoutValue" SG_ 103 FRS_P1_23_Msg_AliveCounter 250;
BA_ "GenSigTimeoutValue" SG_ 103 FRS_P1_23_Msg_CheckSum 250;
BA_ "GenSigTimeoutValue" SG_ 103 FRS_P1_23_Obj_MotionPattern 250;
BA_ "GenSigTimeoutValue" SG_ 103 FRS_P1_23_Obj_YPos_Stdev 250;
BA_ "GenSigTimeoutValue" SG_ 103 FRS_P1_23_Obj_XVelRel_Stdev 250;
BA_ "GenSigTimeoutValue" SG_ 103 FRS_P1_23_Obj_XPos_Stdev 250;
BA_ "GenSigStartValue" SG_ 103 FRS_P1_23_Obj_XAccRel 64;
BA_ "GenSigTimeoutValue" SG_ 103 FRS_P1_23_Obj_XAccRel 250;
BA_ "GenSigTimeoutValue" SG_ 103 FRS_P1_23_Obj_ValidFlag 250;
BA_ "GenSigTimeoutValue" SG_ 103 FRS_P1_23_Obj_UpdateFlag 250;
BA_ "GenSigTimeoutValue" SG_ 103 FRS_P1_23_Obj_ObstacleProb 250;
BA_ "GenSigTimeoutValue" SG_ 103 FRS_P1_23_Obj_ID 250;
BA_ "GenSigTimeoutValue" SG_ 103 FRS_P1_23_Obj_ExstProb 250;
BA_ "GenSigTimeoutValue" SG_ 102 FRS_P1_22_Msg_AliveCounter 250;
BA_ "GenSigTimeoutValue" SG_ 102 FRS_P1_22_Msg_CheckSum 250;
BA_ "GenSigTimeoutValue" SG_ 102 FRS_P1_22_Obj_MotionPattern 250;
BA_ "GenSigTimeoutValue" SG_ 102 FRS_P1_22_Obj_YPos_Stdev 250;
BA_ "GenSigTimeoutValue" SG_ 102 FRS_P1_22_Obj_XVelRel_Stdev 250;
BA_ "GenSigTimeoutValue" SG_ 102 FRS_P1_22_Obj_XPos_Stdev 250;
BA_ "GenSigStartValue" SG_ 102 FRS_P1_22_Obj_XAccRel 64;
BA_ "GenSigTimeoutValue" SG_ 102 FRS_P1_22_Obj_XAccRel 250;
BA_ "GenSigTimeoutValue" SG_ 102 FRS_P1_22_Obj_ValidFlag 250;
BA_ "GenSigTimeoutValue" SG_ 102 FRS_P1_22_Obj_UpdateFlag 250;
BA_ "GenSigTimeoutValue" SG_ 102 FRS_P1_22_Obj_ObstacleProb 250;
BA_ "GenSigTimeoutValue" SG_ 102 FRS_P1_22_Obj_ID 250;
BA_ "GenSigTimeoutValue" SG_ 102 FRS_P1_22_Obj_ExstProb 250;
BA_ "GenSigTimeoutValue" SG_ 101 FRS_P1_21_Msg_AliveCounter 250;
BA_ "GenSigTimeoutValue" SG_ 101 FRS_P1_21_Msg_CheckSum 250;
BA_ "GenSigTimeoutValue" SG_ 101 FRS_P1_21_Obj_MotionPattern 250;
BA_ "GenSigTimeoutValue" SG_ 101 FRS_P1_21_Obj_YPos_Stdev 250;
BA_ "GenSigTimeoutValue" SG_ 101 FRS_P1_21_Obj_XVelRel_Stdev 250;
BA_ "GenSigTimeoutValue" SG_ 101 FRS_P1_21_Obj_XPos_Stdev 250;
BA_ "GenSigStartValue" SG_ 101 FRS_P1_21_Obj_XAccRel 64;
BA_ "GenSigTimeoutValue" SG_ 101 FRS_P1_21_Obj_XAccRel 250;
BA_ "GenSigTimeoutValue" SG_ 101 FRS_P1_21_Obj_ValidFlag 250;
BA_ "GenSigTimeoutValue" SG_ 101 FRS_P1_21_Obj_UpdateFlag 250;
BA_ "GenSigTimeoutValue" SG_ 101 FRS_P1_21_Obj_ObstacleProb 250;
BA_ "GenSigTimeoutValue" SG_ 101 FRS_P1_21_Obj_ID 250;
BA_ "GenSigTimeoutValue" SG_ 101 FRS_P1_21_Obj_ExstProb 250;
BA_ "GenSigTimeoutValue" SG_ 100 FRS_P1_20_Msg_AliveCounter 250;
BA_ "GenSigTimeoutValue" SG_ 100 FRS_P1_20_Msg_CheckSum 250;
BA_ "GenSigTimeoutValue" SG_ 100 FRS_P1_20_Obj_MotionPattern 250;
BA_ "GenSigTimeoutValue" SG_ 100 FRS_P1_20_Obj_YPos_Stdev 250;
BA_ "GenSigTimeoutValue" SG_ 100 FRS_P1_20_Obj_XVelRel_Stdev 250;
BA_ "GenSigTimeoutValue" SG_ 100 FRS_P1_20_Obj_XPos_Stdev 250;
BA_ "GenSigStartValue" SG_ 100 FRS_P1_20_Obj_XAccRel 64;
BA_ "GenSigTimeoutValue" SG_ 100 FRS_P1_20_Obj_XAccRel 250;
BA_ "GenSigTimeoutValue" SG_ 100 FRS_P1_20_Obj_ValidFlag 250;
BA_ "GenSigTimeoutValue" SG_ 100 FRS_P1_20_Obj_UpdateFlag 250;
BA_ "GenSigTimeoutValue" SG_ 100 FRS_P1_20_Obj_ObstacleProb 250;
BA_ "GenSigTimeoutValue" SG_ 100 FRS_P1_20_Obj_ID 250;
BA_ "GenSigTimeoutValue" SG_ 100 FRS_P1_20_Obj_ExstProb 250;
BA_ "GenSigTimeoutValue" SG_ 99 FRS_P1_19_Msg_AliveCounter 250;
BA_ "GenSigTimeoutValue" SG_ 99 FRS_P1_19_Msg_CheckSum 250;
BA_ "GenSigTimeoutValue" SG_ 99 FRS_P1_19_Obj_MotionPattern 250;
BA_ "GenSigTimeoutValue" SG_ 99 FRS_P1_19_Obj_YPos_Stdev 250;
BA_ "GenSigTimeoutValue" SG_ 99 FRS_P1_19_Obj_XVelRel_Stdev 250;
BA_ "GenSigTimeoutValue" SG_ 99 FRS_P1_19_Obj_XPos_Stdev 250;
BA_ "GenSigStartValue" SG_ 99 FRS_P1_19_Obj_XAccRel 64;
BA_ "GenSigTimeoutValue" SG_ 99 FRS_P1_19_Obj_XAccRel 250;
BA_ "GenSigTimeoutValue" SG_ 99 FRS_P1_19_Obj_ValidFlag 250;
BA_ "GenSigTimeoutValue" SG_ 99 FRS_P1_19_Obj_UpdateFlag 250;
BA_ "GenSigTimeoutValue" SG_ 99 FRS_P1_19_Obj_ObstacleProb 250;
BA_ "GenSigTimeoutValue" SG_ 99 FRS_P1_19_Obj_ID 250;
BA_ "GenSigTimeoutValue" SG_ 99 FRS_P1_19_Obj_ExstProb 250;
BA_ "GenSigTimeoutValue" SG_ 98 FRS_P1_18_Msg_AliveCounter 250;
BA_ "GenSigTimeoutValue" SG_ 98 FRS_P1_18_Msg_CheckSum 250;
BA_ "GenSigTimeoutValue" SG_ 98 FRS_P1_18_Obj_MotionPattern 250;
BA_ "GenSigTimeoutValue" SG_ 98 FRS_P1_18_Obj_YPos_Stdev 250;
BA_ "GenSigTimeoutValue" SG_ 98 FRS_P1_18_Obj_XVelRel_Stdev 250;
BA_ "GenSigTimeoutValue" SG_ 98 FRS_P1_18_Obj_XPos_Stdev 250;
BA_ "GenSigStartValue" SG_ 98 FRS_P1_18_Obj_XAccRel 64;
BA_ "GenSigTimeoutValue" SG_ 98 FRS_P1_18_Obj_XAccRel 250;
BA_ "GenSigTimeoutValue" SG_ 98 FRS_P1_18_Obj_ValidFlag 250;
BA_ "GenSigTimeoutValue" SG_ 98 FRS_P1_18_Obj_UpdateFlag 250;
BA_ "GenSigTimeoutValue" SG_ 98 FRS_P1_18_Obj_ObstacleProb 250;
BA_ "GenSigTimeoutValue" SG_ 98 FRS_P1_18_Obj_ID 250;
BA_ "GenSigTimeoutValue" SG_ 98 FRS_P1_18_Obj_ExstProb 250;
BA_ "GenSigTimeoutValue" SG_ 97 FRS_P1_17_Msg_AliveCounter 250;
BA_ "GenSigTimeoutValue" SG_ 97 FRS_P1_17_Msg_CheckSum 250;
BA_ "GenSigTimeoutValue" SG_ 97 FRS_P1_17_Obj_MotionPattern 250;
BA_ "GenSigTimeoutValue" SG_ 97 FRS_P1_17_Obj_YPos_Stdev 250;
BA_ "GenSigTimeoutValue" SG_ 97 FRS_P1_17_Obj_XVelRel_Stdev 250;
BA_ "GenSigTimeoutValue" SG_ 97 FRS_P1_17_Obj_XPos_Stdev 250;
BA_ "GenSigStartValue" SG_ 97 FRS_P1_17_Obj_XAccRel 64;
BA_ "GenSigTimeoutValue" SG_ 97 FRS_P1_17_Obj_XAccRel 250;
BA_ "GenSigTimeoutValue" SG_ 97 FRS_P1_17_Obj_ValidFlag 250;
BA_ "GenSigTimeoutValue" SG_ 97 FRS_P1_17_Obj_UpdateFlag 250;
BA_ "GenSigTimeoutValue" SG_ 97 FRS_P1_17_Obj_ObstacleProb 250;
BA_ "GenSigTimeoutValue" SG_ 97 FRS_P1_17_Obj_ID 250;
BA_ "GenSigTimeoutValue" SG_ 97 FRS_P1_17_Obj_ExstProb 250;
BA_ "GenSigTimeoutValue" SG_ 96 FRS_P1_16_Msg_AliveCounter 250;
BA_ "GenSigTimeoutValue" SG_ 96 FRS_P1_16_Msg_CheckSum 250;
BA_ "GenSigTimeoutValue" SG_ 96 FRS_P1_16_Obj_MotionPattern 250;
BA_ "GenSigTimeoutValue" SG_ 96 FRS_P1_16_Obj_YPos_Stdev 250;
BA_ "GenSigTimeoutValue" SG_ 96 FRS_P1_16_Obj_XVelRel_Stdev 250;
BA_ "GenSigTimeoutValue" SG_ 96 FRS_P1_16_Obj_XPos_Stdev 250;
BA_ "GenSigStartValue" SG_ 96 FRS_P1_16_Obj_XAccRel 64;
BA_ "GenSigTimeoutValue" SG_ 96 FRS_P1_16_Obj_XAccRel 250;
BA_ "GenSigTimeoutValue" SG_ 96 FRS_P1_16_Obj_ValidFlag 250;
BA_ "GenSigTimeoutValue" SG_ 96 FRS_P1_16_Obj_UpdateFlag 250;
BA_ "GenSigTimeoutValue" SG_ 96 FRS_P1_16_Obj_ObstacleProb 250;
BA_ "GenSigTimeoutValue" SG_ 96 FRS_P1_16_Obj_ID 250;
BA_ "GenSigTimeoutValue" SG_ 96 FRS_P1_16_Obj_ExstProb 250;
BA_ "GenSigTimeoutValue" SG_ 95 FRS_P1_15_Msg_AliveCounter 250;
BA_ "GenSigTimeoutValue" SG_ 95 FRS_P1_15_Msg_CheckSum 250;
BA_ "GenSigTimeoutValue" SG_ 95 FRS_P1_15_Obj_MotionPattern 250;
BA_ "GenSigTimeoutValue" SG_ 95 FRS_P1_15_Obj_YPos_Stdev 250;
BA_ "GenSigTimeoutValue" SG_ 95 FRS_P1_15_Obj_XVelRel_Stdev 250;
BA_ "GenSigTimeoutValue" SG_ 95 FRS_P1_15_Obj_XPos_Stdev 250;
BA_ "GenSigStartValue" SG_ 95 FRS_P1_15_Obj_XAccRel 64;
BA_ "GenSigTimeoutValue" SG_ 95 FRS_P1_15_Obj_XAccRel 250;
BA_ "GenSigTimeoutValue" SG_ 95 FRS_P1_15_Obj_ValidFlag 250;
BA_ "GenSigTimeoutValue" SG_ 95 FRS_P1_15_Obj_UpdateFlag 250;
BA_ "GenSigTimeoutValue" SG_ 95 FRS_P1_15_Obj_ObstacleProb 250;
BA_ "GenSigTimeoutValue" SG_ 95 FRS_P1_15_Obj_ID 250;
BA_ "GenSigTimeoutValue" SG_ 95 FRS_P1_15_Obj_ExstProb 250;
BA_ "GenSigTimeoutValue" SG_ 94 FRS_P1_14_Msg_AliveCounter 250;
BA_ "GenSigTimeoutValue" SG_ 94 FRS_P1_14_Msg_CheckSum 250;
BA_ "GenSigTimeoutValue" SG_ 94 FRS_P1_14_Obj_MotionPattern 250;
BA_ "GenSigTimeoutValue" SG_ 94 FRS_P1_14_Obj_YPos_Stdev 250;
BA_ "GenSigTimeoutValue" SG_ 94 FRS_P1_14_Obj_XVelRel_Stdev 250;
BA_ "GenSigTimeoutValue" SG_ 94 FRS_P1_14_Obj_XPos_Stdev 250;
BA_ "GenSigStartValue" SG_ 94 FRS_P1_14_Obj_XAccRel 64;
BA_ "GenSigTimeoutValue" SG_ 94 FRS_P1_14_Obj_XAccRel 250;
BA_ "GenSigTimeoutValue" SG_ 94 FRS_P1_14_Obj_ValidFlag 250;
BA_ "GenSigTimeoutValue" SG_ 94 FRS_P1_14_Obj_UpdateFlag 250;
BA_ "GenSigTimeoutValue" SG_ 94 FRS_P1_14_Obj_ObstacleProb 250;
BA_ "GenSigTimeoutValue" SG_ 94 FRS_P1_14_Obj_ID 250;
BA_ "GenSigTimeoutValue" SG_ 94 FRS_P1_14_Obj_ExstProb 250;
BA_ "GenSigTimeoutValue" SG_ 93 FRS_P1_13_Msg_AliveCounter 250;
BA_ "GenSigTimeoutValue" SG_ 93 FRS_P1_13_Msg_CheckSum 250;
BA_ "GenSigTimeoutValue" SG_ 93 FRS_P1_13_Obj_MotionPattern 250;
BA_ "GenSigTimeoutValue" SG_ 93 FRS_P1_13_Obj_YPos_Stdev 250;
BA_ "GenSigTimeoutValue" SG_ 93 FRS_P1_13_Obj_XVelRel_Stdev 250;
BA_ "GenSigTimeoutValue" SG_ 93 FRS_P1_13_Obj_XPos_Stdev 250;
BA_ "GenSigStartValue" SG_ 93 FRS_P1_13_Obj_XAccRel 64;
BA_ "GenSigTimeoutValue" SG_ 93 FRS_P1_13_Obj_XAccRel 250;
BA_ "GenSigTimeoutValue" SG_ 93 FRS_P1_13_Obj_ValidFlag 250;
BA_ "GenSigTimeoutValue" SG_ 93 FRS_P1_13_Obj_UpdateFlag 250;
BA_ "GenSigTimeoutValue" SG_ 93 FRS_P1_13_Obj_ObstacleProb 250;
BA_ "GenSigTimeoutValue" SG_ 93 FRS_P1_13_Obj_ID 250;
BA_ "GenSigTimeoutValue" SG_ 93 FRS_P1_13_Obj_ExstProb 250;
BA_ "GenSigTimeoutValue" SG_ 92 FRS_P1_12_Msg_AliveCounter 250;
BA_ "GenSigTimeoutValue" SG_ 92 FRS_P1_12_Msg_CheckSum 250;
BA_ "GenSigTimeoutValue" SG_ 92 FRS_P1_12_Obj_MotionPattern 250;
BA_ "GenSigTimeoutValue" SG_ 92 FRS_P1_12_Obj_YPos_Stdev 250;
BA_ "GenSigTimeoutValue" SG_ 92 FRS_P1_12_Obj_XVelRel_Stdev 250;
BA_ "GenSigTimeoutValue" SG_ 92 FRS_P1_12_Obj_XPos_Stdev 250;
BA_ "GenSigStartValue" SG_ 92 FRS_P1_12_Obj_XAccRel 64;
BA_ "GenSigTimeoutValue" SG_ 92 FRS_P1_12_Obj_XAccRel 250;
BA_ "GenSigTimeoutValue" SG_ 92 FRS_P1_12_Obj_ValidFlag 250;
BA_ "GenSigTimeoutValue" SG_ 92 FRS_P1_12_Obj_UpdateFlag 250;
BA_ "GenSigTimeoutValue" SG_ 92 FRS_P1_12_Obj_ObstacleProb 250;
BA_ "GenSigTimeoutValue" SG_ 92 FRS_P1_12_Obj_ID 250;
BA_ "GenSigTimeoutValue" SG_ 92 FRS_P1_12_Obj_ExstProb 250;
BA_ "GenSigTimeoutValue" SG_ 90 FRS_P1_10_Obj_YPos_Stdev 250;
BA_ "GenSigTimeoutValue" SG_ 90 FRS_P1_10_Obj_XVelRel_Stdev 250;
BA_ "GenSigTimeoutValue" SG_ 90 FRS_P1_10_Obj_XPos_Stdev 250;
BA_ "GenSigStartValue" SG_ 90 FRS_P1_10_Obj_XAccRel 64;
BA_ "GenSigTimeoutValue" SG_ 90 FRS_P1_10_Obj_XAccRel 250;
BA_ "GenSigTimeoutValue" SG_ 90 FRS_P1_10_Obj_ValidFlag 250;
BA_ "GenSigTimeoutValue" SG_ 90 FRS_P1_10_Obj_UpdateFlag 250;
BA_ "GenSigTimeoutValue" SG_ 90 FRS_P1_10_Obj_ObstacleProb 250;
BA_ "GenSigTimeoutValue" SG_ 90 FRS_P1_10_Obj_MotionPattern 250;
BA_ "GenSigTimeoutValue" SG_ 90 FRS_P1_10_Obj_ID 250;
BA_ "GenSigTimeoutValue" SG_ 90 FRS_P1_10_Obj_ExstProb 250;
BA_ "GenSigTimeoutValue" SG_ 90 FRS_P1_10_Msg_CheckSum 250;
BA_ "GenSigTimeoutValue" SG_ 90 FRS_P1_10_Msg_AliveCounter 250;
BA_ "GenSigTimeoutValue" SG_ 89 FRS_P1_09_Msg_AliveCounter 250;
BA_ "GenSigTimeoutValue" SG_ 89 FRS_P1_09_Msg_CheckSum 250;
BA_ "GenSigTimeoutValue" SG_ 89 FRS_P1_09_Obj_MotionPattern 250;
BA_ "GenSigTimeoutValue" SG_ 89 FRS_P1_09_Obj_YPos_Stdev 250;
BA_ "GenSigTimeoutValue" SG_ 89 FRS_P1_09_Obj_XVelRel_Stdev 250;
BA_ "GenSigTimeoutValue" SG_ 89 FRS_P1_09_Obj_XPos_Stdev 250;
BA_ "GenSigStartValue" SG_ 89 FRS_P1_09_Obj_XAccRel 64;
BA_ "GenSigTimeoutValue" SG_ 89 FRS_P1_09_Obj_XAccRel 250;
BA_ "GenSigTimeoutValue" SG_ 89 FRS_P1_09_Obj_ValidFlag 250;
BA_ "GenSigTimeoutValue" SG_ 89 FRS_P1_09_Obj_UpdateFlag 250;
BA_ "GenSigTimeoutValue" SG_ 89 FRS_P1_09_Obj_ObstacleProb 250;
BA_ "GenSigTimeoutValue" SG_ 89 FRS_P1_09_Obj_ID 250;
BA_ "GenSigTimeoutValue" SG_ 89 FRS_P1_09_Obj_ExstProb 250;
BA_ "GenSigTimeoutValue" SG_ 88 FRS_P1_08_Msg_AliveCounter 250;
BA_ "GenSigTimeoutValue" SG_ 88 FRS_P1_08_Msg_CheckSum 250;
BA_ "GenSigTimeoutValue" SG_ 88 FRS_P1_08_Obj_MotionPattern 250;
BA_ "GenSigTimeoutValue" SG_ 88 FRS_P1_08_Obj_YPos_Stdev 250;
BA_ "GenSigTimeoutValue" SG_ 88 FRS_P1_08_Obj_XVelRel_Stdev 250;
BA_ "GenSigTimeoutValue" SG_ 88 FRS_P1_08_Obj_XPos_Stdev 250;
BA_ "GenSigStartValue" SG_ 88 FRS_P1_08_Obj_XAccRel 64;
BA_ "GenSigTimeoutValue" SG_ 88 FRS_P1_08_Obj_XAccRel 250;
BA_ "GenSigTimeoutValue" SG_ 88 FRS_P1_08_Obj_ValidFlag 250;
BA_ "GenSigTimeoutValue" SG_ 88 FRS_P1_08_Obj_UpdateFlag 250;
BA_ "GenSigTimeoutValue" SG_ 88 FRS_P1_08_Obj_ObstacleProb 250;
BA_ "GenSigTimeoutValue" SG_ 88 FRS_P1_08_Obj_ID 250;
BA_ "GenSigTimeoutValue" SG_ 88 FRS_P1_08_Obj_ExstProb 250;
BA_ "GenSigTimeoutValue" SG_ 87 FRS_P1_07_Msg_AliveCounter 250;
BA_ "GenSigTimeoutValue" SG_ 87 FRS_P1_07_Msg_CheckSum 250;
BA_ "GenSigTimeoutValue" SG_ 87 FRS_P1_07_Obj_MotionPattern 250;
BA_ "GenSigTimeoutValue" SG_ 87 FRS_P1_07_Obj_YPos_Stdev 250;
BA_ "GenSigTimeoutValue" SG_ 87 FRS_P1_07_Obj_XVelRel_Stdev 250;
BA_ "GenSigTimeoutValue" SG_ 87 FRS_P1_07_Obj_XPos_Stdev 250;
BA_ "GenSigStartValue" SG_ 87 FRS_P1_07_Obj_XAccRel 64;
BA_ "GenSigTimeoutValue" SG_ 87 FRS_P1_07_Obj_XAccRel 250;
BA_ "GenSigTimeoutValue" SG_ 87 FRS_P1_07_Obj_ValidFlag 250;
BA_ "GenSigTimeoutValue" SG_ 87 FRS_P1_07_Obj_UpdateFlag 250;
BA_ "GenSigTimeoutValue" SG_ 87 FRS_P1_07_Obj_ObstacleProb 250;
BA_ "GenSigTimeoutValue" SG_ 87 FRS_P1_07_Obj_ID 250;
BA_ "GenSigTimeoutValue" SG_ 87 FRS_P1_07_Obj_ExstProb 250;
BA_ "GenSigTimeoutValue" SG_ 86 FRS_P1_06_Msg_AliveCounter 250;
BA_ "GenSigTimeoutValue" SG_ 86 FRS_P1_06_Msg_CheckSum 250;
BA_ "GenSigTimeoutValue" SG_ 86 FRS_P1_06_Obj_MotionPattern 250;
BA_ "GenSigTimeoutValue" SG_ 86 FRS_P1_06_Obj_YPos_Stdev 250;
BA_ "GenSigTimeoutValue" SG_ 86 FRS_P1_06_Obj_XVelRel_Stdev 250;
BA_ "GenSigTimeoutValue" SG_ 86 FRS_P1_06_Obj_XPos_Stdev 250;
BA_ "GenSigStartValue" SG_ 86 FRS_P1_06_Obj_XAccRel 64;
BA_ "GenSigTimeoutValue" SG_ 86 FRS_P1_06_Obj_XAccRel 250;
BA_ "GenSigTimeoutValue" SG_ 86 FRS_P1_06_Obj_ValidFlag 250;
BA_ "GenSigTimeoutValue" SG_ 86 FRS_P1_06_Obj_UpdateFlag 250;
BA_ "GenSigTimeoutValue" SG_ 86 FRS_P1_06_Obj_ObstacleProb 250;
BA_ "GenSigTimeoutValue" SG_ 86 FRS_P1_06_Obj_ID 250;
BA_ "GenSigTimeoutValue" SG_ 86 FRS_P1_06_Obj_ExstProb 250;
BA_ "GenSigTimeoutValue" SG_ 85 FRS_P1_05_Msg_AliveCounter 250;
BA_ "GenSigTimeoutValue" SG_ 85 FRS_P1_05_Msg_CheckSum 250;
BA_ "GenSigTimeoutValue" SG_ 85 FRS_P1_05_Obj_MotionPattern 250;
BA_ "GenSigTimeoutValue" SG_ 85 FRS_P1_05_Obj_YPos_Stdev 250;
BA_ "GenSigTimeoutValue" SG_ 85 FRS_P1_05_Obj_XVelRel_Stdev 250;
BA_ "GenSigTimeoutValue" SG_ 85 FRS_P1_05_Obj_XPos_Stdev 250;
BA_ "GenSigStartValue" SG_ 85 FRS_P1_05_Obj_XAccRel 64;
BA_ "GenSigTimeoutValue" SG_ 85 FRS_P1_05_Obj_XAccRel 250;
BA_ "GenSigTimeoutValue" SG_ 85 FRS_P1_05_Obj_ValidFlag 250;
BA_ "GenSigTimeoutValue" SG_ 85 FRS_P1_05_Obj_UpdateFlag 250;
BA_ "GenSigTimeoutValue" SG_ 85 FRS_P1_05_Obj_ObstacleProb 250;
BA_ "GenSigTimeoutValue" SG_ 85 FRS_P1_05_Obj_ID 250;
BA_ "GenSigTimeoutValue" SG_ 85 FRS_P1_05_Obj_ExstProb 250;
BA_ "GenSigTimeoutValue" SG_ 84 FRS_P1_04_Msg_AliveCounter 250;
BA_ "GenSigTimeoutValue" SG_ 84 FRS_P1_04_Msg_CheckSum 250;
BA_ "GenSigTimeoutValue" SG_ 84 FRS_P1_04_Obj_MotionPattern 250;
BA_ "GenSigTimeoutValue" SG_ 84 FRS_P1_04_Obj_YPos_Stdev 250;
BA_ "GenSigTimeoutValue" SG_ 84 FRS_P1_04_Obj_XVelRel_Stdev 250;
BA_ "GenSigTimeoutValue" SG_ 84 FRS_P1_04_Obj_XPos_Stdev 250;
BA_ "GenSigStartValue" SG_ 84 FRS_P1_04_Obj_XAccRel 64;
BA_ "GenSigTimeoutValue" SG_ 84 FRS_P1_04_Obj_XAccRel 250;
BA_ "GenSigTimeoutValue" SG_ 84 FRS_P1_04_Obj_ValidFlag 250;
BA_ "GenSigTimeoutValue" SG_ 84 FRS_P1_04_Obj_UpdateFlag 250;
BA_ "GenSigTimeoutValue" SG_ 84 FRS_P1_04_Obj_ObstacleProb 250;
BA_ "GenSigTimeoutValue" SG_ 84 FRS_P1_04_Obj_ID 250;
BA_ "GenSigTimeoutValue" SG_ 84 FRS_P1_04_Obj_ExstProb 250;
BA_ "GenSigTimeoutValue" SG_ 83 FRS_P1_03_Msg_AliveCounter 250;
BA_ "GenSigTimeoutValue" SG_ 83 FRS_P1_03_Msg_CheckSum 250;
BA_ "GenSigTimeoutValue" SG_ 83 FRS_P1_03_Obj_MotionPattern 250;
BA_ "GenSigTimeoutValue" SG_ 83 FRS_P1_03_Obj_YPos_Stdev 250;
BA_ "GenSigTimeoutValue" SG_ 83 FRS_P1_03_Obj_XVelRel_Stdev 250;
BA_ "GenSigTimeoutValue" SG_ 83 FRS_P1_03_Obj_XPos_Stdev 250;
BA_ "GenSigStartValue" SG_ 83 FRS_P1_03_Obj_XAccRel 64;
BA_ "GenSigTimeoutValue" SG_ 83 FRS_P1_03_Obj_XAccRel 250;
BA_ "GenSigTimeoutValue" SG_ 83 FRS_P1_03_Obj_ValidFlag 250;
BA_ "GenSigTimeoutValue" SG_ 83 FRS_P1_03_Obj_UpdateFlag 250;
BA_ "GenSigTimeoutValue" SG_ 83 FRS_P1_03_Obj_ObstacleProb 250;
BA_ "GenSigTimeoutValue" SG_ 83 FRS_P1_03_Obj_ID 250;
BA_ "GenSigTimeoutValue" SG_ 83 FRS_P1_03_Obj_ExstProb 250;
BA_ "GenSigTimeoutValue" SG_ 82 FRS_P1_02_Msg_AliveCounter 250;
BA_ "GenSigTimeoutValue" SG_ 82 FRS_P1_02_Msg_CheckSum 250;
BA_ "GenSigTimeoutValue" SG_ 82 FRS_P1_02_Obj_MotionPattern 250;
BA_ "GenSigTimeoutValue" SG_ 82 FRS_P1_02_Obj_YPos_Stdev 250;
BA_ "GenSigTimeoutValue" SG_ 82 FRS_P1_02_Obj_XVelRel_Stdev 250;
BA_ "GenSigTimeoutValue" SG_ 82 FRS_P1_02_Obj_XPos_Stdev 250;
BA_ "GenSigStartValue" SG_ 82 FRS_P1_02_Obj_XAccRel 64;
BA_ "GenSigTimeoutValue" SG_ 82 FRS_P1_02_Obj_XAccRel 250;
BA_ "GenSigTimeoutValue" SG_ 82 FRS_P1_02_Obj_ValidFlag 250;
BA_ "GenSigTimeoutValue" SG_ 82 FRS_P1_02_Obj_UpdateFlag 250;
BA_ "GenSigTimeoutValue" SG_ 82 FRS_P1_02_Obj_ObstacleProb 250;
BA_ "GenSigTimeoutValue" SG_ 82 FRS_P1_02_Obj_ID 250;
BA_ "GenSigTimeoutValue" SG_ 82 FRS_P1_02_Obj_ExstProb 250;
BA_ "GenSigTimeoutValue" SG_ 81 FRS_P1_01_Msg_AliveCounter 250;
BA_ "GenSigTimeoutValue" SG_ 81 FRS_P1_01_Msg_CheckSum 250;
BA_ "GenSigTimeoutValue" SG_ 81 FRS_P1_01_Obj_MotionPattern 250;
BA_ "GenSigTimeoutValue" SG_ 81 FRS_P1_01_Obj_YPos_Stdev 250;
BA_ "GenSigTimeoutValue" SG_ 81 FRS_P1_01_Obj_XVelRel_Stdev 250;
BA_ "GenSigTimeoutValue" SG_ 81 FRS_P1_01_Obj_XPos_Stdev 250;
BA_ "GenSigStartValue" SG_ 81 FRS_P1_01_Obj_XAccRel 64;
BA_ "GenSigTimeoutValue" SG_ 81 FRS_P1_01_Obj_XAccRel 250;
BA_ "GenSigTimeoutValue" SG_ 81 FRS_P1_01_Obj_ValidFlag 250;
BA_ "GenSigTimeoutValue" SG_ 81 FRS_P1_01_Obj_UpdateFlag 250;
BA_ "GenSigTimeoutValue" SG_ 81 FRS_P1_01_Obj_ObstacleProb 250;
BA_ "GenSigTimeoutValue" SG_ 81 FRS_P1_01_Obj_ID 250;
BA_ "GenSigTimeoutValue" SG_ 81 FRS_P1_01_Obj_ExstProb 250;
BA_ "GenSigStartValue" SG_ 32 FRS_P2_00_Obj_YVelRel 1024;
BA_ "GenSigTimeoutValue" SG_ 32 FRS_P2_00_Obj_YVelRel 250;
BA_ "GenSigStartValue" SG_ 32 FRS_P2_00_Obj_YPos 4096;
BA_ "GenSigTimeoutValue" SG_ 32 FRS_P2_00_Obj_YPos 250;
BA_ "GenSigStartValue" SG_ 32 FRS_P2_00_Obj_XVelRel 1024;
BA_ "GenSigTimeoutValue" SG_ 32 FRS_P2_00_Obj_XVelRel 250;
BA_ "GenSigTimeoutValue" SG_ 32 FRS_P2_00_Obj_XPos 250;
BA_ "GenSigTimeoutValue" SG_ 32 FRS_P2_00_Obj_Type 250;
BA_ "GenSigTimeoutValue" SG_ 32 FRS_P2_00_Obj_MeasFlag 250;
BA_ "GenSigTimeoutValue" SG_ 32 FRS_P2_00_Msg_AliveCounter 250;
BA_ "GenSigTimeoutValue" SG_ 32 FRS_P2_00_Msg_CheckSum 250;
BA_ "GenSigTimeoutValue" SG_ 80 FRS_P1_00_Msg_AliveCounter 250;
BA_ "GenSigTimeoutValue" SG_ 80 FRS_P1_00_Msg_CheckSum 250;
BA_ "GenSigTimeoutValue" SG_ 80 FRS_P1_00_Obj_MotionPattern 250;
BA_ "GenSigTimeoutValue" SG_ 80 FRS_P1_00_Obj_YPos_Stdev 250;
BA_ "GenSigTimeoutValue" SG_ 80 FRS_P1_00_Obj_XVelRel_Stdev 250;
BA_ "GenSigTimeoutValue" SG_ 80 FRS_P1_00_Obj_XPos_Stdev 250;
BA_ "GenSigStartValue" SG_ 80 FRS_P1_00_Obj_XAccRel 64;
BA_ "GenSigTimeoutValue" SG_ 80 FRS_P1_00_Obj_XAccRel 250;
BA_ "GenSigTimeoutValue" SG_ 80 FRS_P1_00_Obj_ValidFlag 250;
BA_ "GenSigTimeoutValue" SG_ 80 FRS_P1_00_Obj_UpdateFlag 250;
BA_ "GenSigTimeoutValue" SG_ 80 FRS_P1_00_Obj_ObstacleProb 250;
BA_ "GenSigTimeoutValue" SG_ 80 FRS_P1_00_Obj_ID 250;
BA_ "GenSigTimeoutValue" SG_ 80 FRS_P1_00_Obj_ExstProb 250;
BA_ "GenSigTimeoutValue" SG_ 128 FRS_Msg_CheckSum 250;
BA_ "GenSigTimeoutValue" SG_ 128 FRS_Status_MisAlign 250;
BA_ "GenSigTimeoutValue" SG_ 128 FRS_Status_HWErr 250;
BA_ "GenSigTimeoutValue" SG_ 128 FRS_Status_BlkProg 250;
BA_ "GenSigTimeoutValue" SG_ 128 FRS_MeasEnabled 250;
BA_ "GenSigStartValue" SG_ 128 FRS_Host_Yaw 1024;
BA_ "GenSigTimeoutValue" SG_ 128 FRS_Host_Yaw 250;
BA_ "GenSigTimeoutValue" SG_ 128 FRS_Fail 250;
BA_ "GenSigTimeoutValue" SG_ 128 FRS_TimeStamp 250;
BA_ "GenSigStartValue" SG_ 128 FRS_HostSpeed 800;
BA_ "GenSigTimeoutValue" SG_ 128 FRS_HostSpeed 250;
BA_ "GenSigTimeoutValue" SG_ 128 FRS_Msg_AliveCounter 250;
BA_ "GenSigTimeoutValue" SG_ 128 FRS_Latency 250;
VAL_ 112 FRS_P1_32_Obj_MotionPattern 0 "UNKNOWN" 1 "STATIONARY" 2 "STOPPED" 3 "MOVING" 4 "CROSSL" 5 "ONCOMING" 6 "CROSSR" 7 "HIGHTAR" ;
VAL_ 112 FRS_P1_32_Obj_ValidFlag 0 "OBJECT_INVALID" 1 "OBJECT_VALID" ;
VAL_ 112 FRS_P1_32_Obj_UpdateFlag 0 "NEW_OBJECT_INTHE_CYCLE" 1 "OBJECT_EXISTED_IN_PREVIOUS_CYCLE" ;
VAL_ 112 FRS_P1_32_Obj_ID 255 "INVALID" ;
VAL_ 111 FRS_P1_31_Obj_MotionPattern 0 "UNKNOWN" 1 "STATIONARY" 2 "STOPPED" 3 "MOVING" 4 "CROSSL" 5 "ONCOMING" 6 "CROSSR" 7 "HIGHTAR" ;
VAL_ 111 FRS_P1_31_Obj_ValidFlag 0 "OBJECT_INVALID" 1 "OBJECT_VALID" ;
VAL_ 111 FRS_P1_31_Obj_UpdateFlag 0 "NEW_OBJECT_INTHE_CYCLE" 1 "OBJECT_EXISTED_IN_PREVIOUS_CYCLE" ;
VAL_ 111 FRS_P1_31_Obj_ID 255 "INVALID" ;
VAL_ 110 FRS_P1_30_Obj_MotionPattern 0 "UNKNOWN" 1 "STATIONARY" 2 "STOPPED" 3 "MOVING" 4 "CROSSL" 5 "ONCOMING" 6 "CROSSR" 7 "HIGHTAR" ;
VAL_ 110 FRS_P1_30_Obj_ValidFlag 0 "OBJECT_INVALID" 1 "OBJECT_VALID" ;
VAL_ 110 FRS_P1_30_Obj_UpdateFlag 0 "NEW_OBJECT_INTHE_CYCLE" 1 "OBJECT_EXISTED_IN_PREVIOUS_CYCLE" ;
VAL_ 110 FRS_P1_30_Obj_ID 255 "INVALID" ;
VAL_ 109 FRS_P1_29_Obj_MotionPattern 0 "UNKNOWN" 1 "STATIONARY" 2 "STOPPED" 3 "MOVING" 4 "CROSSL" 5 "ONCOMING" 6 "CROSSR" 7 "HIGHTAR" ;
VAL_ 109 FRS_P1_29_Obj_ValidFlag 0 "OBJECT_INVALID" 1 "OBJECT_VALID" ;
VAL_ 109 FRS_P1_29_Obj_UpdateFlag 0 "NEW_OBJECT_INTHE_CYCLE" 1 "OBJECT_EXISTED_IN_PREVIOUS_CYCLE" ;
VAL_ 109 FRS_P1_29_Obj_ID 255 "INVALID" ;
VAL_ 108 FRS_P1_28_Obj_MotionPattern 0 "UNKNOWN" 1 "STATIONARY" 2 "STOPPED" 3 "MOVING" 4 "CROSSL" 5 "ONCOMING" 6 "CROSSR" 7 "HIGHTAR" ;
VAL_ 108 FRS_P1_28_Obj_ValidFlag 0 "OBJECT_INVALID" 1 "OBJECT_VALID" ;
VAL_ 108 FRS_P1_28_Obj_UpdateFlag 0 "NEW_OBJECT_INTHE_CYCLE" 1 "OBJECT_EXISTED_IN_PREVIOUS_CYCLE" ;
VAL_ 108 FRS_P1_28_Obj_ID 255 "INVALID" ;
VAL_ 107 FRS_P1_27_Obj_MotionPattern 0 "UNKNOWN" 1 "STATIONARY" 2 "STOPPED" 3 "MOVING" 4 "CROSSL" 5 "ONCOMING" 6 "CROSSR" 7 "HIGHTAR" ;
VAL_ 107 FRS_P1_27_Obj_ValidFlag 0 "OBJECT_INVALID" 1 "OBJECT_VALID" ;
VAL_ 107 FRS_P1_27_Obj_UpdateFlag 0 "NEW_OBJECT_INTHE_CYCLE" 1 "OBJECT_EXISTED_IN_PREVIOUS_CYCLE" ;
VAL_ 107 FRS_P1_27_Obj_ID 255 "INVALID" ;
VAL_ 106 FRS_P1_26_Obj_MotionPattern 0 "UNKNOWN" 1 "STATIONARY" 2 "STOPPED" 3 "MOVING" 4 "CROSSL" 5 "ONCOMING" 6 "CROSSR" 7 "HIGHTAR" ;
VAL_ 106 FRS_P1_26_Obj_ValidFlag 0 "OBJECT_INVALID" 1 "OBJECT_VALID" ;
VAL_ 106 FRS_P1_26_Obj_UpdateFlag 0 "NEW_OBJECT_INTHE_CYCLE" 1 "OBJECT_EXISTED_IN_PREVIOUS_CYCLE" ;
VAL_ 106 FRS_P1_26_Obj_ID 255 "INVALID" ;
VAL_ 105 FRS_P1_25_Obj_MotionPattern 0 "UNKNOWN" 1 "STATIONARY" 2 "STOPPED" 3 "MOVING" 4 "CROSSL" 5 "ONCOMING" 6 "CROSSR" 7 "HIGHTAR" ;
VAL_ 105 FRS_P1_25_Obj_ValidFlag 0 "OBJECT_INVALID" 1 "OBJECT_VALID" ;
VAL_ 105 FRS_P1_25_Obj_UpdateFlag 0 "NEW_OBJECT_INTHE_CYCLE" 1 "OBJECT_EXISTED_IN_PREVIOUS_CYCLE" ;
VAL_ 105 FRS_P1_25_Obj_ID 255 "INVALID" ;
VAL_ 104 FRS_P1_24_Obj_MotionPattern 0 "UNKNOWN" 1 "STATIONARY" 2 "STOPPED" 3 "MOVING" 4 "CROSSL" 5 "ONCOMING" 6 "CROSSR" 7 "HIGHTAR" ;
VAL_ 104 FRS_P1_24_Obj_ValidFlag 0 "OBJECT_INVALID" 1 "OBJECT_VALID" ;
VAL_ 104 FRS_P1_24_Obj_UpdateFlag 0 "NEW_OBJECT_INTHE_CYCLE" 1 "OBJECT_EXISTED_IN_PREVIOUS_CYCLE" ;
VAL_ 104 FRS_P1_24_Obj_ID 255 "INVALID" ;
VAL_ 103 FRS_P1_23_Obj_MotionPattern 0 "UNKNOWN" 1 "STATIONARY" 2 "STOPPED" 3 "MOVING" 4 "CROSSL" 5 "ONCOMING" 6 "CROSSR" 7 "HIGHTAR" ;
VAL_ 103 FRS_P1_23_Obj_ValidFlag 0 "OBJECT_INVALID" 1 "OBJECT_VALID" ;
VAL_ 103 FRS_P1_23_Obj_UpdateFlag 0 "NEW_OBJECT_INTHE_CYCLE" 1 "OBJECT_EXISTED_IN_PREVIOUS_CYCLE" ;
VAL_ 103 FRS_P1_23_Obj_ID 255 "INVALID" ;
VAL_ 102 FRS_P1_22_Obj_MotionPattern 0 "UNKNOWN" 1 "STATIONARY" 2 "STOPPED" 3 "MOVING" 4 "CROSSL" 5 "ONCOMING" 6 "CROSSR" 7 "HIGHTAR" ;
VAL_ 102 FRS_P1_22_Obj_ValidFlag 0 "OBJECT_INVALID" 1 "OBJECT_VALID" ;
VAL_ 102 FRS_P1_22_Obj_UpdateFlag 0 "NEW_OBJECT_INTHE_CYCLE" 1 "OBJECT_EXISTED_IN_PREVIOUS_CYCLE" ;
VAL_ 102 FRS_P1_22_Obj_ID 255 "INVALID" ;
VAL_ 101 FRS_P1_21_Obj_MotionPattern 0 "UNKNOWN" 1 "STATIONARY" 2 "STOPPED" 3 "MOVING" 4 "CROSSL" 5 "ONCOMIONG" 6 "CROSSR" 7 "HIGHTAR" ;
VAL_ 101 FRS_P1_21_Obj_ValidFlag 0 "OBJECT_INVALID" 1 "OBJECT_VALID" ;
VAL_ 101 FRS_P1_21_Obj_UpdateFlag 0 "NEW_OBJECT_INTHE_CYCLE" 1 "OBJECT_EXISTED_IN_PREVIOUS_CYCLE" ;
VAL_ 101 FRS_P1_21_Obj_ID 255 "INVALID" ;
VAL_ 100 FRS_P1_20_Obj_MotionPattern 0 "UNKNOWN" 1 "STATIONARY" 2 "STOPPED" 3 "MOVING" 4 "CROSSL" 5 "ONCOMING" 6 "CROSSR" 7 "HIGHTAR" ;
VAL_ 100 FRS_P1_20_Obj_ValidFlag 0 "OBJECT_INVALID" 1 "OBJECT_VALID" ;
VAL_ 100 FRS_P1_20_Obj_UpdateFlag 0 "NEW_OBJECT_INTHE_CYCLE" 1 "OBJECT_EXISTED_IN_PREVIOUS_CYCLE" ;
VAL_ 100 FRS_P1_20_Obj_ID 255 "INVALID" ;
VAL_ 99 FRS_P1_19_Obj_MotionPattern 0 "UNKNOWN" 1 "STATIONARY" 2 "STOPPED" 3 "MOVING" 4 "CROSSL" 5 "ONCOMING" 6 "CROSSR" 7 "HIGHTAR" ;
VAL_ 99 FRS_P1_19_Obj_ValidFlag 0 "OBJECT_INVALID" 1 "OBJECT_VALID" ;
VAL_ 99 FRS_P1_19_Obj_UpdateFlag 0 "NEW_OBJECT_INTHE_CYCLE" 1 "OBJECT_EXISTED_IN_PREVIOUS_CYCLE" ;
VAL_ 99 FRS_P1_19_Obj_ID 255 "INVALID" ;
VAL_ 98 FRS_P1_18_Obj_MotionPattern 0 "UNKNOWN" 1 "STATIONARY" 2 "STOPPED" 3 "MOVING" 4 "CROSSL" 5 "ONCOMING" 6 "CROSSR" 7 "HIGHTAR" ;
VAL_ 98 FRS_P1_18_Obj_ValidFlag 0 "OBJECT_INVALID" 1 "OBJECT_VALID" ;
VAL_ 98 FRS_P1_18_Obj_UpdateFlag 0 "NEW_OBJECT_INTHE_CYCLE" 1 "OBJECT_EXISTED_IN_PREVIOUS_CYCLE" ;
VAL_ 98 FRS_P1_18_Obj_ID 255 "INVALID" ;
VAL_ 97 FRS_P1_17_Obj_MotionPattern 0 "UNKNOWN" 1 "STATIONARY" 2 "STOPPED" 3 "MOVING" 4 "CROSSL" 5 "ONCOMING" 6 "CROSSR" 7 "HIGHTAR" ;
VAL_ 97 FRS_P1_17_Obj_ValidFlag 0 "OBJECT_INVALID" 1 "OBJECT_VALID" ;
VAL_ 97 FRS_P1_17_Obj_UpdateFlag 0 "NEW_OBJECT_INTHE_CYCLE" 1 "OBJECT_EXISTED_IN_PREVIOUS_CYCLE" ;
VAL_ 97 FRS_P1_17_Obj_ID 255 "INVALID" ;
VAL_ 96 FRS_P1_16_Obj_MotionPattern 0 "UNKNOWN" 1 "STATIONARY" 2 "STOPPED" 3 "MOVING" 4 "CROSSL" 5 "ONCOMING" 6 "CROSSR" 7 "HIGHTAR" ;
VAL_ 96 FRS_P1_16_Obj_ValidFlag 0 "OBJECT_INVALID" 1 "OBJECT_VALID" ;
VAL_ 96 FRS_P1_16_Obj_UpdateFlag 0 "NEW_OBJECT_INTHE_CYCLE" 1 "OBJECT_EXISTED_IN_PREVIOUS_CYCLE" ;
VAL_ 96 FRS_P1_16_Obj_ID 255 "INVALID" ;
VAL_ 95 FRS_P1_15_Obj_MotionPattern 0 "UNKNOWN" 1 "STATIONARY" 2 "STOPPED" 3 "MOVING" 4 "CROSSL" 5 "ONCOMING" 6 "CROSSR" 7 "HIGHTAR" ;
VAL_ 95 FRS_P1_15_Obj_ValidFlag 0 "OBJECT_INVALID" 1 "OBJECT_VALID" ;
VAL_ 95 FRS_P1_15_Obj_UpdateFlag 0 "NEW_OBJECT_INTHE_CYCLE" 1 "OBJECT_EXISTED_IN_PREVIOUS_CYCLE" ;
VAL_ 95 FRS_P1_15_Obj_ID 255 "INVALID" ;
VAL_ 94 FRS_P1_14_Obj_MotionPattern 0 "UNKNOWN" 1 "STATIONARY" 2 "STOPPED" 3 "MOVING" 4 "CROSSL" 5 "ONCOMING" 6 "CROSSR" 7 "HIGHTAR" ;
VAL_ 94 FRS_P1_14_Obj_ValidFlag 0 "OBJECT_INVALID" 1 "OBJECT_VALID" ;
VAL_ 94 FRS_P1_14_Obj_UpdateFlag 0 "NEW_OBJECT_INTHE_CYCLE" 1 "OBJECT_EXISTED_IN_PREVIOUS_CYCLE" ;
VAL_ 94 FRS_P1_14_Obj_ID 255 "INVALID" ;
VAL_ 93 FRS_P1_13_Obj_MotionPattern 0 "UNKNOWN" 1 "STATIONARY" 2 "STOPPED" 3 "MOVING" 4 "CROSSL" 5 "ONCOMING" 6 "CROSSR" 7 "HIGHTAR" ;
VAL_ 93 FRS_P1_13_Obj_ValidFlag 0 "OBJECT_INVALID" 1 "OBJECT_VALID" ;
VAL_ 93 FRS_P1_13_Obj_UpdateFlag 0 "NEW_OBJECT_INTHE_CYCLE" 1 "OBJECT_EXISTED_IN_PREVIOUS_CYCLE" ;
VAL_ 93 FRS_P1_13_Obj_ID 255 "INVALID" ;
VAL_ 92 FRS_P1_12_Obj_MotionPattern 0 "UNKNOWN" 1 "STATIONARY" 2 "STOPPED" 3 "MOVING" 4 "CROSSL" 5 "ONCOMING" 6 "CROSSR" 7 "HIGHTAR" ;
VAL_ 92 FRS_P1_12_Obj_ValidFlag 0 "OBJECT_INVALID" 1 "OBJECT_VALID" ;
VAL_ 92 FRS_P1_12_Obj_UpdateFlag 0 "NEW_OBJECT_INTHE_CYCLE" 1 "OBJECT_EXISTED_IN_PREVIOUS_CYCLE" ;
VAL_ 92 FRS_P1_12_Obj_ID 255 "INVALID" ;
VAL_ 90 FRS_P1_10_Obj_ValidFlag 0 "OBJECT_INVALID" 1 "OBJECT_VALID" ;
VAL_ 90 FRS_P1_10_Obj_UpdateFlag 0 "NEW_OBJECT_INTHE_CYCLE" 1 "OBJECT_EXISTED_IN_PREVIOUS_CYCLE" ;
VAL_ 90 FRS_P1_10_Obj_MotionPattern 0 "UNKNOWN" 1 "STATIONARY" 2 "STOPPED" 3 "MOVING" 4 "CROSSL" 5 "ONCOMING" 6 "CROSSR" 7 "HIGHTAR" ;
VAL_ 90 FRS_P1_10_Obj_ID 255 "INVALID" ;
VAL_ 89 FRS_P1_09_Obj_MotionPattern 0 "UNKNOWN" 1 "STATIONARY" 2 "STOPPED" 3 "MOVING" 4 "CROSSL" 5 "ONCOMING" 6 "CROSSR" 7 "HIGHTAR" ;
VAL_ 89 FRS_P1_09_Obj_ValidFlag 0 "OBJECT_INVALID" 1 "OBJECT_VALID" ;
VAL_ 89 FRS_P1_09_Obj_UpdateFlag 0 "NEW_OBJECT_INTHE_CYCLE" 1 "OBJECT_EXISTED_IN_PREVIOUS_CYCLE" ;
VAL_ 89 FRS_P1_09_Obj_ID 255 "INVALID" ;
VAL_ 88 FRS_P1_08_Obj_MotionPattern 0 "UNKNOWN" 1 "STATIONARY" 2 "STOPPED" 3 "MOVING" 4 "CROSSL" 5 "ONCOMING" 6 "CROSSR" 7 "HIGHTAR" ;
VAL_ 88 FRS_P1_08_Obj_ValidFlag 0 "OBJECT_INVALID" 1 "OBJECT_VALID" ;
VAL_ 88 FRS_P1_08_Obj_UpdateFlag 0 "NEW_OBJECT_INTHE_CYCLE" 1 "OBJECT_EXISTED_IN_PREVIOUS_CYCLE" ;
VAL_ 88 FRS_P1_08_Obj_ID 255 "INVALID" ;
VAL_ 87 FRS_P1_07_Obj_MotionPattern 0 "UNKNOWN" 1 "STATIONARY" 2 "STOPPED" 3 "MOVING" 4 "CROSSL" 5 "ONCOMING" 6 "CROSSR" 7 "HIGHTAR" ;
VAL_ 87 FRS_P1_07_Obj_ValidFlag 0 "OBJECT_INVALID" 1 "OBJECT_VALID" ;
VAL_ 87 FRS_P1_07_Obj_UpdateFlag 0 "NEW_OBJECT_INTHE_CYCLE" 1 "OBJECT_EXISTED_IN_PREVIOUS_CYCLE" ;
VAL_ 87 FRS_P1_07_Obj_ID 255 "INVALID" ;
VAL_ 86 FRS_P1_06_Obj_MotionPattern 0 "UNKNOWN" 1 "STATIONARY" 2 "STOPPED" 3 "MOVING" 4 "CROSSL" 5 "ONCOMING" 6 "CROSSR" 7 "HIGHTAR" ;
VAL_ 86 FRS_P1_06_Obj_ValidFlag 0 "OBJECT_INVALID" 1 "OBJECT_VALID" ;
VAL_ 86 FRS_P1_06_Obj_UpdateFlag 0 "NEW_OBJECT_INTHE_CYCLE" 1 "OBJECT_EXISTED_IN_PREVIOUS_CYCLE" ;
VAL_ 86 FRS_P1_06_Obj_ID 255 "INVALID" ;
VAL_ 85 FRS_P1_05_Obj_MotionPattern 0 "UNKNOWN" 1 "STATIONARY" 2 "STOPPED" 3 "MOVING" 4 "CROSSL" 5 "ONCOMING" 6 "CROSSR" 7 "HIGHTAR" ;
VAL_ 85 FRS_P1_05_Obj_ValidFlag 0 "OBJECT_INVALID" 1 "OBJECT_VALID" ;
VAL_ 85 FRS_P1_05_Obj_UpdateFlag 0 "NEW_OBJECT_INTHE_CYCLE" 1 "OBJECT_EXISTED_IN_PREVIOUS_CYCLE" ;
VAL_ 85 FRS_P1_05_Obj_ID 255 "INVALID" ;
VAL_ 84 FRS_P1_04_Obj_MotionPattern 0 "UNKNOWN" 1 "STATIONARY" 2 "STOPPED" 3 "MOVING" 4 "CROSSL" 5 "ONCOMING" 6 "CROSSR" 7 "HIGHTAR" ;
VAL_ 84 FRS_P1_04_Obj_ValidFlag 0 "OBJECT_INVALID" 1 "OBJECT_VALID" ;
VAL_ 84 FRS_P1_04_Obj_UpdateFlag 0 "NEW_OBJECT_INTHE_CYCLE" 1 "OBJECT_EXISTED_IN_PREVIOUS_CYCLE" ;
VAL_ 84 FRS_P1_04_Obj_ID 255 "INVALID" ;
VAL_ 83 FRS_P1_03_Obj_MotionPattern 0 "UNKNOWN" 1 "STATIONARY" 2 "STOPPED" 3 "MOVING" 4 "CROSSL" 5 "ONCOMING" 6 "CROSSR" 7 "HIGHTAR" ;
VAL_ 83 FRS_P1_03_Obj_ValidFlag 0 "OBJECT_INVALID" 1 "OBJECT_VALID" ;
VAL_ 83 FRS_P1_03_Obj_UpdateFlag 0 "NEW_OBJECT_INTHE_CYCLE" 1 "OBJECT_EXISTED_IN_PREVIOUS_CYCLE" ;
VAL_ 83 FRS_P1_03_Obj_ID 255 "INVALID" ;
VAL_ 82 FRS_P1_02_Obj_MotionPattern 0 "UNKNOWN" 1 "STATIONARY" 2 "STOPPED" 3 "MOVING" 4 "CROSSL" 5 "ONCOMING" 6 "CROSSR" 7 "HIGHTAR" ;
VAL_ 82 FRS_P1_02_Obj_ValidFlag 0 "OBJECT_INVALID" 1 "OBJECT_VALID" ;
VAL_ 82 FRS_P1_02_Obj_UpdateFlag 0 "NEW_OBJECT_INTHE_CYCLE" 1 "OBJECT_EXISTED_IN_PREVIOUS_CYCLE" ;
VAL_ 82 FRS_P1_02_Obj_ID 255 "INVALID" ;
VAL_ 81 FRS_P1_01_Obj_MotionPattern 0 "UNKNOWN" 1 "STATIONARY" 2 "STOPPED" 3 "MOVING" 4 "CROSSL" 5 "ONCOMING" 6 "CROSSR" 7 "HIGHTAR" ;
VAL_ 81 FRS_P1_01_Obj_ValidFlag 0 "OBJECT_INVALID" 1 "OBJECT_VALID" ;
VAL_ 81 FRS_P1_01_Obj_UpdateFlag 0 "NEW_OBJECT_INTHE_CYCLE" 1 "OBJECT_EXISTED_IN_PREVIOUS_CYCLE" ;
VAL_ 81 FRS_P1_01_Obj_ID 255 "INVALID" ;
VAL_ 32 FRS_P2_00_Obj_Type 0 "UNKNOWN" 1 "FOUR_WHEELER" 2 "TWO_WHEELER" 3 "PEDESTRAIN" ;
VAL_ 32 FRS_P2_00_Obj_MeasFlag 0 "OBJECT_MEASURED_INTHIS_CYCLE" 1 "OBJECT_EXTRAPOLATED_THIS_CYCLE" ;
VAL_ 80 FRS_P1_00_Obj_MotionPattern 0 "UNKNOWN" 1 "STATIONARY" 2 "STOPPED" 3 "MOVING" 4 "CROSSL" 5 "ONCOMING" 6 "CROSSR" 7 "HIGHTAR" ;
VAL_ 80 FRS_P1_00_Obj_ValidFlag 0 "OBJECT_INVALID" 1 "OBJECT_VALID" ;
VAL_ 80 FRS_P1_00_Obj_UpdateFlag 0 "NEW_OBJECT_INTHE_CYCLE" 1 "OBJECT_EXISTED_IN_PREVIOUS_CYCLE" ;
VAL_ 80 FRS_P1_00_Obj_ID 255 "INVALID" ;
VAL_ 128 FRS_Status_MisAlign 0 "UNKNOWN" 1 "CALIBRATED" 2 "SENSOR_MISALIGNMENT_DETECTED" 3 "CALIBRATION_IN_PROGRESS" 4 "UNCALIBRATABLE" 5 "RESERVED" 6 "RESERVED" 7 "RESERVED" ;
VAL_ 128 FRS_Status_HWErr 0 "HW_IS_NOT_FAILED" 1 "HE_IS_FAILED" ;
VAL_ 128 FRS_Status_BlkProg 0 "FRS_IS_NOT_BLOCKED" 1 "FRS_IS_BLOCKED" ;
VAL_ 128 FRS_MeasEnabled 0 "MEASUREMENT_DISABLED" 1 "MEASUREMENT_ENABLED" ;
VAL_ 128 FRS_Fail 0 "FRS_RADAR_ISNOT_WORKING" 1 "FRS_RADAR_IS_WORKING" ;
